VERSION ""

NS_ :

BS_:

BU_: PowertrainControlModule AtmosphericSensor SafetyRestraintSystem2 Aftertreatment_2_GasOutlet Aftertreatment_2_GasIntake DieselParticulateFilterControl Turbocharger SafetyRestraintSystem1 CabDisplay2 Aftertreatment_1_GasOutlet Aftertreatment_1_GasIntake OnBoardDataLogger OffBoardDiagnosticTool2 OffBoardDiagnosticTool1 FileServer ParkingBrakeController SeatController2 FanDriveController SteeringColumnUnit CommunicationUnitRadio CommunicationUnitSatellite CommunicationUnitCellular PropulsionBatteryCharger ChassisController2 ChassisController1 EngineValveControl AuxiliaryHeater2 AuxiliaryHeater1 ClutchUnit RampControl InformationSystem1 SuspensionSystemController2 OilSensor VehicleDynamicStability ExhaustEmissionController TransmissionDisplay2 TransmissionDisplay1 ClimateControl2 WaterPumpController RearAxleSteeringController LightingOperatorControl SeatController1 IgnitionController2 IgnitionController1 TirePressureController CabController2 CabController1 PneumaticSystemController SuspensionSystemController1 HydraulicPumpController EnduranceBrakingSystem RetarderExhaustEngine2 OnBoardDiagnosticUnit HeadwayController RetarderExhaustEngine1 CabDisplay1 ManagementComputer VirtualTerminal OffVehicleGateway PowerTakeOffFront HitchControl AuxiliaryValveControl BodyController TractorTrailerBridge1 StarterSystem ElectricalSystem VehicleSecurity VehicleNavigation AerodynamicControl ElectricalChargingSystem ClimateControl1 TripRecorder InstrumentCluster SuspensionDriveAxle2 SuspensionDriveAxle1 SuspensionSteerAxle SteeringController FuelSystem CruiseControl RetarderDriveline RetarderEngine BrakesDriveAxle2 BrakesDriveAxle1 BrakesSystemController BrakesSteerAxle AxleDrive2 AxleDrive1 AxleSteering PowerTakeOff ShiftConsoleSecondary ShiftConsolePrimary Transmission2 Transmission1 Engine2 Engine1

BO_ 2566845694 TIRE: 8 Vector__XXX
 SG_ TirePressThresholdDetection_13 m19 : 61|3@1+ (1,0) [0|7] "" Vector__XXX
 SG_ TirePressThresholdDetection_12 m18 : 61|3@1+ (1,0) [0|7] "" Vector__XXX
 SG_ TirePressThresholdDetection_11 m17 : 61|3@1+ (1,0) [0|7] "" Vector__XXX
 SG_ TirePressThresholdDetection_10 m16 : 61|3@1+ (1,0) [0|7] "" Vector__XXX
 SG_ TirePressThresholdDetection_01 m1 : 61|3@1+ (1,0) [0|7] "" Vector__XXX
 SG_ TirePress_33 m51 : 8|8@1+ (4,0) [0|1000] "kPa" Vector__XXX
 SG_ TirePress_32 m50 : 8|8@1+ (4,0) [0|1000] "kPa" Vector__XXX
 SG_ TirePress_31 m49 : 8|8@1+ (4,0) [0|1000] "kPa" Vector__XXX
 SG_ TirePress_30 m48 : 8|8@1+ (4,0) [0|1000] "kPa" Vector__XXX
 SG_ TirePress_23 m35 : 8|8@1+ (4,0) [0|1000] "kPa" Vector__XXX
 SG_ TirePress_22 m34 : 8|8@1+ (4,0) [0|1000] "kPa" Vector__XXX
 SG_ TirePress_21 m33 : 8|8@1+ (4,0) [0|1000] "kPa" Vector__XXX
 SG_ TirePress_20 m32 : 8|8@1+ (4,0) [0|1000] "kPa" Vector__XXX
 SG_ TirePress_13 m19 : 8|8@1+ (4,0) [0|1000] "kPa" Vector__XXX
 SG_ TirePress_12 m18 : 8|8@1+ (4,0) [0|1000] "kPa" Vector__XXX
 SG_ TirePress_11 m17 : 8|8@1+ (4,0) [0|1000] "kPa" Vector__XXX
 SG_ TirePress_10 m16 : 8|8@1+ (4,0) [0|1000] "kPa" Vector__XXX
 SG_ TireAirLeakageRate_33 m51 : 40|16@1+ (0.1,0) [0|6425.5] "Pa/s" Vector__XXX
 SG_ TireAirLeakageRate_32 m50 : 40|16@1+ (0.1,0) [0|6425.5] "Pa/s" Vector__XXX
 SG_ TireAirLeakageRate_31 m49 : 40|16@1+ (0.1,0) [0|6425.5] "Pa/s" Vector__XXX
 SG_ TireAirLeakageRate_30 m48 : 40|16@1+ (0.1,0) [0|6425.5] "Pa/s" Vector__XXX
 SG_ TireAirLeakageRate_23 m35 : 40|16@1+ (0.1,0) [0|6425.5] "Pa/s" Vector__XXX
 SG_ TireAirLeakageRate_22 m34 : 40|16@1+ (0.1,0) [0|6425.5] "Pa/s" Vector__XXX
 SG_ TireAirLeakageRate_21 m33 : 40|16@1+ (0.1,0) [0|6425.5] "Pa/s" Vector__XXX
 SG_ TireAirLeakageRate_20 m32 : 40|16@1+ (0.1,0) [0|6425.5] "Pa/s" Vector__XXX
 SG_ TireAirLeakageRate_13 m19 : 40|16@1+ (0.1,0) [0|6425.5] "Pa/s" Vector__XXX
 SG_ TireAirLeakageRate_12 m18 : 40|16@1+ (0.1,0) [0|6425.5] "Pa/s" Vector__XXX
 SG_ TireAirLeakageRate_11 m17 : 40|16@1+ (0.1,0) [0|6425.5] "Pa/s" Vector__XXX
 SG_ TireAirLeakageRate_10 m16 : 40|16@1+ (0.1,0) [0|6425.5] "Pa/s" Vector__XXX
 SG_ TireAirLeakageRate_01 m1 : 40|16@1+ (0.1,0) [0|6425.5] "Pa/s" Vector__XXX
 SG_ TireAirLeakageRate_00 m0 : 40|16@1+ (0.1,0) [0|6425.5] "Pa/s" Vector__XXX
 SG_ CTIWheelSensorStatus_33 m51 : 32|2@1+ (1,0) [0|3] "" Vector__XXX
 SG_ CTIWheelSensorStatus_32 m50 : 32|2@1+ (1,0) [0|3] "" Vector__XXX
 SG_ CTIWheelSensorStatus_31 m49 : 32|2@1+ (1,0) [0|3] "" Vector__XXX
 SG_ CTIWheelSensorStatus_30 m48 : 32|2@1+ (1,0) [0|3] "" Vector__XXX
 SG_ CTIWheelSensorStatus_23 m35 : 32|2@1+ (1,0) [0|3] "" Vector__XXX
 SG_ CTIWheelSensorStatus_22 m34 : 32|2@1+ (1,0) [0|3] "" Vector__XXX
 SG_ CTIWheelSensorStatus_21 m33 : 32|2@1+ (1,0) [0|3] "" Vector__XXX
 SG_ CTIWheelSensorStatus_20 m32 : 32|2@1+ (1,0) [0|3] "" Vector__XXX
 SG_ CTIWheelSensorStatus_13 m19 : 32|2@1+ (1,0) [0|3] "" Vector__XXX
 SG_ CTIWheelSensorStatus_12 m18 : 32|2@1+ (1,0) [0|3] "" Vector__XXX
 SG_ CTIWheelSensorStatus_11 m17 : 32|2@1+ (1,0) [0|3] "" Vector__XXX
 SG_ CTIWheelSensorStatus_10 m16 : 32|2@1+ (1,0) [0|3] "" Vector__XXX
 SG_ CTIWheelSensorStatus_01 m1 : 32|2@1+ (1,0) [0|3] "" Vector__XXX
 SG_ CTIWheelEndElectricalFault_33 m51 : 36|2@1+ (1,0) [0|3] "" Vector__XXX
 SG_ CTIWheelEndElectricalFault_32 m50 : 36|2@1+ (1,0) [0|3] "" Vector__XXX
 SG_ CTIWheelEndElectricalFault_31 m49 : 36|2@1+ (1,0) [0|3] "" Vector__XXX
 SG_ CTIWheelEndElectricalFault_30 m48 : 36|2@1+ (1,0) [0|3] "" Vector__XXX
 SG_ CTIWheelEndElectricalFault_23 m35 : 36|2@1+ (1,0) [0|3] "" Vector__XXX
 SG_ CTIWheelEndElectricalFault_22 m34 : 36|2@1+ (1,0) [0|3] "" Vector__XXX
 SG_ CTIWheelEndElectricalFault_21 m33 : 36|2@1+ (1,0) [0|3] "" Vector__XXX
 SG_ CTIWheelEndElectricalFault_20 m32 : 36|2@1+ (1,0) [0|3] "" Vector__XXX
 SG_ CTIWheelEndElectricalFault_13 m19 : 36|2@1+ (1,0) [0|3] "" Vector__XXX
 SG_ CTIWheelEndElectricalFault_12 m18 : 36|2@1+ (1,0) [0|3] "" Vector__XXX
 SG_ CTIWheelEndElectricalFault_11 m17 : 36|2@1+ (1,0) [0|3] "" Vector__XXX
 SG_ CTIWheelEndElectricalFault_10 m16 : 36|2@1+ (1,0) [0|3] "" Vector__XXX
 SG_ CTIWheelEndElectricalFault_01 m1 : 36|2@1+ (1,0) [0|3] "" Vector__XXX
 SG_ CTITireStatus_33 m51 : 34|2@1+ (1,0) [0|3] "" Vector__XXX
 SG_ CTITireStatus_32 m50 : 34|2@1+ (1,0) [0|3] "" Vector__XXX
 SG_ CTITireStatus_31 m49 : 34|2@1+ (1,0) [0|3] "" Vector__XXX
 SG_ CTITireStatus_30 m48 : 34|2@1+ (1,0) [0|3] "" Vector__XXX
 SG_ CTITireStatus_23 m35 : 34|2@1+ (1,0) [0|3] "" Vector__XXX
 SG_ CTITireStatus_22 m34 : 34|2@1+ (1,0) [0|3] "" Vector__XXX
 SG_ CTITireStatus_21 m33 : 34|2@1+ (1,0) [0|3] "" Vector__XXX
 SG_ CTITireStatus_20 m32 : 34|2@1+ (1,0) [0|3] "" Vector__XXX
 SG_ CTITireStatus_13 m19 : 34|2@1+ (1,0) [0|3] "" Vector__XXX
 SG_ CTITireStatus_12 m18 : 34|2@1+ (1,0) [0|3] "" Vector__XXX
 SG_ CTITireStatus_11 m17 : 34|2@1+ (1,0) [0|3] "" Vector__XXX
 SG_ CTITireStatus_10 m16 : 34|2@1+ (1,0) [0|3] "" Vector__XXX
 SG_ CTITireStatus_01 m1 : 34|2@1+ (1,0) [0|3] "" Vector__XXX
 SG_ TireTemp_11 m17 : 16|16@1+ (0.03125,-273) [-273|1735] "°C" Vector__XXX
 SG_ TireTemp_33 m51 : 16|16@1+ (0.03125,-273) [-273|1735] "°C" Vector__XXX
 SG_ TireTemp_32 m50 : 16|16@1+ (0.03125,-273) [-273|1735] "°C" Vector__XXX
 SG_ TireTemp_31 m49 : 16|16@1+ (0.03125,-273) [-273|1735] "°C" Vector__XXX
 SG_ TireTemp_30 m48 : 16|16@1+ (0.03125,-273) [-273|1735] "°C" Vector__XXX
 SG_ TireTemp_23 m35 : 16|16@1+ (0.03125,-273) [-273|1735] "°C" Vector__XXX
 SG_ TireTemp_22 m34 : 16|16@1+ (0.03125,-273) [-273|1735] "°C" Vector__XXX
 SG_ TireTemp_21 m33 : 16|16@1+ (0.03125,-273) [-273|1735] "°C" Vector__XXX
 SG_ TireTemp_20 m32 : 16|16@1+ (0.03125,-273) [-273|1735] "°C" Vector__XXX
 SG_ TireTemp_13 m19 : 16|16@1+ (0.03125,-273) [-273|1735] "°C" Vector__XXX
 SG_ TireTemp_12 m18 : 16|16@1+ (0.03125,-273) [-273|1735] "°C" Vector__XXX
 SG_ TireTemp_10 m16 : 16|16@1+ (0.03125,-273) [-273|1735] "°C" Vector__XXX
 SG_ TireTemp_01 m1 : 16|16@1+ (0.03125,-273) [-273|1735] "°C" Vector__XXX
 SG_ TireTemp_00 m0 : 16|16@1+ (0.03125,-273) [-273|1735] "°C" Vector__XXX
 SG_ TirePressThresholdDetection_33 m51 : 61|3@1+ (1,0) [0|7] "" Vector__XXX
 SG_ TirePressThresholdDetection_32 m50 : 61|3@1+ (1,0) [0|7] "" Vector__XXX
 SG_ TirePressThresholdDetection_31 m49 : 61|3@1+ (1,0) [0|7] "" Vector__XXX
 SG_ TirePressThresholdDetection_30 m48 : 61|3@1+ (1,0) [0|7] "" Vector__XXX
 SG_ TirePressThresholdDetection_23 m35 : 61|3@1+ (1,0) [0|7] "" Vector__XXX
 SG_ TirePressThresholdDetection_22 m34 : 61|3@1+ (1,0) [0|7] "" Vector__XXX
 SG_ TirePressThresholdDetection_21 m33 : 61|3@1+ (1,0) [0|7] "" Vector__XXX
 SG_ TirePressThresholdDetection_20 m32 : 61|3@1+ (1,0) [0|7] "" Vector__XXX
 SG_ TirePressThresholdDetection_00 m0 : 61|3@1+ (1,0) [0|7] "" Vector__XXX
 SG_ TirePress_01 m1 : 8|8@1+ (4,0) [0|1000] "kPa" Vector__XXX
 SG_ TirePress_00 m0 : 8|8@1+ (4,0) [0|1000] "kPa" Vector__XXX
 SG_ CTIWheelSensorStatus_00 m0 : 32|2@1+ (1,0) [0|3] "" Vector__XXX
 SG_ CTIWheelEndElectricalFault_00 m0 : 36|2@1+ (1,0) [0|3] "" Vector__XXX
 SG_ CTITireStatus_00 m0 : 34|2@1+ (1,0) [0|3] "" Vector__XXX
 SG_ TireLocation M : 0|8@1+ (1,0) [0|255] "" Vector__XXX

BO_ 2633939966 TFI: 16 Vector__XXX
 SG_ TripFanOnTimeDueToTheA_CSystem : 96|32@1+ (0.05,0) [0|210554060.75] "h" Vector__XXX
 SG_ TripFanOnTimeDueToAManualSwitch : 64|32@1+ (0.05,0) [0|210554060.75] "h" Vector__XXX
 SG_ TripFanOnTimeDueToTheEngSystem : 32|32@1+ (0.05,0) [0|210554060.75] "h" Vector__XXX
 SG_ TripFanOnTime : 0|32@1+ (0.05,0) [0|210554060.75] "h" Vector__XXX

BO_ 2633939710 TDI: 12 Vector__XXX
 SG_ TripDistanceInTopGear : 64|32@1+ (0.125,0) [0|526385151.875] "km" Vector__XXX
 SG_ TripGearDownDistance : 32|32@1+ (0.125,0) [0|526385151.875] "km" Vector__XXX
 SG_ TripDistanceOnVSL : 0|32@1+ (0.125,0) [0|526385151.875] "km" Vector__XXX

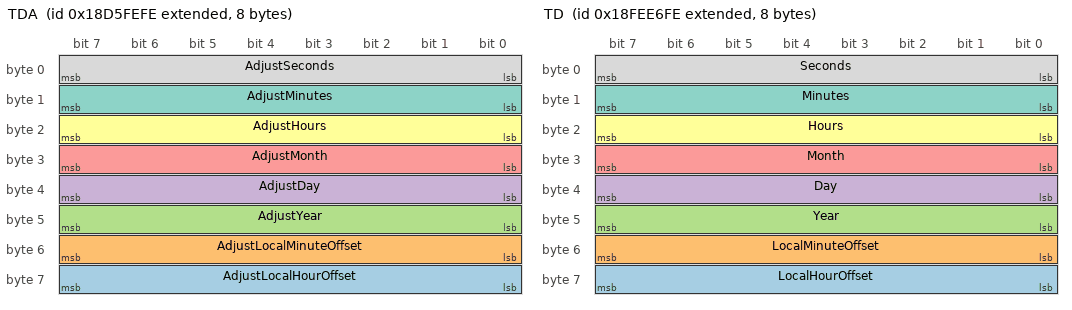
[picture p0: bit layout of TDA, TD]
BO_ 2564161278 TDA: 8 Vector__XXX
 SG_ AdjustLocalHourOffset : 56|8@1+ (1,-125) [-24|23] "h" Vector__XXX
 SG_ AdjustLocalMinuteOffset : 48|8@1+ (1,-125) [-59|59] "min" Vector__XXX
 SG_ AdjustYear : 40|8@1+ (1,1985) [1985|2235] "years" Vector__XXX
 SG_ AdjustDay : 32|8@1+ (0.25,0) [0.25|31.75] "days" Vector__XXX
 SG_ AdjustMonth : 24|8@1+ (1,0) [1|12] "months" Vector__XXX
 SG_ AdjustHours : 16|8@1+ (1,0) [0|23] "h" Vector__XXX
 SG_ AdjustMinutes : 8|8@1+ (1,0) [0|59] "min" Vector__XXX
 SG_ AdjustSeconds : 0|8@1+ (0.25,0) [0|59.75] "s" Vector__XXX

BO_ 2566842110 TD: 8 Vector__XXX
 SG_ LocalHourOffset : 56|8@1+ (1,-125) [-23|23] "h" Vector__XXX
 SG_ LocalMinuteOffset : 48|8@1+ (1,-125) [-59|59] "min" Vector__XXX
 SG_ Year : 40|8@1+ (1,1985) [1985|2235] "years" Vector__XXX
 SG_ Day : 32|8@1+ (0.25,0) [0.25|31.75] "days" Vector__XXX
 SG_ Month : 24|8@1+ (1,0) [1|12] "months" Vector__XXX
 SG_ Hours : 16|8@1+ (1,0) [0|23] "h" Vector__XXX
 SG_ Minutes : 8|8@1+ (1,0) [0|59] "min" Vector__XXX
 SG_ Seconds : 0|8@1+ (0.25,0) [0|59.75] "s" Vector__XXX

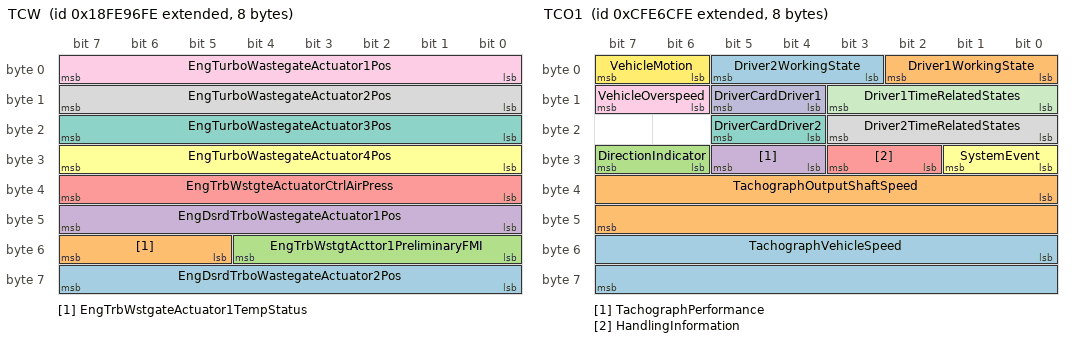
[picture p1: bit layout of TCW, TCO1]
BO_ 2566821630 TCW: 8 Vector__XXX
 SG_ EngDsrdTrboWastegateActuator2Pos : 56|8@1+ (0.4,0) [0|100] "%" Vector__XXX
 SG_ EngTrbWstgateActuator1TempStatus : 53|3@1+ (1,0) [0|7] "" Vector__XXX
 SG_ EngTrbWstgtActtor1PreliminaryFMI : 48|5@1+ (1,0) [0|31] "" Vector__XXX
 SG_ EngDsrdTrboWastegateActuator1Pos : 40|8@1+ (0.4,0) [0|100] "%" Vector__XXX
 SG_ EngTrbWstgteActuatorCtrlAirPress : 32|8@1+ (4,0) [0|1000] "kPa" Vector__XXX
 SG_ EngTurboWastegateActuator4Pos : 24|8@1+ (0.4,0) [0|100] "%" Vector__XXX
 SG_ EngTurboWastegateActuator3Pos : 16|8@1+ (0.4,0) [0|100] "%" Vector__XXX
 SG_ EngTurboWastegateActuator2Pos : 8|8@1+ (0.4,0) [0|100] "%" Vector__XXX
 SG_ EngTurboWastegateActuator1Pos : 0|8@1+ (0.4,0) [0|100] "%" Vector__XXX

BO_ 2365484286 TCO1: 8 Vector__XXX
 SG_ TachographVehicleSpeed : 48|16@1+ (0.00390625,0) [0|250.996] "km/h" Vector__XXX
 SG_ TachographOutputShaftSpeed : 32|16@1+ (0.125,0) [0|8031.875] "rpm" Vector__XXX
 SG_ DirectionIndicator : 30|2@1+ (1,0) [0|3] "" Vector__XXX
 SG_ TachographPerformance : 28|2@1+ (1,0) [0|3] "" Vector__XXX
 SG_ HandlingInformation : 26|2@1+ (1,0) [0|3] "" Vector__XXX
 SG_ SystemEvent : 24|2@1+ (1,0) [0|3] "" Vector__XXX
 SG_ DriverCardDriver2 : 20|2@1+ (1,0) [0|3] "" Vector__XXX
 SG_ Driver2TimeRelatedStates : 16|4@1+ (1,0) [0|15] "" Vector__XXX
 SG_ VehicleOverspeed : 14|2@1+ (1,0) [0|3] "" Vector__XXX
 SG_ DriverCardDriver1 : 12|2@1+ (1,0) [0|3] "" Vector__XXX
 SG_ Driver1TimeRelatedStates : 8|4@1+ (1,0) [0|15] "" Vector__XXX
 SG_ VehicleMotion : 6|2@1+ (1,0) [0|3] "" Vector__XXX
 SG_ Driver2WorkingState : 3|3@1+ (1,0) [0|7] "" Vector__XXX
 SG_ Driver1WorkingState : 0|3@1+ (1,0) [0|7] "" Vector__XXX

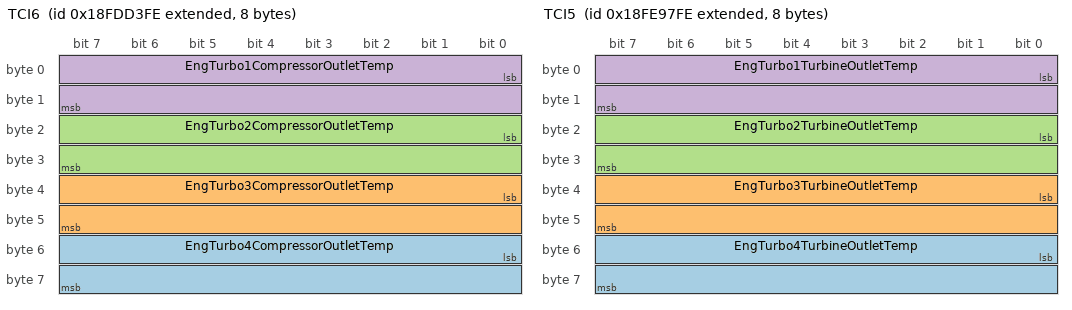
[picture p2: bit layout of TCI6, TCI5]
BO_ 2566771710 TCI6: 8 Vector__XXX
 SG_ EngTurbo4CompressorOutletTemp : 48|16@1+ (0.03125,-273) [-273|1734.96875] "°C" Vector__XXX
 SG_ EngTurbo3CompressorOutletTemp : 32|16@1+ (0.03125,-273) [-273|1734.96875] "°C" Vector__XXX
 SG_ EngTurbo2CompressorOutletTemp : 16|16@1+ (0.03125,-273) [-273|1734.96875] "°C" Vector__XXX
 SG_ EngTurbo1CompressorOutletTemp : 0|16@1+ (0.03125,-273) [-273|1734.96875] "°C" Vector__XXX

BO_ 2566821886 TCI5: 8 Vector__XXX
 SG_ EngTurbo4TurbineOutletTemp : 48|16@1+ (0.03125,-273) [-273|1734.96875] "°C" Vector__XXX
 SG_ EngTurbo3TurbineOutletTemp : 32|16@1+ (0.03125,-273) [-273|1734.96875] "°C" Vector__XXX
 SG_ EngTurbo2TurbineOutletTemp : 16|16@1+ (0.03125,-273) [-273|1734.96875] "°C" Vector__XXX
 SG_ EngTurbo1TurbineOutletTemp : 0|16@1+ (0.03125,-273) [-273|1734.96875] "°C" Vector__XXX

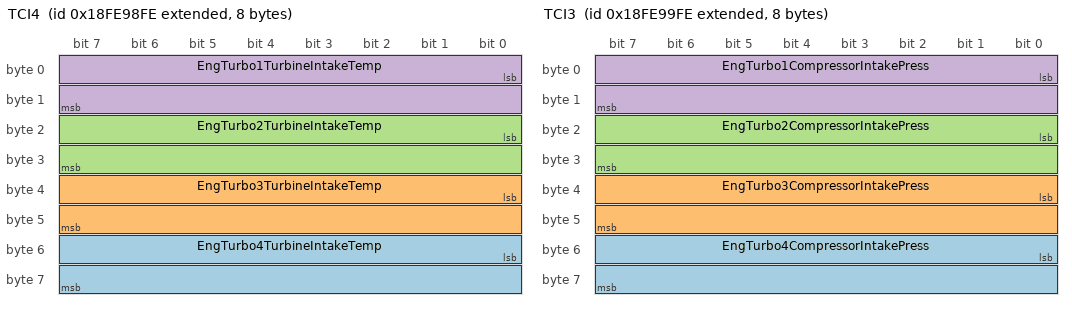
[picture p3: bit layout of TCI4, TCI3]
BO_ 2566822142 TCI4: 8 Vector__XXX
 SG_ EngTurbo4TurbineIntakeTemp : 48|16@1+ (0.03125,-273) [-273|1734.96875] "°C" Vector__XXX
 SG_ EngTurbo3TurbineIntakeTemp : 32|16@1+ (0.03125,-273) [-273|1734.96875] "°C" Vector__XXX
 SG_ EngTurbo2TurbineIntakeTemp : 16|16@1+ (0.03125,-273) [-273|1734.96875] "°C" Vector__XXX
 SG_ EngTurbo1TurbineIntakeTemp : 0|16@1+ (0.03125,-273) [-273|1734.96875] "°C" Vector__XXX

BO_ 2566822398 TCI3: 8 Vector__XXX
 SG_ EngTurbo4CompressorIntakePress : 48|16@1+ (0.0078125,-250) [-250|251.99] "kPa" Vector__XXX
 SG_ EngTurbo3CompressorIntakePress : 32|16@1+ (0.0078125,-250) [-250|251.99] "kPa" Vector__XXX
 SG_ EngTurbo2CompressorIntakePress : 16|16@1+ (0.0078125,-250) [-250|251.99] "kPa" Vector__XXX
 SG_ EngTurbo1CompressorIntakePress : 0|16@1+ (0.0078125,-250) [-250|251.99] "kPa" Vector__XXX

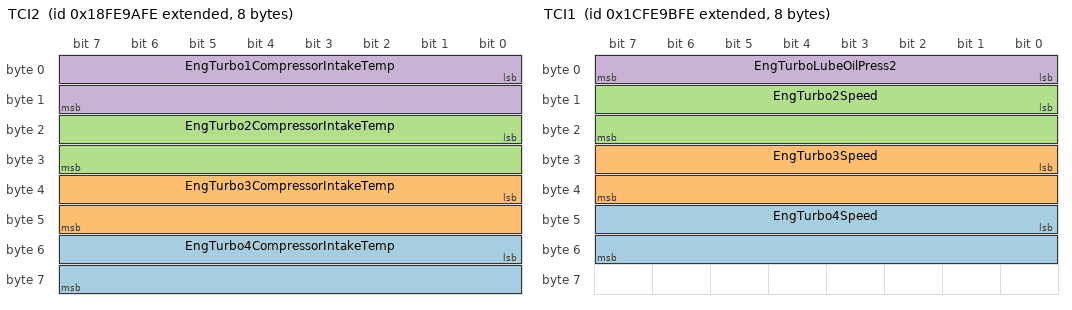
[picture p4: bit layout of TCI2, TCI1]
BO_ 2566822654 TCI2: 8 Vector__XXX
 SG_ EngTurbo4CompressorIntakeTemp : 48|16@1+ (0.03125,-273) [-273|1734.96875] "°C" Vector__XXX
 SG_ EngTurbo3CompressorIntakeTemp : 32|16@1+ (0.03125,-273) [-273|1734.96875] "°C" Vector__XXX
 SG_ EngTurbo2CompressorIntakeTemp : 16|16@1+ (0.03125,-273) [-273|1734.96875] "°C" Vector__XXX
 SG_ EngTurbo1CompressorIntakeTemp : 0|16@1+ (0.03125,-273) [-273|1734.96875] "°C" Vector__XXX

BO_ 2633931774 TCI1: 8 Vector__XXX
 SG_ EngTurbo4Speed : 40|16@1+ (4,0) [0|257020] "rpm" Vector__XXX
 SG_ EngTurbo3Speed : 24|16@1+ (4,0) [0|257020] "rpm" Vector__XXX
 SG_ EngTurbo2Speed : 8|16@1+ (4,0) [0|257020] "rpm" Vector__XXX
 SG_ EngTurboLubeOilPress2 : 0|8@1+ (4,0) [0|1000] "kPa" Vector__XXX

BO_ 2566802430 TCFG2: 8 Vector__XXX
 SG_ TransTorqueLimit : 0|16@1+ (1,0) [0|64255] "Nm" Vector__XXX

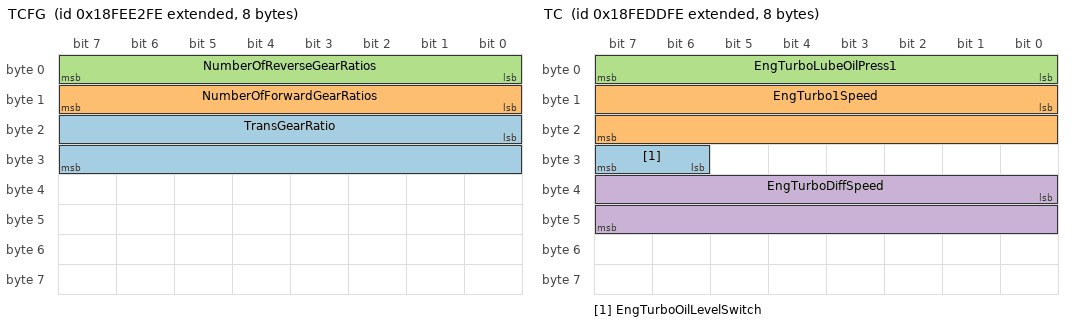
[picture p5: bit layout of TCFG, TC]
BO_ 2566841086 TCFG: 8 Vector__XXX
 SG_ TransGearRatio : 16|16@1+ (0.001,0) [0|64.255] "" Vector__XXX
 SG_ NumberOfForwardGearRatios : 8|8@1+ (1,0) [0|125] "" Vector__XXX
 SG_ NumberOfReverseGearRatios : 0|8@1+ (1,0) [0|125] "" Vector__XXX

BO_ 2348941054 TC1: 8 Vector__XXX
 SG_ TransMode8 : 62|2@1+ (1,0) [0|3] "" Vector__XXX
 SG_ TransMode7 : 60|2@1+ (1,0) [0|3] "" Vector__XXX
 SG_ TransMode6 : 58|2@1+ (1,0) [0|3] "" Vector__XXX
 SG_ TransMode5 : 56|2@1+ (1,0) [0|3] "" Vector__XXX
 SG_ TrnsShftSlectorDisplayModeSwitch : 54|2@1+ (1,0) [0|3] "" Vector__XXX
 SG_ TransRequestedLaunchGear : 50|4@1+ (1,0) [0|15] "" Vector__XXX
 SG_ TransMode4 : 46|2@1+ (1,0) [0|3] "" Vector__XXX
 SG_ TransMode3 : 44|2@1+ (1,0) [0|3] "" Vector__XXX
 SG_ TransMode2 : 42|2@1+ (1,0) [0|3] "" Vector__XXX
 SG_ TransMode1 : 40|2@1+ (1,0) [0|3] "" Vector__XXX
 SG_ TransLoadReductionInhibitRq : 38|2@1+ (1,0) [0|3] "" Vector__XXX
 SG_ DisengageDiffLockRqCentralRear : 36|2@1+ (1,0) [0|3] "" Vector__XXX
 SG_ DisengageDiffLockRqCentralFront : 34|2@1+ (1,0) [0|3] "" Vector__XXX
 SG_ DisengageDiffLockRqCentral : 32|2@1+ (1,0) [0|3] "" Vector__XXX
 SG_ DisengageDiffLockRqRearAxle2 : 30|2@1+ (1,0) [0|3] "" Vector__XXX
 SG_ DisengageDiffLockRqRearAxle1 : 28|2@1+ (1,0) [0|3] "" Vector__XXX
 SG_ DisengageDiffLockRqFrontAxle2 : 26|2@1+ (1,0) [0|3] "" Vector__XXX
 SG_ DisengageDiffLockRqFrontAxle1 : 24|2@1+ (1,0) [0|3] "" Vector__XXX
 SG_ TransRequestedGear : 16|8@1+ (1,-125) [-64|64] "" Vector__XXX
 SG_ RequestedPercentClutchSlip : 8|8@1+ (0.4,0) [0|100] "%" Vector__XXX
 SG_ TransReverseGearShiftInhibitRq : 6|2@1+ (1,0) [0|3] "" Vector__XXX
 SG_ DisengageDrivelineRq : 4|2@1+ (1,0) [0|3] "" Vector__XXX
 SG_ TrnsTrqeConverterLockupDisableRq : 2|2@1+ (1,0) [0|3] "" Vector__XXX
 SG_ TransGearShiftInhibitRq : 0|2@1+ (1,0) [0|3] "" Vector__XXX

BO_ 2566839806 TC: 8 Vector__XXX
 SG_ EngTurboOilLevelSwitch : 30|2@1+ (1,0) [0|3] "" Vector__XXX
 SG_ EngTurbo1Speed : 8|16@1+ (4,0) [0|257020] "rpm" Vector__XXX
 SG_ EngTurboLubeOilPress1 : 0|8@1+ (4,0) [0|1000] "kPa" Vector__XXX
 SG_ EngTurboDiffSpeed : 32|16@1+ (4,0) [0|257020] "rpm" Vector__XXX

BO_ 2633911806 TAVG: 8 Vector__XXX
 SG_ EngTotalAverageFuelEconomy : 16|16@1+ (0.001953125,0) [0|125.498046875] "km/L" Vector__XXX
 SG_ EngTotalAverageFuelRate : 0|16@1+ (0.05,0) [0|3212.75] "L/h" Vector__XXX

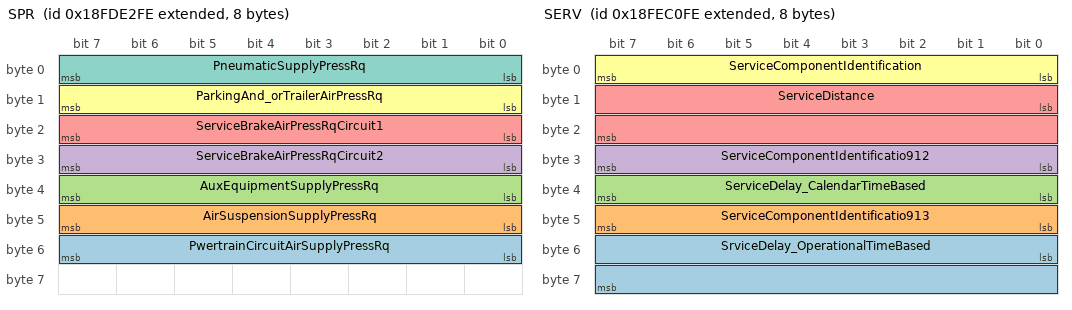
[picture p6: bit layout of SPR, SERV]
BO_ 2566775550 SPR: 8 Vector__XXX
 SG_ PwertrainCircuitAirSupplyPressRq : 48|8@1+ (8,0) [0|2000] "kPa" Vector__XXX
 SG_ AirSuspensionSupplyPressRq : 40|8@1+ (8,0) [0|2000] "kPa" Vector__XXX
 SG_ AuxEquipmentSupplyPressRq : 32|8@1+ (8,0) [0|2000] "kPa" Vector__XXX
 SG_ ServiceBrakeAirPressRqCircuit2 : 24|8@1+ (8,0) [0|2000] "kPa" Vector__XXX
 SG_ ServiceBrakeAirPressRqCircuit1 : 16|8@1+ (8,0) [0|2000] "kPa" Vector__XXX
 SG_ ParkingAnd_orTrailerAirPressRq : 8|8@1+ (8,0) [0|2000] "kPa" Vector__XXX
 SG_ PneumaticSupplyPressRq : 0|8@1+ (8,0) [0|2000] "kPa" Vector__XXX

BO_ 2566819838 SP2: 8 Vector__XXX
 SG_ EngExtlShutdownAirSupplyPress : 0|16@1+ (0.5,0) [0|32127.5] "kPa" Vector__XXX

BO_ 2566838785 SOFT: 12 Vector__XXX
 SG_ feda10 : 88|8@1+ (1,0) [0|0] "" Vector__XXX
 SG_ feda09 : 80|8@1+ (1,0) [0|0] "" Vector__XXX
 SG_ feda08 : 72|8@1+ (1,0) [0|0] "" Vector__XXX
 SG_ feda07 : 64|8@1+ (1,0) [0|0] "" Vector__XXX
 SG_ feda06 : 56|8@1+ (1,0) [0|0] "" Vector__XXX
 SG_ feda05 : 48|8@1+ (1,0) [0|0] "" Vector__XXX
 SG_ feda04 : 40|8@1+ (1,0) [0|0] "" Vector__XXX
 SG_ feda03 : 32|8@1+ (1,0) [0|0] "" Vector__XXX
 SG_ feda02 : 24|8@1+ (1,0) [0|0] "" Vector__XXX
 SG_ feda01 : 16|8@1+ (1,0) [0|0] "" Vector__XXX
 SG_ NmbrOfSftwreIdentificationFields : 0|8@1+ (1,0) [0|125] "steps" Vector__XXX
 SG_ SoftwareIdentification : 8|8@1+ (1,0) [0|255] "" Vector__XXX

BO_ 2566841598 SHUTDN: 8 Vector__XXX
 SG_ ClntLvlEngPrtctionShutdownStatus : 60|2@1+ (1,0) [0|3] "" Vector__XXX
 SG_ PTOShutdownHasShutdownEng : 58|2@1+ (1,0) [0|3] "" Vector__XXX
 SG_ EngAirShutoffStatus : 56|2@1+ (1,0) [0|3] "" Vector__XXX
 SG_ EngOverspeedTest : 54|2@1+ (1,0) [0|3] "" Vector__XXX
 SG_ EngAirShutoffCmdStatus : 52|2@1+ (1,0) [0|3] "" Vector__XXX
 SG_ EngAlarmOutputCmdStatus : 50|2@1+ (1,0) [0|3] "" Vector__XXX
 SG_ EngAlarmAcknowledge : 48|2@1+ (1,0) [0|3] "" Vector__XXX
 SG_ EngProtectionSystemConfig : 46|2@1+ (1,0) [0|3] "" Vector__XXX
 SG_ EngProtectionSystemTimerState : 38|2@1+ (1,0) [0|3] "" Vector__XXX
 SG_ EngProtectionSystemTimerOverride : 36|2@1+ (1,0) [0|3] "" Vector__XXX
 SG_ EngPrtctnSystmApprachingShutdown : 34|2@1+ (1,0) [0|3] "" Vector__XXX
 SG_ EngPrtectionSystemHasShutdownEng : 32|2@1+ (1,0) [0|3] "" Vector__XXX
 SG_ EngWaitToStartLamp : 24|2@1+ (1,0) [0|3] "" Vector__XXX
 SG_ RefrigerantHighPressSwitch : 20|2@1+ (1,0) [0|3] "" Vector__XXX
 SG_ RefrigerantLowPressSwitch : 18|2@1+ (1,0) [0|3] "" Vector__XXX
 SG_ A_CHighPressFanSwitch : 16|2@1+ (1,0) [0|3] "" Vector__XXX
 SG_ EngIdleShutdownTimerFunction : 14|2@1+ (1,0) [0|3] "" Vector__XXX
 SG_ EngIdleShutdownTimerState : 6|2@1+ (1,0) [0|3] "" Vector__XXX
 SG_ EngIdleShutdownTimerOverride : 4|2@1+ (1,0) [0|3] "" Vector__XXX
 SG_ EngIdleShutdownDriverAlertMode : 2|2@1+ (1,0) [0|3] "" Vector__XXX
 SG_ EngIdleShutdownHasShutdownEng : 0|2@1+ (1,0) [0|3] "" Vector__XXX

BO_ 2365459710 WSMEM: 8 Vector__XXX
 SG_ VehicleSystem5 m5 : 49|7@1+ (1,0) [0|127] "" Vector__XXX
 SG_ VehicleSystem4 m4 : 49|7@1+ (1,0) [0|127] "" Vector__XXX
 SG_ VehicleSystem3 m3 : 49|7@1+ (1,0) [0|127] "" Vector__XXX
 SG_ VehicleSystem2 m2 : 49|7@1+ (1,0) [0|127] "" Vector__XXX
 SG_ VehicleSystem1 m1 : 49|7@1+ (1,0) [0|127] "" Vector__XXX
 SG_ ArbitraryAddressCapable : 63|1@1+ (1,0) [0|1] "" Vector__XXX
 SG_ IndustryGroup M : 60|3@1+ (1,0) [0|7] "" Vector__XXX
 SG_ VehicleSystemInstance : 56|4@1+ (1,0) [0|15] "" Vector__XXX
 SG_ VehicleSystem m0 : 49|7@1+ (1,0) [0|127] "" Vector__XXX
 SG_ ECUInstance : 32|3@1+ (1,0) [0|7] "" Vector__XXX
 SG_ FunctionInstance : 35|5@1+ (1,0) [0|31] "" Vector__XXX
 SG_ Function : 40|8@1+ (1,0) [0|255] "" Vector__XXX
 SG_ ManufacturerCode : 21|11@1+ (1,0) [0|2047] "" Vector__XXX
 SG_ IdentityNumber : 0|21@1+ (1,0) [0|2097152] "" Vector__XXX

BO_ 2566832382 SERV: 8 Vector__XXX
 SG_ SrviceDelay_OperationalTimeBased : 48|16@1+ (1,-32127) [-32127|32128] "h" Vector__XXX
 SG_ ServiceComponentIdentificatio913 : 40|8@1+ (1,0) [0|250] "ID" Vector__XXX
 SG_ ServiceDelay_CalendarTimeBased : 32|8@1+ (1,-125) [-125|125] "weeks" Vector__XXX
 SG_ ServiceComponentIdentificatio912 : 24|8@1+ (1,0) [0|250] "ID" Vector__XXX
 SG_ ServiceDistance : 8|16@1+ (5,-160635) [-160635|160640] "km" Vector__XXX
 SG_ ServiceComponentIdentification : 0|8@1+ (1,0) [0|250] "ID" Vector__XXX

BO_ 2633928446 S2: 8 Vector__XXX
 SG_ TimeSinceLastService : 8|16@1+ (1,-32127) [-32127|32128] "h" Vector__XXX
 SG_ ServiceComponentIdentification : 0|8@1+ (1,0) [0|250] "ID" Vector__XXX

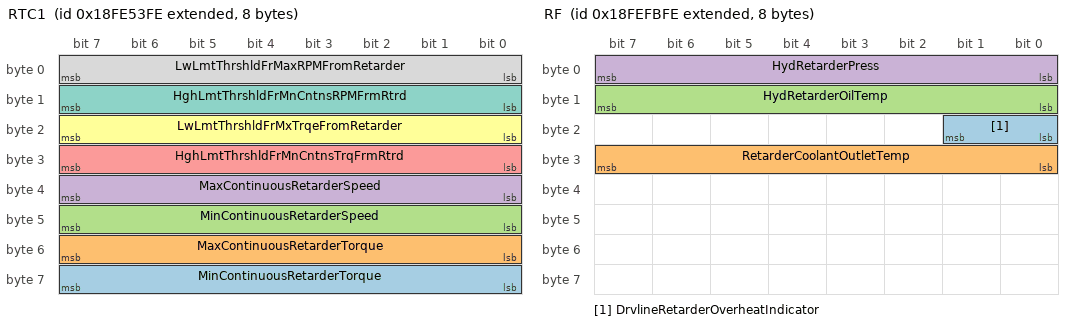
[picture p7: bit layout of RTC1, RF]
BO_ 2566804478 RTC1: 8 Vector__XXX
 SG_ MinContinuousRetarderTorque : 56|8@1+ (1,-125) [-125|125] "%" Vector__XXX
 SG_ MaxContinuousRetarderTorque : 48|8@1+ (1,-125) [-125|125] "%" Vector__XXX
 SG_ MinContinuousRetarderSpeed : 40|8@1+ (32,0) [0|8000] "rpm" Vector__XXX
 SG_ MaxContinuousRetarderSpeed : 32|8@1+ (32,0) [0|8000] "rpm" Vector__XXX
 SG_ HghLmtThrshldFrMnCntnsTrqFrmRtrd : 24|8@1+ (1,-125) [-125|125] "%" Vector__XXX
 SG_ LwLmtThrshldFrMxTrqeFromRetarder : 16|8@1+ (1,-125) [-125|125] "%" Vector__XXX
 SG_ HghLmtThrshldFrMnCntnsRPMFrmRtrd : 8|8@1+ (32,0) [0|8000] "rpm" Vector__XXX
 SG_ LwLmtThrshldFrMaxRPMFromRetarder : 0|8@1+ (32,0) [0|8000] "rpm" Vector__XXX

BO_ 2566847486 RF: 8 Vector__XXX
 SG_ DrvlineRetarderOverheatIndicator : 16|2@1+ (1,0) [0|3] "" Vector__XXX
 SG_ RetarderCoolantOutletTemp : 24|8@1+ (1,-40) [-40|210] "°C" Vector__XXX
 SG_ HydRetarderOilTemp : 8|8@1+ (1,-40) [-40|210] "°C" Vector__XXX
 SG_ HydRetarderPress : 0|8@1+ (16,0) [0|4000] "kPa" Vector__XXX

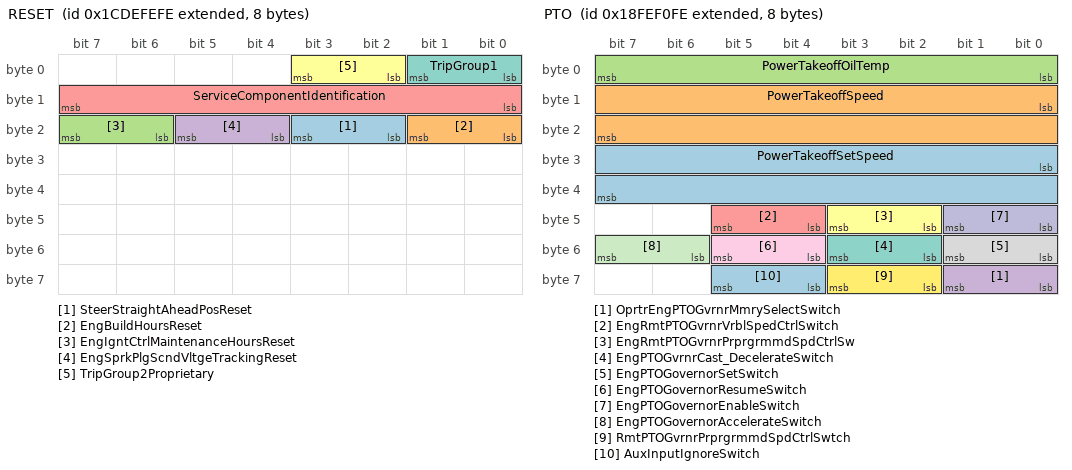
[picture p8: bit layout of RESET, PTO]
BO_ 2631859966 RESET: 8 Vector__XXX
 SG_ SteerStraightAheadPosReset : 18|2@1+ (1,0) [0|3] "" Vector__XXX
 SG_ EngBuildHoursReset : 16|2@1+ (1,0) [0|3] "" Vector__XXX
 SG_ EngIgntCtrlMaintenanceHoursReset : 22|2@1+ (1,0) [0|3] "" Vector__XXX
 SG_ EngSprkPlgScndVltgeTrackingReset : 20|2@1+ (1,0) [0|3] "" Vector__XXX
 SG_ ServiceComponentIdentification : 8|8@1+ (1,0) [0|250] "ID" Vector__XXX
 SG_ TripGroup2Proprietary : 2|2@1+ (1,0) [0|3] "" Vector__XXX
 SG_ TripGroup1 : 0|2@1+ (1,0) [0|3] "" Vector__XXX

BO_ 2566840830 RC: 19 Vector__XXX
 SG_ PercentTorqueAtPeakTorquePoint5 : 144|8@1+ (1,-125) [-125|0] "%" Vector__XXX
 SG_ ReferenceRetarderTorque : 128|16@1+ (1,0) [0|64255] "Nm" Vector__XXX
 SG_ RetarderSpeedAtPeakTorquePoint5 : 112|16@1+ (0.125,0) [0|8031.875] "rpm" Vector__XXX
 SG_ PercentTorqueAtPoint4 : 104|8@1+ (1,-125) [-125|0] "%" Vector__XXX
 SG_ RetarderSpeedAtPoint4 : 88|16@1+ (0.125,0) [0|8031.875] "rpm" Vector__XXX
 SG_ PercentTorqueAtPoint3 : 80|8@1+ (1,-125) [-125|0] "%" Vector__XXX
 SG_ RetarderSpeedAtPoint3 : 64|16@1+ (0.125,0) [0|8031.875] "rpm" Vector__XXX
 SG_ PercentTorqueAtMaxSpeedPoint2 : 56|8@1+ (1,-125) [-125|0] "%" Vector__XXX
 SG_ MaxRetarderSpeedPoint2 : 40|16@1+ (0.125,0) [0|8031.875] "rpm" Vector__XXX
 SG_ PercentTorqueAtIdlePoint1 : 32|8@1+ (1,-125) [-125|0] "%" Vector__XXX
 SG_ RetarderSpeedAtIdlePoint1 : 16|16@1+ (0.125,0) [0|8031.875] "rpm" Vector__XXX
 SG_ RetarderCtrlMethod : 8|8@1+ (1,0) [0|250] "steps" Vector__XXX
 SG_ RetarderLocation : 4|4@1+ (1,0) [0|15] "" Vector__XXX
 SG_ RetarderType : 0|4@1+ (1,0) [0|15] "" Vector__XXX

BO_ 2633930238 RBI: 8 Vector__XXX
 SG_ EngOperationTimeSinceRebuild : 0|32@1+ (1,0) [0|4211081215] "s" Vector__XXX

BO_ 2566844670 PTO: 8 Vector__XXX
 SG_ PowerTakeoffSetSpeed : 24|16@1+ (0.125,0) [0|8031.875] "rpm" Vector__XXX
 SG_ PowerTakeoffSpeed : 8|16@1+ (0.125,0) [0|8031.875] "rpm" Vector__XXX
 SG_ PowerTakeoffOilTemp : 0|8@1+ (1,-40) [-40|210] "°C" Vector__XXX
 SG_ OprtrEngPTOGvrnrMmrySelectSwitch : 56|2@1+ (1,0) [0|3] "" Vector__XXX
 SG_ EngRmtPTOGvrnrVrblSpedCtrlSwitch : 44|2@1+ (1,0) [0|3] "" Vector__XXX
 SG_ EngRmtPTOGvrnrPrprgrmmdSpdCtrlSw : 42|2@1+ (1,0) [0|3] "" Vector__XXX
 SG_ EngPTOGvrnrCast_DecelerateSwitch : 50|2@1+ (1,0) [0|3] "" Vector__XXX
 SG_ EngPTOGovernorSetSwitch : 48|2@1+ (1,0) [0|3] "" Vector__XXX
 SG_ EngPTOGovernorResumeSwitch : 52|2@1+ (1,0) [0|3] "" Vector__XXX
 SG_ EngPTOGovernorEnableSwitch : 40|2@1+ (1,0) [0|3] "" Vector__XXX
 SG_ EngPTOGovernorAccelerateSwitch : 54|2@1+ (1,0) [0|3] "" Vector__XXX
 SG_ RmtPTOGvrnrPrprgrmmdSpdCtrlSwtch : 58|2@1+ (1,0) [0|3] "" Vector__XXX
 SG_ AuxInputIgnoreSwitch : 60|2@1+ (1,0) [0|3] "" Vector__XXX

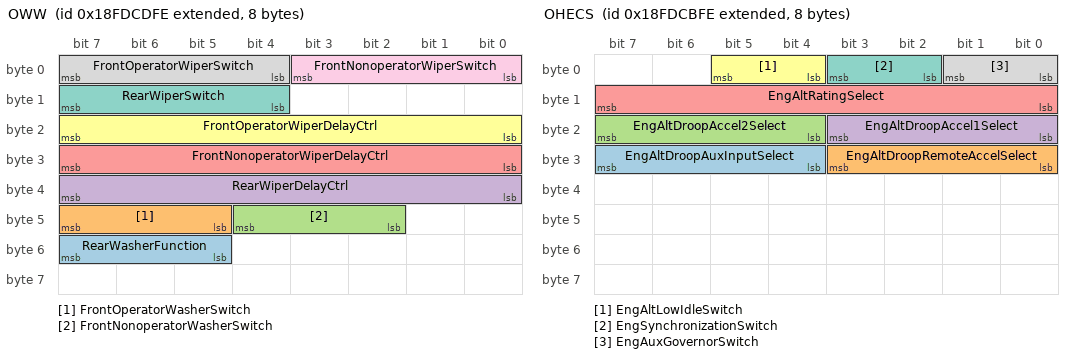
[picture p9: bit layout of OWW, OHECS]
BO_ 2566770174 OWW: 8 Vector__XXX
 SG_ RearWasherFunction : 53|3@1+ (1,0) [0|7] "" Vector__XXX
 SG_ FrontOperatorWasherSwitch : 45|3@1+ (1,0) [0|7] "" Vector__XXX
 SG_ FrontNonoperatorWasherSwitch : 42|3@1+ (1,0) [0|7] "" Vector__XXX
 SG_ RearWiperDelayCtrl : 32|8@1+ (0.4,0) [0|100] "%" Vector__XXX
 SG_ FrontNonoperatorWiperDelayCtrl : 24|8@1+ (0.4,0) [0|100] "%" Vector__XXX
 SG_ FrontOperatorWiperDelayCtrl : 16|8@1+ (0.4,0) [0|100] "%" Vector__XXX
 SG_ RearWiperSwitch : 12|4@1+ (1,0) [0|15] "" Vector__XXX
 SG_ FrontOperatorWiperSwitch : 4|4@1+ (1,0) [0|15] "" Vector__XXX
 SG_ FrontNonoperatorWiperSwitch : 0|4@1+ (1,0) [0|15] "" Vector__XXX

BO_ 2566769662 OHECS: 8 Vector__XXX
 SG_ EngAltDroopAuxInputSelect : 28|4@1+ (1,0) [0|15] "" Vector__XXX
 SG_ EngAltDroopRemoteAccelSelect : 24|4@1+ (1,0) [0|15] "" Vector__XXX
 SG_ EngAltDroopAccel2Select : 20|4@1+ (1,0) [0|15] "" Vector__XXX
 SG_ EngAltDroopAccel1Select : 16|4@1+ (1,0) [0|15] "" Vector__XXX
 SG_ EngAltRatingSelect : 8|8@1+ (1,0) [0|255] "" Vector__XXX
 SG_ EngAltLowIdleSwitch : 4|2@1+ (1,0) [0|3] "" Vector__XXX
 SG_ EngSynchronizationSwitch : 2|2@1+ (1,0) [0|3] "" Vector__XXX
 SG_ EngAuxGovernorSwitch : 0|2@1+ (1,0) [0|3] "" Vector__XXX

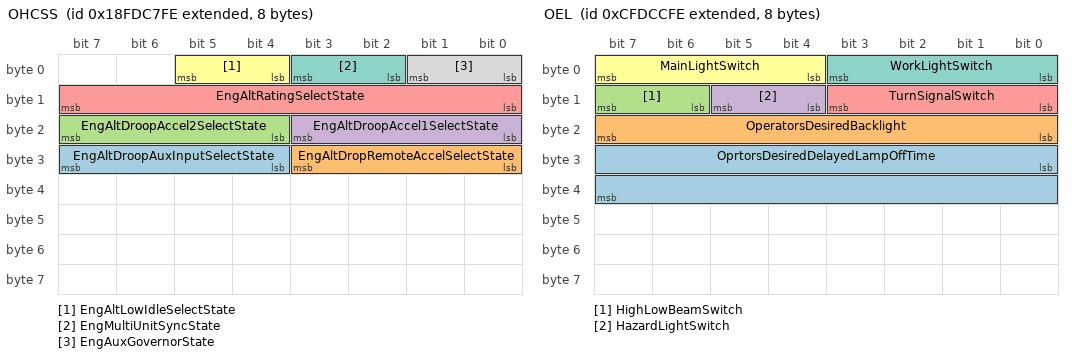
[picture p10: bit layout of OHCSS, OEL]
BO_ 2566768638 OHCSS: 8 Vector__XXX
 SG_ EngAltDroopAuxInputSelectState : 28|4@1+ (1,0) [0|15] "" Vector__XXX
 SG_ EngAltDropRemoteAccelSelectState : 24|4@1+ (1,0) [0|15] "" Vector__XXX
 SG_ EngAltDroopAccel2SelectState : 20|4@1+ (1,0) [0|15] "" Vector__XXX
 SG_ EngAltDroopAccel1SelectState : 16|4@1+ (1,0) [0|15] "" Vector__XXX
 SG_ EngAltRatingSelectState : 8|8@1+ (1,0) [0|255] "" Vector__XXX
 SG_ EngAltLowIdleSelectState : 4|2@1+ (1,0) [0|3] "" Vector__XXX
 SG_ EngMultiUnitSyncState : 2|2@1+ (1,0) [0|3] "" Vector__XXX
 SG_ EngAuxGovernorState : 0|2@1+ (1,0) [0|3] "" Vector__XXX

BO_ 2365443326 OEL: 8 Vector__XXX
 SG_ OprtorsDesiredDelayedLampOffTime : 24|16@1+ (1,0) [0|64255] "s" Vector__XXX
 SG_ OperatorsDesiredBacklight : 16|8@1+ (0.4,0) [0|100] "%" Vector__XXX
 SG_ HighLowBeamSwitch : 14|2@1+ (1,0) [0|3] "" Vector__XXX
 SG_ HazardLightSwitch : 12|2@1+ (1,0) [0|3] "" Vector__XXX
 SG_ TurnSignalSwitch : 8|4@1+ (1,0) [0|15] "" Vector__XXX
 SG_ MainLightSwitch : 4|4@1+ (1,0) [0|15] "" Vector__XXX
 SG_ WorkLightSwitch : 0|4@1+ (1,0) [0|15] "" Vector__XXX

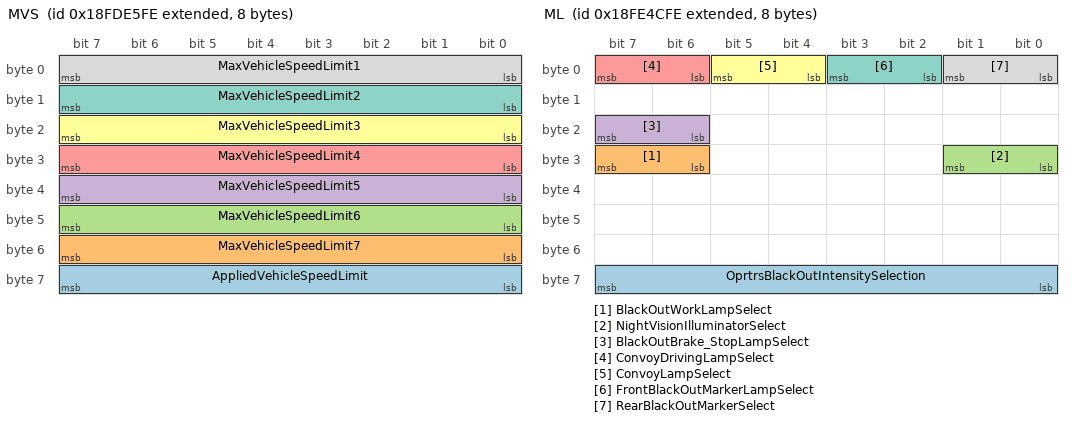
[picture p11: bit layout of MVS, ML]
BO_ 2566776318 MVS: 8 Vector__XXX
 SG_ AppliedVehicleSpeedLimit : 56|8@1+ (1,0) [0|250] "km/h" Vector__XXX
 SG_ MaxVehicleSpeedLimit7 : 48|8@1+ (1,0) [0|250] "km/h" Vector__XXX
 SG_ MaxVehicleSpeedLimit6 : 40|8@1+ (1,0) [0|250] "km/h" Vector__XXX
 SG_ MaxVehicleSpeedLimit5 : 32|8@1+ (1,0) [0|250] "km/h" Vector__XXX
 SG_ MaxVehicleSpeedLimit4 : 24|8@1+ (1,0) [0|250] "km/h" Vector__XXX
 SG_ MaxVehicleSpeedLimit3 : 16|8@1+ (1,0) [0|250] "km/h" Vector__XXX
 SG_ MaxVehicleSpeedLimit2 : 8|8@1+ (1,0) [0|250] "km/h" Vector__XXX
 SG_ MaxVehicleSpeedLimit1 : 0|8@1+ (1,0) [0|250] "km/h" Vector__XXX

BO_ 2566802686 ML: 8 Vector__XXX
 SG_ OprtrsBlackOutIntensitySelection : 56|8@1+ (0.4,0) [0|100] "%" Vector__XXX
 SG_ BlackOutWorkLampSelect : 30|2@1+ (1,0) [0|3] "" Vector__XXX
 SG_ NightVisionIlluminatorSelect : 24|2@1+ (1,0) [0|3] "" Vector__XXX
 SG_ BlackOutBrake_StopLampSelect : 22|2@1+ (1,0) [0|3] "" Vector__XXX
 SG_ ConvoyDrivingLampSelect : 6|2@1+ (1,0) [0|3] "" Vector__XXX
 SG_ ConvoyLampSelect : 4|2@1+ (1,0) [0|3] "" Vector__XXX
 SG_ FrontBlackOutMarkerLampSelect : 2|2@1+ (1,0) [0|3] "" Vector__XXX
 SG_ RearBlackOutMarkerSelect : 0|2@1+ (1,0) [0|3] "" Vector__XXX

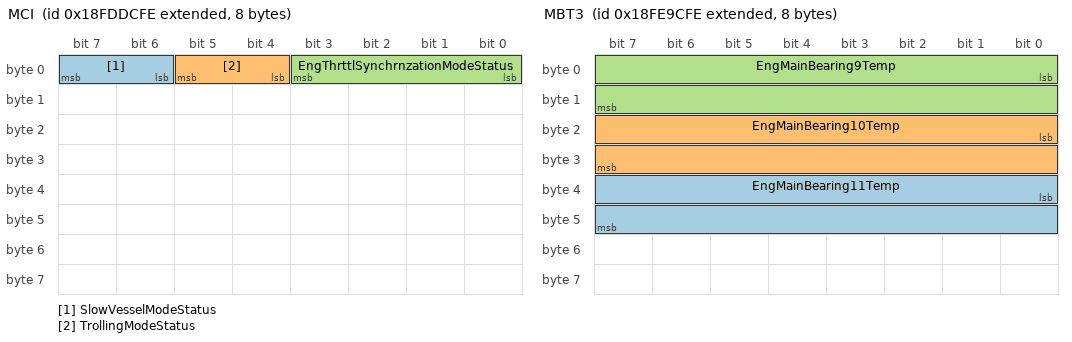
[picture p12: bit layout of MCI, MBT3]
BO_ 2566774014 MCI: 8 Vector__XXX
 SG_ SlowVesselModeStatus : 6|2@1+ (1,0) [0|3] "" Vector__XXX
 SG_ TrollingModeStatus : 4|2@1+ (1,0) [0|3] "" Vector__XXX
 SG_ EngThrttlSynchrnzationModeStatus : 0|4@1+ (1,0) [0|15] "" Vector__XXX

BO_ 2566823166 MBT3: 8 Vector__XXX
 SG_ EngMainBearing11Temp : 32|16@1+ (0.03125,-273) [-273|1734.96875] "°C" Vector__XXX
 SG_ EngMainBearing10Temp : 16|16@1+ (0.03125,-273) [-273|1734.96875] "°C" Vector__XXX
 SG_ EngMainBearing9Temp : 0|16@1+ (0.03125,-273) [-273|1734.96875] "°C" Vector__XXX

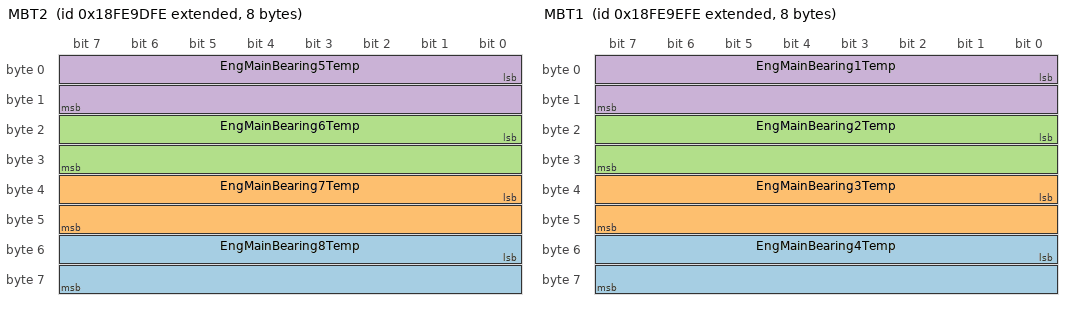
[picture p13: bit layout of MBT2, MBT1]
BO_ 2566823422 MBT2: 8 Vector__XXX
 SG_ EngMainBearing8Temp : 48|16@1+ (0.03125,-273) [-273|1734.96875] "°C" Vector__XXX
 SG_ EngMainBearing7Temp : 32|16@1+ (0.03125,-273) [-273|1734.96875] "°C" Vector__XXX
 SG_ EngMainBearing6Temp : 16|16@1+ (0.03125,-273) [-273|1734.96875] "°C" Vector__XXX
 SG_ EngMainBearing5Temp : 0|16@1+ (0.03125,-273) [-273|1734.96875] "°C" Vector__XXX

BO_ 2566823678 MBT1: 8 Vector__XXX
 SG_ EngMainBearing4Temp : 48|16@1+ (0.03125,-273) [-273|1734.96875] "°C" Vector__XXX
 SG_ EngMainBearing3Temp : 32|16@1+ (0.03125,-273) [-273|1734.96875] "°C" Vector__XXX
 SG_ EngMainBearing2Temp : 16|16@1+ (0.03125,-273) [-273|1734.96875] "°C" Vector__XXX
 SG_ EngMainBearing1Temp : 0|16@1+ (0.03125,-273) [-273|1734.96875] "°C" Vector__XXX

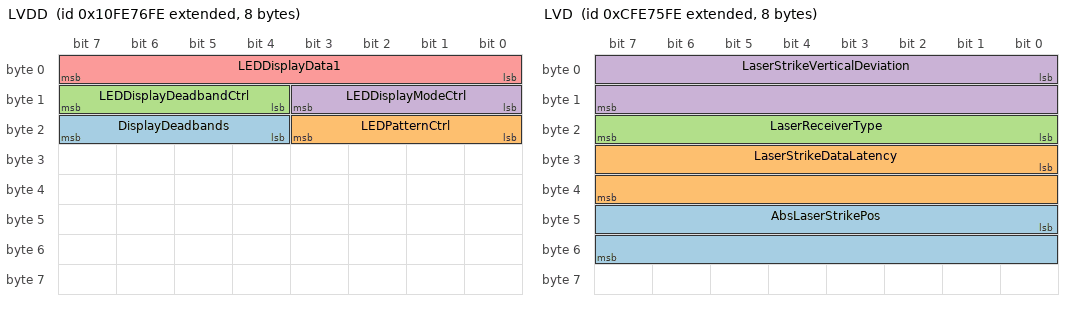
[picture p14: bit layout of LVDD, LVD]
BO_ 2432595710 LVDD: 8 Vector__XXX
 SG_ DisplayDeadbands : 20|4@1+ (1,0) [0|15] "" Vector__XXX
 SG_ LEDPatternCtrl : 16|4@1+ (1,0) [0|15] "" Vector__XXX
 SG_ LEDDisplayDeadbandCtrl : 12|4@1+ (1,0) [0|15] "" Vector__XXX
 SG_ LEDDisplayModeCtrl : 8|4@1+ (1,0) [0|15] "" Vector__XXX
 SG_ LEDDisplayData1 : 0|8@1+ (1,0) [0|255] "" Vector__XXX

BO_ 2365486590 LVD: 8 Vector__XXX
 SG_ AbsLaserStrikePos : 40|16@1+ (0.1,0) [0|6425.5] "mm" Vector__XXX
 SG_ LaserStrikeDataLatency : 24|16@1+ (5.12E-005,0) [0|3.289856] "s" Vector__XXX
 SG_ LaserReceiverType : 16|8@1+ (1,0) [0|250] "" Vector__XXX
 SG_ LaserStrikeVerticalDeviation : 0|16@1+ (0.1,-3200) [-3200|3225.5] "mm" Vector__XXX

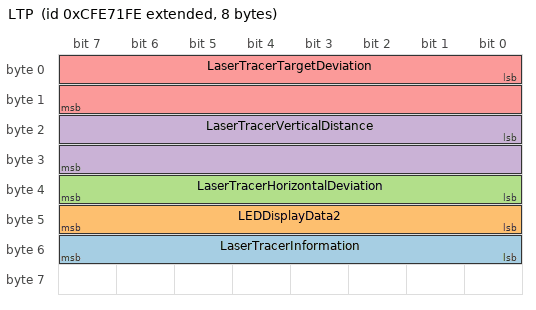
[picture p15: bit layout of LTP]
BO_ 2365485566 LTP: 8 Vector__XXX
 SG_ LaserTracerInformation : 48|8@1+ (1,0) [0|255] "" Vector__XXX
 SG_ LEDDisplayData2 : 40|8@1+ (1,0) [0|255] "" Vector__XXX
 SG_ LaserTracerHorizontalDeviation : 32|8@1+ (1,0) [0|200] "%" Vector__XXX
 SG_ LaserTracerVerticalDistance : 16|16@1+ (0.1,0) [0|6400] "mm" Vector__XXX
 SG_ LaserTracerTargetDeviation : 0|16@1+ (0.1,-3200) [-3200|3225.5] "mm" Vector__XXX

BO_ 2633939454 LTFI: 22 Vector__XXX
 SG_ TripDriveFuelEconomy : 160|16@1+ (0.001953125,0) [0|125.498046875] "km/L" Vector__XXX
 SG_ TripCruiseFuelUsed : 128|32@1+ (0.5,0) [0|2105540607.5] "L" Vector__XXX
 SG_ TripVehicleIdleFuelUsed : 96|32@1+ (0.5,0) [0|2105540607.5] "L" Vector__XXX
 SG_ TripPTOGovernorNonmovingFuelUsed : 64|32@1+ (0.5,0) [0|2105540607.5] "L" Vector__XXX
 SG_ TripPTOGovernorMovingFuelUsed : 32|32@1+ (0.5,0) [0|2105540607.5] "L" Vector__XXX
 SG_ TripDriveFuelUsed : 0|32@1+ (0.5,0) [0|2105540607.5] "L" Vector__XXX

BO_ 2365486334 LSP: 8 Vector__XXX
 SG_ BldeHeightSetPointHighResolution : 16|32@1+ (1E-007,-209.7152) [-209.7152|209.7152] "m" Vector__XXX
 SG_ ModifyLevelingSystemSetPoint : 0|16@1+ (0.1,-3200) [-3200|3225.5] "mm" Vector__XXX

CM_ BO_ 2566845694 "Tire Condition Message
NOTE–Message has to repeated as necessary to transmit all available information.  This method of location identification requires individual SPNs to be assigned to report failures specific to each individual component (I.e ...";
CM_ SG_ 2566845694 TirePressThresholdDetection_13 "Signal indicating the pressure level of the tire.";
CM_ SG_ 2566845694 TirePressThresholdDetection_12 "Signal indicating the pressure level of the tire.";
CM_ SG_ 2566845694 TirePressThresholdDetection_11 "Signal indicating the pressure level of the tire.";
CM_ SG_ 2566845694 TirePressThresholdDetection_10 "Signal indicating the pressure level of the tire.";
CM_ SG_ 2566845694 TirePressThresholdDetection_01 "Signal indicating the pressure level of the tire.";
CM_ SG_ 2566845694 TirePress_33 "Pressure at which air is contained in cavity formed by tire and rim.";
CM_ SG_ 2566845694 TirePress_32 "Pressure at which air is contained in cavity formed by tire and rim.";
CM_ SG_ 2566845694 TirePress_31 "Pressure at which air is contained in cavity formed by tire and rim.";
CM_ SG_ 2566845694 TirePress_30 "Pressure at which air is contained in cavity formed by tire and rim.";
CM_ SG_ 2566845694 TirePress_23 "Pressure at which air is contained in cavity formed by tire and rim.";
CM_ SG_ 2566845694 TirePress_22 "Pressure at which air is contained in cavity formed by tire and rim.";
CM_ SG_ 2566845694 TirePress_21 "Pressure at which air is contained in cavity formed by tire and rim.";
CM_ SG_ 2566845694 TirePress_20 "Pressure at which air is contained in cavity formed by tire and rim.";
CM_ SG_ 2566845694 TirePress_13 "Pressure at which air is contained in cavity formed by tire and rim.";
CM_ SG_ 2566845694 TirePress_12 "Pressure at which air is contained in cavity formed by tire and rim.";
CM_ SG_ 2566845694 TirePress_11 "Pressure at which air is contained in cavity formed by tire and rim.";
CM_ SG_ 2566845694 TirePress_10 "Pressure at which air is contained in cavity formed by tire and rim.";
CM_ SG_ 2566845694 TireAirLeakageRate_33 "The pressure loss rate of a tire.";
CM_ SG_ 2566845694 TireAirLeakageRate_32 "The pressure loss rate of a tire.";
CM_ SG_ 2566845694 TireAirLeakageRate_31 "The pressure loss rate of a tire.";
CM_ SG_ 2566845694 TireAirLeakageRate_30 "The pressure loss rate of a tire.";
CM_ SG_ 2566845694 TireAirLeakageRate_23 "The pressure loss rate of a tire.";
CM_ SG_ 2566845694 TireAirLeakageRate_22 "The pressure loss rate of a tire.";
CM_ SG_ 2566845694 TireAirLeakageRate_21 "The pressure loss rate of a tire.";
CM_ SG_ 2566845694 TireAirLeakageRate_20 "The pressure loss rate of a tire.";
CM_ SG_ 2566845694 TireAirLeakageRate_13 "The pressure loss rate of a tire.";
CM_ SG_ 2566845694 TireAirLeakageRate_12 "The pressure loss rate of a tire.";
CM_ SG_ 2566845694 TireAirLeakageRate_11 "The pressure loss rate of a tire.";
CM_ SG_ 2566845694 TireAirLeakageRate_10 "The pressure loss rate of a tire.";
CM_ SG_ 2566845694 TireAirLeakageRate_01 "The pressure loss rate of a tire.";
CM_ SG_ 2566845694 TireAirLeakageRate_00 "The pressure loss rate of a tire.";
CM_ SG_ 2566845694 CTIWheelSensorStatus_33 "Indicates whether the wheel is being monitored by the CTI controller.";
CM_ SG_ 2566845694 CTIWheelSensorStatus_32 "Indicates whether the wheel is being monitored by the CTI controller.";
CM_ SG_ 2566845694 CTIWheelSensorStatus_31 "Indicates whether the wheel is being monitored by the CTI controller.";
CM_ SG_ 2566845694 CTIWheelSensorStatus_30 "Indicates whether the wheel is being monitored by the CTI controller.";
CM_ SG_ 2566845694 CTIWheelSensorStatus_23 "Indicates whether the wheel is being monitored by the CTI controller.";
CM_ SG_ 2566845694 CTIWheelSensorStatus_22 "Indicates whether the wheel is being monitored by the CTI controller.";
CM_ SG_ 2566845694 CTIWheelSensorStatus_21 "Indicates whether the wheel is being monitored by the CTI controller.";
CM_ SG_ 2566845694 CTIWheelSensorStatus_20 "Indicates whether the wheel is being monitored by the CTI controller.";
CM_ SG_ 2566845694 CTIWheelSensorStatus_13 "Indicates whether the wheel is being monitored by the CTI controller.";
CM_ SG_ 2566845694 CTIWheelSensorStatus_12 "Indicates whether the wheel is being monitored by the CTI controller.";
CM_ SG_ 2566845694 CTIWheelSensorStatus_11 "Indicates whether the wheel is being monitored by the CTI controller.";
CM_ SG_ 2566845694 CTIWheelSensorStatus_10 "Indicates whether the wheel is being monitored by the CTI controller.";
CM_ SG_ 2566845694 CTIWheelSensorStatus_01 "Indicates whether the wheel is being monitored by the CTI controller.";
CM_ SG_ 2566845694 CTIWheelEndElectricalFault_33 "Indicates the status of electrical fault on CTI wheel interface.";
CM_ SG_ 2566845694 CTIWheelEndElectricalFault_32 "Indicates the status of electrical fault on CTI wheel interface.";
CM_ SG_ 2566845694 CTIWheelEndElectricalFault_31 "Indicates the status of electrical fault on CTI wheel interface.";
CM_ SG_ 2566845694 CTIWheelEndElectricalFault_30 "Indicates the status of electrical fault on CTI wheel interface.";
CM_ SG_ 2566845694 CTIWheelEndElectricalFault_23 "Indicates the status of electrical fault on CTI wheel interface.";
CM_ SG_ 2566845694 CTIWheelEndElectricalFault_22 "Indicates the status of electrical fault on CTI wheel interface.";
CM_ SG_ 2566845694 CTIWheelEndElectricalFault_21 "Indicates the status of electrical fault on CTI wheel interface.";
CM_ SG_ 2566845694 CTIWheelEndElectricalFault_20 "Indicates the status of electrical fault on CTI wheel interface.";
CM_ SG_ 2566845694 CTIWheelEndElectricalFault_13 "Indicates the status of electrical fault on CTI wheel interface.";
CM_ SG_ 2566845694 CTIWheelEndElectricalFault_12 "Indicates the status of electrical fault on CTI wheel interface.";
CM_ SG_ 2566845694 CTIWheelEndElectricalFault_11 "Indicates the status of electrical fault on CTI wheel interface.";
CM_ SG_ 2566845694 CTIWheelEndElectricalFault_10 "Indicates the status of electrical fault on CTI wheel interface.";
CM_ SG_ 2566845694 CTIWheelEndElectricalFault_01 "Indicates the status of electrical fault on CTI wheel interface.";
CM_ SG_ 2566845694 CTITireStatus_33 "Indicates the status of the tire.";
CM_ SG_ 2566845694 CTITireStatus_32 "Indicates the status of the tire.";
CM_ SG_ 2566845694 CTITireStatus_31 "Indicates the status of the tire.";
CM_ SG_ 2566845694 CTITireStatus_30 "Indicates the status of the tire.";
CM_ SG_ 2566845694 CTITireStatus_23 "Indicates the status of the tire.";
CM_ SG_ 2566845694 CTITireStatus_22 "Indicates the status of the tire.";
CM_ SG_ 2566845694 CTITireStatus_21 "Indicates the status of the tire.";
CM_ SG_ 2566845694 CTITireStatus_20 "Indicates the status of the tire.";
CM_ SG_ 2566845694 CTITireStatus_13 "Indicates the status of the tire.";
CM_ SG_ 2566845694 CTITireStatus_12 "Indicates the status of the tire.";
CM_ SG_ 2566845694 CTITireStatus_11 "Indicates the status of the tire.";
CM_ SG_ 2566845694 CTITireStatus_10 "Indicates the status of the tire.";
CM_ SG_ 2566845694 CTITireStatus_01 "Indicates the status of the tire.";
CM_ SG_ 2566845694 TireTemp_11 "Temperature at the surface of the tire sidewall.";
CM_ SG_ 2566845694 TireTemp_33 "Temperature at the surface of the tire sidewall.";
CM_ SG_ 2566845694 TireTemp_32 "Temperature at the surface of the tire sidewall.";
CM_ SG_ 2566845694 TireTemp_31 "Temperature at the surface of the tire sidewall.";
CM_ SG_ 2566845694 TireTemp_30 "Temperature at the surface of the tire sidewall.";
CM_ SG_ 2566845694 TireTemp_23 "Temperature at the surface of the tire sidewall.";
CM_ SG_ 2566845694 TireTemp_22 "Temperature at the surface of the tire sidewall.";
CM_ SG_ 2566845694 TireTemp_21 "Temperature at the surface of the tire sidewall.";
CM_ SG_ 2566845694 TireTemp_20 "Temperature at the surface of the tire sidewall.";
CM_ SG_ 2566845694 TireTemp_13 "Temperature at the surface of the tire sidewall.";
CM_ SG_ 2566845694 TireTemp_12 "Temperature at the surface of the tire sidewall.";
CM_ SG_ 2566845694 TireTemp_10 "Temperature at the surface of the tire sidewall.";
CM_ SG_ 2566845694 TireTemp_01 "Temperature at the surface of the tire sidewall.";
CM_ SG_ 2566845694 TireTemp_00 "Temperature at the surface of the tire sidewall.";
CM_ SG_ 2566845694 TirePressThresholdDetection_33 "Signal indicating the pressure level of the tire.";
CM_ SG_ 2566845694 TirePressThresholdDetection_32 "Signal indicating the pressure level of the tire.";
CM_ SG_ 2566845694 TirePressThresholdDetection_31 "Signal indicating the pressure level of the tire.";
CM_ SG_ 2566845694 TirePressThresholdDetection_30 "Signal indicating the pressure level of the tire.";
CM_ SG_ 2566845694 TirePressThresholdDetection_23 "Signal indicating the pressure level of the tire.";
CM_ SG_ 2566845694 TirePressThresholdDetection_22 "Signal indicating the pressure level of the tire.";
CM_ SG_ 2566845694 TirePressThresholdDetection_21 "Signal indicating the pressure level of the tire.";
CM_ SG_ 2566845694 TirePressThresholdDetection_20 "Signal indicating the pressure level of the tire.";
CM_ SG_ 2566845694 TirePressThresholdDetection_00 "Signal indicating the pressure level of the tire.";
CM_ SG_ 2566845694 TirePress_01 "Pressure at which air is contained in cavity formed by tire and rim.";
CM_ SG_ 2566845694 TirePress_00 "Pressure at which air is contained in cavity formed by tire and rim.";
CM_ SG_ 2566845694 CTIWheelSensorStatus_00 "Indicates whether the wheel is being monitored by the CTI controller.";
CM_ SG_ 2566845694 CTIWheelEndElectricalFault_00 "Indicates the status of electrical fault on CTI wheel interface.";
CM_ SG_ 2566845694 CTITireStatus_00 "Indicates the status of the tire.";
CM_ SG_ 2566845694 TireLocation "Identifies which tire is associated with the parametric data in this PGN.
The low order 4 bits represent a position number, counting left to right when facing in the direction of normal vehicle travel (forward).
The high order 4 bits represent a ...";
CM_ SG_ 2633939966 TripFanOnTimeDueToTheA_CSystem "Total time the fan has been on due to the A/C system since the last trip reset.  For the time to be accumulated against the A/C system, it is necessary that it be the first to request the fan activation or it be the only system requesting fan ...";
CM_ SG_ 2633939966 TripFanOnTimeDueToAManualSwitch "Total time the fan has been on due to manual activation by the operator (i.e., excluding time on due to automatic triggers) since the last trip reset.  For the time to be accumulated against the manual switch, it is necessary that it be the first to ...";
CM_ SG_ 2633939966 TripFanOnTimeDueToTheEngSystem "Total time the fan has been on due to engine triggers (i.e., excluding time on due to an operator manual switch or A/C system) since the last trip reset.  For the time to be accumulated against the engine system, it is necessary that it be the first ...";
CM_ SG_ 2633939966 TripFanOnTime "Total time the fan has been on (due to an automatic trigger or manual trigger) since the last trip reset.  The fan could be requested to be on by the engine system, a manual switch, and/or the A/C system.  Whichever system requests the fan ...";
CM_ SG_ 2633939710 TripDistanceInTopGear "Total distance accumulated while the vehicle has operated in top gear for a calibrated minimum time since the last trip reset.";
CM_ SG_ 2633939710 TripGearDownDistance "Total distance accumulated while the vehicle has operated in the gear which is one gear down from top gear and exceeds a calibrated minimum time (typically the time to shift the transmission) since the last trip reset.";
CM_ SG_ 2633939710 TripDistanceOnVSL "Total distance accumulated while the engine torque mode is road speed governing since the last trip reset.";
CM_ SG_ 2564161278 AdjustLocalHourOffset "The hour component for setting the offset between the UTC (Universal Time Coordinate) time and date and a the local time zone time and date.  This is the number of minutes to add to UTC, a.k.a. GMT, time and date to convert to the time and date in ...";
CM_ SG_ 2564161278 AdjustLocalMinuteOffset "The minute component for setting the offset between the UTC (Universal Time Coordinate) time and date and a the local time zone time and date.  This is the number of minutes to add to UTC, a.k.a. GMT, time and date to convert to the time and date in ...";
CM_ SG_ 2564161278 AdjustYear "The year component for setting the current calendar date.  This should be reported as the year component of the current date according to the calendar date standard indicated with the Local Hour Offset parameter (SPN 1602).  The calendar date should ...";
CM_ SG_ 2564161278 AdjustDay "The day component for setting the current calendar date.  This should be reported as the day component of the current date according to the calendar date standard indicated with the Local Hour Offset parameter (SPN 1602).  The calendar date should ...";
CM_ SG_ 2564161278 AdjustMonth "The month component for setting the current calendar date.  This should be reported as the month component of the current date according to the calendar date standard indicated with the Local Hour Offset parameter (SPN 1602).  The calendar date ...";
CM_ SG_ 2564161278 AdjustHours "The hours component for setting the current time of day.  This should be reported as the hours component of the current time according to the time of day standard indicated with the Local Hour Offset parameter (SPN 1602).  The time of day should be ...";
CM_ SG_ 2564161278 AdjustMinutes "The minutes component for setting the current time of day.  This should be reported as the minutes component of the current time according to the time of day standard indicated with the Local Hour Offset parameter (SPN 1602).  The time of day should ...";
CM_ SG_ 2564161278 AdjustSeconds "The seconds component for setting the current time of day.  This should be reported as the seconds component of the current time according to the time of day standard indicated with the Local Hour Offset parameter (SPN 1602).  The time of day should ...";
CM_ SG_ 2566842110 LocalHourOffset "The hour component of the offset between the UTC (Universal Time Coordinate) time and date and a local time zone time and date.  This is the number of hours to add to UTC, a.k.a. GMT, time and date to convert to the time and date in the local time ...";
CM_ SG_ 2566842110 LocalMinuteOffset "The minute component of the offset between the UTC time and date and a local time zone time and date.  This is the number of minutes to add to UTC (Universal Time Coordinate) time and date to convert to the time and date in the local time zone  ...";
CM_ SG_ 2566842110 Year "The year component of the current calendar date.  This should be reported as the year component of the current date at UTC (Universal Time Coordinate), a.k.a. GMT; however, it may be reported as the year component of the current date at a local time ...";
CM_ SG_ 2566842110 Day "The day component of the current calendar date.  This should be reported as the day component of the current date at UTC (Universal Time Coordinate), a.k.a. GMT; however, it may be reported as the day component of the current date at a local time ...";
CM_ SG_ 2566842110 Month "The month component of the current calendar date.  This should be reported as the month component of the current date at UTC (Universal Time Coordinate), a.k.a. GMT; however, it may be reported as the month component of the current date at a local ...";
CM_ SG_ 2566842110 Hours "The hour component of the current time of day.  This should be reported as the hour component of the current time at UTC (Universal Time Coordinate), a.k.a. GMT; however, it may be reported as the hour component of the current time at a local time ...";
CM_ SG_ 2566842110 Minutes "The minutes component of the current time of day.  This should be reported as the minutes component of the current time at UTC (Universal Time Coordinate), a.k.a. GMT; however, it may be reported as the minutes component of the current time at a ...";
CM_ SG_ 2566842110 Seconds "The seconds component of the current time of day.  This should be reported as the seconds component of the current time at UTC (Universal Time Coordinate), a.k.a. GMT; however, it may be reported as the seconds component of the current time at a ...";
CM_ SG_ 2566821630 EngDsrdTrboWastegateActuator2Pos "The Requested Valve position of the Turbocharger Wastegate Valve 2, commanded by the engine ECM. A value of 0% represents fully closed and a value of 100% represents fully open.

This is the position that the device is attempting to achieve.";
CM_ SG_ 2566821630 EngTrbWstgateActuator1TempStatus "Used to identify the status of the Engine Turbocharger Wastegate Actuator 1 drive circuitry temperature.  Temperature excursions may affect the torque output.
000 – High Most severe
001 – High Least severe
010 – In Range
011 – Low Least severe
 ...";
CM_ SG_ 2566821630 EngTrbWstgtActtor1PreliminaryFMI "Used to identify the applicable J1939-73 FMI detected in the Engine Turbocharger Wastegate Actuator 1 by the manufacturers software. When there is no failure FMI 31 is transmitted. When there is multiple failures, the most severe is transmitted";
CM_ SG_ 2566821630 EngDsrdTrboWastegateActuator1Pos "The Requested Valve position of the Turbocharger Wastegate Valve 1, commanded by the engine ECM. A value of 0% represents fully closed and a value of 100% represents fully open.

This is the position that the device is attempting to achieve.";
CM_ SG_ 2566821630 EngTrbWstgteActuatorCtrlAirPress "Gage pressure of the air used to control the actuator which opens and closes the wastegate valve.";
CM_ SG_ 2566821630 EngTurboWastegateActuator4Pos "Position of the wastegate drive.  A value of 0% represents fully closed and a value of 100% represents fully open.";
CM_ SG_ 2566821630 EngTurboWastegateActuator3Pos "Position of the wastegate drive.  A value of 0% represents fully closed and a value of 100% represents fully open.";
CM_ SG_ 2566821630 EngTurboWastegateActuator2Pos "Position of the wastegate drive.  A value of 0% represents fully closed and a value of 100% represents fully open.";
CM_ SG_ 2566821630 EngTurboWastegateActuator1Pos "Position of the wastegate drive.  A value of 0% represents fully closed and a value of 100% represents fully open.";
CM_ SG_ 2365484286 TachographVehicleSpeed "Speed of the vehicle registered by the tachograph.";
CM_ SG_ 2365484286 TachographOutputShaftSpeed "Calculated speed of the transmission output shaft.";
CM_ SG_ 2365484286 DirectionIndicator "Indicates the direction of the vehicle.

00 - Forward
01 - Reverse
10 - Error
11 - Not available";
CM_ SG_ 2365484286 TachographPerformance "Indicates the tachograph performance; including electronic or mechanical analysis, instrument analysis, speed sensor analysis, mass storage analysis, and printer analysis.
00 - Normal performance
01 - Performance analysis
10 - Error
11 - Not ...";
CM_ SG_ 2365484286 HandlingInformation "Indicates that handling information is present.  Information could include “no printer paper”, “no driver card”, etc.

00 - No handling information
01 - Handling information
10 - Error
11 - Not available";
CM_ SG_ 2365484286 SystemEvent "Indicates that a tachograph event has occurred.  This may include power supply interruption, interruption of the speed sensor, incorrect data on the driver card, driving without a driver card, illegal removal of a driver card, insertion of a driver ...";
CM_ SG_ 2365484286 DriverCardDriver2 "Indicates the presence of a driver card

00 - Driver card not present
01 - Driver card present
10 - Error
11 - Not available";
CM_ SG_ 2365484286 Driver2TimeRelatedStates "Indicates if the driver approaches or exceeds working time limits (or other limits).
0000 Normal/No limits reached
0001 Limit #1 – 15 min before 4 ½ h
0010 Limit #2 – 4 ½ h reached
0011 Limit #3 – 15 min before 9 h
0100 Limit #4 – 9 h reached
 ...";
CM_ SG_ 2365484286 VehicleOverspeed "Indicates whether the vehicle is exceeding the legal speed limit set in the tachograph.

00 No overspeed
01 Overspeed
10 Error
11 Not available";
CM_ SG_ 2365484286 DriverCardDriver1 "Indicates the presence of a driver card

00 - Driver card not present
01 - Driver card present
10 - Error
11 - Not available";
CM_ SG_ 2365484286 Driver1TimeRelatedStates "Indicates if the driver approaches or exceeds working time limits (or other limits).
0000 Normal/No limits reached
0001 Limit #1 – 15 min before 4 ½ h
0010 Limit #2 – 4 ½ h reached
0011 Limit #3 – 15 min before 9 h
0100 Limit #4 – 9 h reached
 ...";
CM_ SG_ 2365484286 VehicleMotion "Indicates whether motion of the vehicle is detected or not.

00 Vehicle motion not detected
01 Vehicle motion detected
10 - Error
11 - Not available";
CM_ SG_ 2365484286 Driver2WorkingState "State of work of the driver.  

000 Rest - sleeping
001 Driver available – short break
010 Work – loading, unloading, working in an office
011 Drive – behind wheel 
100-101 Reserved
110 Error
111 Not available";
CM_ SG_ 2365484286 Driver1WorkingState "State of work of the driver.  

000 Rest - sleeping
001 Driver available – short break
010 Work – loading, unloading, working in an office
011 Drive – behind wheel 
100-101 Reserved
110 Error
111 Not available";
CM_ SG_ 2566771710 EngTurbo4CompressorOutletTemp "Temperature of the air exiting the turbocharger 4 compressor outlet";
CM_ SG_ 2566771710 EngTurbo3CompressorOutletTemp "Temperature of the air exiting the turbocharger 3 compressor outlet";
CM_ SG_ 2566771710 EngTurbo2CompressorOutletTemp "Temperature of the air exiting the turbocharger 2 compressor outlet";
CM_ SG_ 2566771710 EngTurbo1CompressorOutletTemp "Temperature of the air exiting the turbocharger 1 compressor outlet";
CM_ SG_ 2566821886 EngTurbo4TurbineOutletTemp "Temperature of the combustion by-products exiting the turbine side of the turbocharger.";
CM_ SG_ 2566821886 EngTurbo3TurbineOutletTemp "Temperature of the combustion by-products exiting the turbine side of the turbocharger.";
CM_ SG_ 2566821886 EngTurbo2TurbineOutletTemp "Temperature of the combustion by-products exiting the turbine side of the turbocharger.";
CM_ SG_ 2566821886 EngTurbo1TurbineOutletTemp "Temperature of the combustion by-products exiting the turbine side of the turbocharger.";
CM_ SG_ 2566822142 EngTurbo4TurbineIntakeTemp "Temperature of the combustion by-products entering the turbine side of the turbocharger.";
CM_ SG_ 2566822142 EngTurbo3TurbineIntakeTemp "Temperature of the combustion by-products entering the turbine side of the turbocharger.";
CM_ SG_ 2566822142 EngTurbo2TurbineIntakeTemp "Temperature of the combustion by-products entering the turbine side of the turbocharger.";
CM_ SG_ 2566822142 EngTurbo1TurbineIntakeTemp "Temperature of the combustion by-products entering the turbine side of the turbocharger.";
CM_ SG_ 2566822398 EngTurbo4CompressorIntakePress "Gage pressure of the air entering the compressor side of the turbocharger.";
CM_ SG_ 2566822398 EngTurbo3CompressorIntakePress "Gage pressure of the air entering the compressor side of the turbocharger.";
CM_ SG_ 2566822398 EngTurbo2CompressorIntakePress "Gage pressure of the air entering the compressor side of the turbocharger.";
CM_ SG_ 2566822398 EngTurbo1CompressorIntakePress "Gage pressure of the air entering the compressor side of the turbocharger.";
CM_ SG_ 2566822654 EngTurbo4CompressorIntakeTemp "Temperature of the air entering the compressor side of the turbocharger.";
CM_ SG_ 2566822654 EngTurbo3CompressorIntakeTemp "Temperature of the air entering the compressor side of the turbocharger.";
CM_ SG_ 2566822654 EngTurbo2CompressorIntakeTemp "Temperature of the air entering the compressor side of the turbocharger.";
CM_ SG_ 2566822654 EngTurbo1CompressorIntakeTemp "Temperature of the air entering the compressor side of the turbocharger.";
CM_ SG_ 2633931774 EngTurbo4Speed "Rotational velocity of rotor in the turbocharger.";
CM_ SG_ 2633931774 EngTurbo3Speed "Rotational velocity of rotor in the turbocharger.";
CM_ SG_ 2633931774 EngTurbo2Speed "Rotational velocity of rotor in the turbocharger.";
CM_ SG_ 2633931774 EngTurboLubeOilPress2 "Gage pressure of oil in turbocharger lubrication system.";
CM_ BO_ 2566802430 "Contains transmission configuration information.";
CM_ SG_ 2566802430 TransTorqueLimit "Parameter provided to the engine from the transmission as a torque limit to be invoked by the engine in the event that J1939 communication with the transmission is lost.
The intention is to protect transmissions that use a continuous torque limit ...";
CM_ BO_ 2566841086 "Total message length depends on total number of forward and reverse gear ratios.
NOTE:  The first gear ratio transmitted in bytes 3,4 will be the highest reverse gear ratio.  Additional 2-byte gear ratios will follow:
3,4    Highest reverse gear ...";
CM_ SG_ 2566841086 TransGearRatio "The transmission configuration describes the number of forward gears, the number of reverse gears, and the ratio of each gear with the following resolution.";
CM_ SG_ 2566841086 NumberOfForwardGearRatios "Number of forward gear ratios in the transmission, provided as part of the configuration.";
CM_ SG_ 2566841086 NumberOfReverseGearRatios "Number of reverse gear ratios in the transmission, provided as part of the transmission configuration.";
CM_ SG_ 2348941054 TransMode8 "Indicates whether transmission mode 8 is enabled. Modes are manufacturer specific and are not necessarily mutually exclusive. See also SPN 4253.

00  Disable
01  Enable
10  Reserved
11  Take no action";
CM_ SG_ 2348941054 TransMode7 "Indicates whether transmission mode 7 is enabled. Modes are manufacturer specific and are not necessarily mutually exclusive. See also SPN 4252.

00  Disable
01  Enable
10  Reserved
11  Take no action";
CM_ SG_ 2348941054 TransMode6 "Indicates whether transmission mode 6 is enabled. Modes are manufacturer specific and are not necessarily mutually exclusive. See also SPN 4251.

00  Disable
01  Enable
10  Reserved
11  Take no action";
CM_ SG_ 2348941054 TransMode5 "Indicates whether transmission mode 5 is enabled. Modes are manufacturer specific and are not necessarily mutually exclusive. See also SPN 4250.

00  Disable
01  Enable
10  Reserved
11  Take no action";
CM_ SG_ 2348941054 TrnsShftSlectorDisplayModeSwitch "Status of the operator’s switch used to ‘toggle’ through multiple display modes of a shift selector display.
When a shift selector display is capable of displaying more than just range information, this switch is toggled by the operator to move ...";
CM_ SG_ 2348941054 TransRequestedLaunchGear "Initial gear for the transmission to start out in when the vehicle is launched from a standing stop, as specified by the vehicle operator or vehicle system.  Automatic transmissions typically default to starting out in 1st gear.  However, in ...";
CM_ SG_ 2348941054 TransMode4 "Indicates whether transmission mode 4 is enabled.  Modes are manufacturer specific and are not necessarily mutually exclusive.  See also SPN 2539.

00 Disable
01 Enable
10 Reserved
11 Take no action";
CM_ SG_ 2348941054 TransMode3 "Indicates whether transmission mode 3 is enabled.  Modes are manufacturer specific and are not necessarily mutually exclusive.  See also SPN 2538.

00 Disable
01 Enable
10 Reserved
11 Take no action";
CM_ SG_ 2348941054 TransMode2 "Indicates whether transmission mode 2 is enabled.  Modes are manufacturer specific and are not necessarily mutually exclusive.  See also SPN 2537.

00 Disable
01 Enable
10 Reserved
11 Take no action";
CM_ SG_ 2348941054 TransMode1 "Indicates whether transmission mode 1 is enabled.  Modes are manufacturer specific and are not necessarily mutually exclusive.  See also SPN 2536.

00 Disable
01 Enable
10 Reserved
11 Take no action";
CM_ SG_ 2348941054 TransLoadReductionInhibitRq "Request signal to the transmission to inhibit activation of load reduction functions.
Automatic transmissions may incorporate functions designed to reduce engine load during certain operating conditions (vehicle standstill at bus stop, traffic ...";
CM_ SG_ 2348941054 DisengageDiffLockRqCentralRear "Command signal used to disengage the various differential locks, e.g., to allow an undistributed individual wheel control by ABS.  The differential locks are located as defined in Figure SPN564_A.
00 Engage differential lock
01 Disengage ...";
CM_ SG_ 2348941054 DisengageDiffLockRqCentralFront "Command signal used to disengage the various differential locks, e.g., to allow an undistributed individual wheel control by ABS.  The differential locks are located as defined in Figure SPN564_A.
00 Engage differential lock
01 Disengage ...";
CM_ SG_ 2348941054 DisengageDiffLockRqCentral "Command signal used to disengage the various differential locks, e.g., to allow an undistributed individual wheel control by ABS.  The differential locks are located as defined in Figure SPN564_A.
00 Engage differential lock
01 Disengage ...";
CM_ SG_ 2348941054 DisengageDiffLockRqRearAxle2 "Command signal used to disengage the various differential locks, e.g., to allow an undistributed individual wheel control by ABS.  The differential locks are located as defined in Figure SPN564_A.
00 Engage differential lock
01 Disengage ...";
CM_ SG_ 2348941054 DisengageDiffLockRqRearAxle1 "Command signal used to disengage the various differential locks, e.g., to allow an undistributed individual wheel control by ABS.  The differential locks are located as defined in Figure SPN564_A.
00 Engage differential lock
01 Disengage ...";
CM_ SG_ 2348941054 DisengageDiffLockRqFrontAxle2 "Command signal used to disengage the various differential locks, e.g., to allow an undistributed individual wheel control by ABS.  The differential locks are located as defined in Figure SPN564_A.
00 Engage differential lock
01 Disengage ...";
CM_ SG_ 2348941054 DisengageDiffLockRqFrontAxle1 "Command signal used to disengage the various differential locks, e.g., to allow an undistributed individual wheel control by ABS.  The differential locks are located as defined in Figure SPN564_A.
00 Engage differential lock
01 Disengage ...";
CM_ SG_ 2348941054 TransRequestedGear "Gear requested by the operator, ABS, or engine.
Negative values are reverse gears, positive values are forward gears, zero is neutral, parameter specific indicators are listed below.
Parameter specific values for this parameter are as follows:
 ...";
CM_ SG_ 2348941054 RequestedPercentClutchSlip "Parameter which represents the percent clutch slip requested by a device.";
CM_ SG_ 2348941054 TransReverseGearShiftInhibitRq "Allows devices external to the normal transmission shift selector system to request the transmission to inhibit shifts into any Reverse gear and force the transmission into Neutral if it is currently in Reverse or attempting to shift to Reverse ...";
CM_ SG_ 2348941054 DisengageDrivelineRq "Command signal used to simply disengage the driveline, e.g., to prevent engine drag torque from causing high wheel slip on slippery surfaces.

00 Allow driveline engagement
01 Disengage driveline
10 Reserved
11 Take no action";
CM_ SG_ 2348941054 TrnsTrqeConverterLockupDisableRq "Command signal to prevent torque converter lockup, which may cause problems in certain circumstances for ASR.

00 Allow torque converter lockup
01 Disable torque converter lockup
10 Reserved
11 Take no action";
CM_ SG_ 2348941054 TransGearShiftInhibitRq "Command signal to inhibit gear shifts.

00 Gear shifts are allowed  (disable function)
01 Gear shifts are inhibited  (enable function)
10 Reserved
11 Take no action  (leave function as is)";
CM_ SG_ 2566839806 EngTurboOilLevelSwitch "Switch signal which indicates the presence of oil at the turbocharger

     00 = No oil present at turbocharger
     01 = Oil present at turbocharger
     10 = Error
     11 = Not available";
CM_ SG_ 2566839806 EngTurbo1Speed "Rotational velocity of rotor in the turbocharger.";
CM_ SG_ 2566839806 EngTurboLubeOilPress1 "Gage pressure of oil in turbocharger lubrication system.";
CM_ SG_ 2566839806 EngTurboDiffSpeed "The difference between turbocharger speeds on engine systems with 2 or more turbochargers. If there are are more than 2 turbochargers, it will be the difference between the fastest and the slowest turbocharger speed.";
CM_ BO_ 2633911806 "Averages of information accumulated over the life of the engine";
CM_ SG_ 2633911806 EngTotalAverageFuelEconomy "Average fuel economy, equal to total vehicle distance divided by total fuel used, over the life of the engine";
CM_ SG_ 2633911806 EngTotalAverageFuelRate "Average fuel rate, equal to total fuel used divided by total engine hours, over the life of the engine";
CM_ BO_ 2566775550 "Used for controlling the supply pressure.  Often used to raise the pressure of a supply pressure circuit in situations where more pneumatic energy is needed.

This message is the setpoint for the PGN 65198 message.";
CM_ SG_ 2566775550 PwertrainCircuitAirSupplyPressRq "Command signal to influence the air pressure in the powertrain circuit.  This parameter is the setpoint for the parameter SPN 6305.";
CM_ SG_ 2566775550 AirSuspensionSupplyPressRq "Command signal to influence the pneumatic pressure in the circuit for the electronically controlled air suspension system.   This parameter is the setpoint for the parameter SPN 1090.";
CM_ SG_ 2566775550 AuxEquipmentSupplyPressRq "Command signal to influence the pneumatic pressure in the auxiliary circuit.   This parameter is the setpoint for the parameter SPN 1089.";
CM_ SG_ 2566775550 ServiceBrakeAirPressRqCircuit2 "Command signal to influence the pneumatic pressure in the service brake circuit or reservoir #2.  This parameter is the setpoint for the parameter SPN 1088.";
CM_ SG_ 2566775550 ServiceBrakeAirPressRqCircuit1 "Command signal to influence the pneumatic pressure in the service brake circuit or reservoir #1.  This parameter is the setpoint for the parameter SPN 1087.";
CM_ SG_ 2566775550 ParkingAnd_orTrailerAirPressRq "Command signal to influence the pneumatic pressure in the circuit or reservoir for the parking brake and/or the trailer supply.  This parameter is the setpoint for the parameter SPN 1086.";
CM_ SG_ 2566775550 PneumaticSupplyPressRq "Command signal to influence the pneumatic pressure in the main reservoir.  This parameter is the setpoint for the parameter SPN 46.";
CM_ SG_ 2566819838 EngExtlShutdownAirSupplyPress "Pressure of the air used to shut off the fuel supply to the engine.";
CM_ BO_ 2566838785 "Byte: 1 Number of software identification fields
2-n Software identification(s)
Delimiter (ASCII “*”)
NOTE- The software identification field is variable in length and may contain up to 125 software identification designators.  An ASCII “*” is ...";
CM_ SG_ 2566838785 NmbrOfSftwreIdentificationFields "Number of software identification designators represented in the software identification parameter group.";
CM_ SG_ 2566838785 SoftwareIdentification "Software identification of an electronic module.  As an example, this parameter may be represented with ASCII characters MMDDYYaa where MM is the month, DD is the day, YY is the year, and aa is the revision number.
NOTE The ASCII character “*” is ...";
CM_ SG_ 2566841598 ClntLvlEngPrtctionShutdownStatus "Parameter which indicates the configuration of the coolant level engine protection shutdown.
00 - Disabled - calibration does not allow engine protection due to low coolant level or the override is currently active
01 - Enabled - calibration ...";
CM_ SG_ 2566841598 PTOShutdownHasShutdownEng "Status signal which identifies whether or not the engine has been shutdown by the PTO shutdown system.

00 - No
01 - Yes
10 - Error
11 - Not available";
CM_ SG_ 2566841598 EngAirShutoffStatus "State signal which indicates the actual measured position of the Air Shutoff.
00 - Air flow allowed to engine
01 - Air flow restricted
10 - Error
11 - Not Available
Note:   This parameter, in conjunction with SPN 2813 - \"Engine Air Shutoff ...";
CM_ SG_ 2566841598 EngOverspeedTest "The engine overspeed test signal as measured by the reporting ECM.  Engine Overspeed Test is a mechanism to simulate engine overspeed situations, while operating the engine within the engine's safe operating range.
State signal which indicates when ...";
CM_ SG_ 2566841598 EngAirShutoffCmdStatus "State signal which indicates when the Air Shutoff  driver output is being driven. Disabled means controller wants air flowing to the engine. Status of the airflow  shutoff as being commanded by the ECU.
00 Air Shutoff Disabled, not attempting to ...";
CM_ SG_ 2566841598 EngAlarmOutputCmdStatus "State signal which indicates when the Alarm driver output is being driven. Not active means the Controller has no alarm level conditions.
00 Engine Alarm Output Command Not Active
01 Engine Alarm Output Command Active
10 Reserved
11 Not ...";
CM_ SG_ 2566841598 EngAlarmAcknowledge "The Engine Alarm Acknowledge Input signal as measured by the reporting ECM.  The Engine Alarm Acknowledge is a mechanism for external acknowledgement of the SPN 2814,  Engine Alarm Output Command.
00 Engine Alarm Acknowledge  Not Active
01 Engine ...";
CM_ SG_ 2566841598 EngProtectionSystemConfig "Parameter which indicates the configuration of the engine shutdown system.

00 - Disabled in calibration
01 - Enabled in calibration
10 - Error
11 - Not available";
CM_ SG_ 2566841598 EngProtectionSystemTimerState "Status signal which indicates the current mode of the engine protection system timer system.  See Figure SPN1107_A.

00 - Inactive
01 - Active
10 - Error
11 - Not available";
CM_ SG_ 2566841598 EngProtectionSystemTimerOverride "Status signal which indicates the status of the override feature of the engine protection system timer. See Figure SPN1107_A.

00 - Inactive
01 - Active
10 - Error
11 - Not available";
CM_ SG_ 2566841598 EngPrtctnSystmApprachingShutdown "Status signal which indicates that engine shutdown is imminent.  This engine protection signal can be a result of different systems failing, i.e., engine overheating. See Figure SPN1107_A.
00 - Not approaching
01 - Approaching
10 - Error
11 - ...";
CM_ SG_ 2566841598 EngPrtectionSystemHasShutdownEng "Status signal which indicates whether or not the engine protection system has shutdown the engine.  See Figure SPN1107_A.

00 - No
01 - Yes
10 - Error
11 - Not available";
CM_ SG_ 2566841598 EngWaitToStartLamp "Lamp signal which indicates that the engine is too cold to start and the operator should wait until the signal becomes inactive (turns off).  See SPN 5416 for the lamp operating condition.

00 - Off
01 - On
10 - Error
11 - Not available";
CM_ SG_ 2566841598 RefrigerantHighPressSwitch "Switch signal which indicates the position of the high pressure switch in the coolant circuit of an air conditioning system.  When the switch is enabled, the pressure inside the circuit is too high and the compressor clutch may be disengaged.
00 - ...";
CM_ SG_ 2566841598 RefrigerantLowPressSwitch "Switch signal which indicates the position of the low pressure switch in the coolant circuit of an air conditioning system.  When the switch is enabled, the pressure inside the circuit is too low and the compressor clutch may be disengaged.
00 - ...";
CM_ SG_ 2566841598 A_CHighPressFanSwitch "Switch signal which indicates that the pressure in the coolant circuit of an air conditioning system is high and the fan may be engaged.

00 - Pressure normal
01 - Pressure high, fan may be engaged
10 - Error
11 - Not available";
CM_ SG_ 2566841598 EngIdleShutdownTimerFunction "Parameter which indicates the configuration of the idle shutdown timer system.

00 - Disabled in calibration
01 - Enabled in calibration
10 - Error
11 - Not available";
CM_ SG_ 2566841598 EngIdleShutdownTimerState "Status signal which indicates the current mode of operation of the idle shutdown timer system.  See Figure SPN590_A.

00 - Inactive
01 - Active
10 - Error
11 - Not available";
CM_ SG_ 2566841598 EngIdleShutdownTimerOverride "Status signal which indicates the status of the override feature of the idle shutdown timer system.  See Figure SPN590_A.

00 - Inactive
01 - Active
10 - Error
11 - Not available";
CM_ SG_ 2566841598 EngIdleShutdownDriverAlertMode "Status signal which indicates the status of the driver alert mode of the idle shutdown timer system.  While the driver alert mode is active, the idle shutdown timer may be overridden.  See Figure SPN590_A.
00 - Inactive
01 - Active
10 - Error
11 ...";
CM_ SG_ 2566841598 EngIdleShutdownHasShutdownEng "Status signal which identifies whether or not the engine has been shutdown by the idle shutdown timer system.  See Figure SPN590_A.

00 - No
01 - Yes
10 - Error
11 - Not available";
CM_ BO_ 2365459710 "This message is sent by the Master of a Working Set to identify an individual member of a specific Working Set (Master’s Source Address identifies the particular Working Set).";
CM_ SG_ 2365459710 IndustryGroup "0 = Global; 
   1  = On-Highway; 
   2  = Agricultural and Forestry; 
   3  = Construction; 
   4  = Marine;
   5  = Industrial - Process
          Control - Stationary (Gen-Sets)
   6  = Reserve for SAE
   7  = Reserve for SAE";
CM_ SG_ 2365459710 ManufacturerCode "Assigned by NMEA 2000 Committee";
CM_ BO_ 2566832382 "Transmitted with the service component identification that has the shortest distance or nearest time until the next service inspection.
NOTE - There are two acceptable formats for the Service PGN.  Format 1 has only 8 bytes of data and reports the ...";
CM_ SG_ 2566832382 SrviceDelay_OperationalTimeBased "The time in vehicle operational time until the next vehicle service inspection is required.  A negative value is transmitted if the service inspection has been passed.  The component that requires service is identified by the service component ...";
CM_ SG_ 2566832382 ServiceComponentIdentificatio913 "Identification of component needing service.  See Table SPN911_A.";
CM_ SG_ 2566832382 ServiceDelay_CalendarTimeBased "The time in weeks until the next vehicle service inspection is required.  A negative value is transmitted if the service inspection has been passed.  The component that requires service is identified by the service component identification (see SPN ...";
CM_ SG_ 2566832382 ServiceComponentIdentificatio912 "Identification of component needing service.  See Table SPN911_A.";
CM_ SG_ 2566832382 ServiceDistance "The distance which can be traveled by the vehicle before the next service inspection is required.  A negative distance is transmitted if the service inspection has been passed.  The component that requires service is identified by the service ...";
CM_ SG_ 2566832382 ServiceComponentIdentification "Identification of component needing service.  See Table SPN911_A.";
CM_ BO_ 2633928446 "NOTE - There are two acceptable formats for the Service PGN.  Format 1 has only 8 bytes of data and reports the component most in need of service for each of the three categories.  Format 2, however, uses the transport protocol as necessary (See ...";
CM_ SG_ 2633928446 TimeSinceLastService "The vehicle operation time since the last service was performed.  The type of service information is identified by the service component identification number.";
CM_ SG_ 2633928446 ServiceComponentIdentification "Identification of component needing service.  See Table SPN911_A.";
CM_ SG_ 2566804478 MinContinuousRetarderTorque "Applied limit for minimum continuous retarder torque";
CM_ SG_ 2566804478 MaxContinuousRetarderTorque "Applied limit for maximum continuous retarder torque.";
CM_ SG_ 2566804478 MinContinuousRetarderSpeed "Applied limit for minimum continuous retarder RPM";
CM_ SG_ 2566804478 MaxContinuousRetarderSpeed "Applied limit for maximum continuous retarder RPM";
CM_ SG_ 2566804478 HghLmtThrshldFrMnCntnsTrqFrmRtrd "Maximum allowable value for minimum continuous retarder torque.";
CM_ SG_ 2566804478 LwLmtThrshldFrMxTrqeFromRetarder "Minimum allowable value for maximum continuous retarder torque.";
CM_ SG_ 2566804478 HghLmtThrshldFrMnCntnsRPMFrmRtrd "Maximum allowable value for minimum continuous retarder speed";
CM_ SG_ 2566804478 LwLmtThrshldFrMaxRPMFromRetarder "Minimum allowable value for maximum continuous retarder speed";
CM_ SG_ 2566847486 DrvlineRetarderOverheatIndicator "Signal from the driveline retarder indicating that its fluid temperature is above normal acceptable limits, and as a result, retarder operation may be altered or restricted.  The indicator is typically a lamp.  Distinctions in meaning between the ...";
CM_ SG_ 2566847486 RetarderCoolantOutletTemp "Temperature of liquid found in retarder cooling system.";
CM_ SG_ 2566847486 HydRetarderOilTemp "Temperature of oil found in a hydraulic retarder.";
CM_ SG_ 2566847486 HydRetarderPress "Gage pressure of oil in hydraulic retarder system.";
CM_ BO_ 2631859966 "NOTE—This message requires an Acknowledgement response (See J1939-21, PGN 59392) from the receiving node.  The use of individual proprietary protocols can still be used instead of the \"trip reset\" PGN to maintain security.";
CM_ SG_ 2631859966 SteerStraightAheadPosReset "Used to reset the straight ahead position for a steering sensor in the steering column or a steering controller's straight ahead position on any steerable axle.
00 Take no action - Do not Reset
01 Reset
10 Reserved, take no action
11 Not ...";
CM_ SG_ 2631859966 EngBuildHoursReset "Command signal used to reset the engine rebuild hours.

00 Do not reset
01 Reset
10 Reserved
11 Take no action";
CM_ SG_ 2631859966 EngIgntCtrlMaintenanceHoursReset "Used to reset the maintenance hour counter for an engine ignition control module.  The hours remaining until required maintenance is performed are reported in PGN 64688.

00 Do not reset
01 Reset
10 Reserved
11 Take no action";
CM_ SG_ 2631859966 EngSprkPlgScndVltgeTrackingReset "Command signal used to reset the ignition controller average, maximum, and minimum level tracking of the spark plug secondary voltages and to reset the learned misfire rate.  Average secondary voltage tracking is reported in PGNs 64882 - 64887 ...";
CM_ SG_ 2631859966 ServiceComponentIdentification "Identification of component needing service.  See Table SPN911_A.";
CM_ SG_ 2631859966 TripGroup2Proprietary "Command signal used to reset proprietary parameters associated with a trip but not defined within this document.

00 Take no action
01 Reset
10 Reserved
11 Not applicable";
CM_ SG_ 2631859966 TripGroup1 "Command signal used to reset the PGNs and parameters as defined in Table SPN988_A.

00 Take no action
01 Reset
10 Reserved
11 Not applicable";
CM_ BO_ 2566840830 "This map describes the stationary behavior of the retarder.

Note:  Grandfathered definition for systems that implemented this message prior to July, 2010: On change of torque/speed points of more than 10% since last transmission, or every 5 s.";
CM_ SG_ 2566840830 PercentTorqueAtPeakTorquePoint5 "The torque limit that indicates the available retarder torque which can be provided by the retarder at point 5 of the retarder torque map.  Please reference PGN 65249.  The data is transmitted in indicated torque as a percent of the reference ...";
CM_ SG_ 2566840830 ReferenceRetarderTorque "This parameter is the 100% reference value for all defined indicated retarder torque parameters.  It is only defined once and doesn't change if a different retarder torque map becomes valid.";
CM_ SG_ 2566840830 RetarderSpeedAtPeakTorquePoint5 "Please reference PGN 65249";
CM_ SG_ 2566840830 PercentTorqueAtPoint4 "The torque limit that indicates the available retarder torque which can be provided by the retarder at points 3 and 4 of the retarder torque map.  Please reference PGN 65249.  The data is transmitted in indicated torque as a percent of the reference ...";
CM_ SG_ 2566840830 RetarderSpeedAtPoint4 "Retarder speed of point 4 of the engine retarder torque map.  Please reference PGN 65249.";
CM_ SG_ 2566840830 PercentTorqueAtPoint3 "The torque limit that indicates the available retarder torque which can be provided by the retarder at points 3 and 4 of the retarder torque map.  Please reference PGN 65249.  The data is transmitted in indicated torque as a percent of the reference ...";
CM_ SG_ 2566840830 RetarderSpeedAtPoint3 "Retarder speed of point 3 of the engine retarder torque map.  Please reference PGN 65249.";
CM_ SG_ 2566840830 PercentTorqueAtMaxSpeedPoint2 "The torque limit that indicates the available retarder torque which can be provided by the retarder at its maximum speed.  Please reference PGN 65249.  The data is transmitted in indicated torque as a percent of the reference retarder torque.";
CM_ SG_ 2566840830 MaxRetarderSpeedPoint2 "Maximum speed of retarder (Please reference PGN 65249).";
CM_ SG_ 2566840830 PercentTorqueAtIdlePoint1 "The torque limit that indicates the available retarder torque which can be provided by the retarder at idle speed.  The data is transmitted in indicated torque as a percent of the reference retarder torque.";
CM_ SG_ 2566840830 RetarderSpeedAtIdlePoint1 "Please reference PGN 65249";
CM_ SG_ 2566840830 RetarderCtrlMethod "This parameter identifies the number of steps used by the retarder.";
CM_ SG_ 2566840830 RetarderLocation "This parameter defines whether the “torque/speed curve” defined by the retarder configuration message (PGN 65249) is dependent on engine rpm, output shaft rpm, or other parameter.  The data type of this parameter is measured.
0000   (Primary) ...";
CM_ SG_ 2566840830 RetarderType "A vehicle retarder is a supplementary device to the wheel brakes for the driver to better control the vehicle.  The wheel brakes used in the vehicle are not designed for continuous retarding operation.  In a prolonged period of braking, the brakes ...";
CM_ SG_ 2633930238 EngOperationTimeSinceRebuild "The time in engine operation since the last engine rebuild.";
CM_ SG_ 2566844670 PowerTakeoffSetSpeed "Rotational velocity selected by operator for device used to transmit engine power to auxiliary equipment.";
CM_ SG_ 2566844670 PowerTakeoffSpeed "Rotational velocity of device used to transmit engine power to auxiliary equipment.";
CM_ SG_ 2566844670 PowerTakeoffOilTemp "Temperature of lubricant in device used to transmit engine power to auxiliary equipment.";
CM_ SG_ 2566844670 OprtrEngPTOGvrnrMmrySelectSwitch "Measured state of the operator’s engine PTO governor memory select switch. This switch selects which of the two available memory locations is to be used to store the dynamically assigned value. This speed will be set using the PTO governor set ...";
CM_ SG_ 2566844670 EngRmtPTOGvrnrVrblSpedCtrlSwitch "Switch signal which indicates that the remote PTO governor toggle switch is in the enabled (ON) position.  If the toggle switch is enabled and other conditions are satisfied then the remote PTO governor feature is activated and the PTO governor will ...";
CM_ SG_ 2566844670 EngRmtPTOGvrnrPrprgrmmdSpdCtrlSw "Switch signal which indicates that the remote PTO governor  toggle switch is in the enabled (ON) position.  If the toggle switch is enabled and other conditions are satisfied then the remote PTO governor feature is activated and the PTO governor ...";
CM_ SG_ 2566844670 EngPTOGvrnrCast_DecelerateSwitch "Switch signal of the PTO control activator which indicates that the activator is in the position to \"coast/decelerate\" the PTO governor set speed.

00 - Off
01 - On
10 - Error
11 - Not available";
CM_ SG_ 2566844670 EngPTOGovernorSetSwitch "Switch signal of the PTO control activator which indicates that the activator is in the position to \"set\" the engine PTO governor set speed.

00 - Off
01 - On
10 - Error
11 - Not available";
CM_ SG_ 2566844670 EngPTOGovernorResumeSwitch "Switch signal of the PTO control activator which indicates that the activator is in the position to \"resume\" a previously established PTO governor set speed.

00 - Off
01 - On
10 - Error
11 - Not available";
CM_ SG_ 2566844670 EngPTOGovernorEnableSwitch "Switch signal which indicates that the PTO governor toggle switch is in the enabled (ON) position and therefore it is possible to manage the PTO control function.

00 - Off
01 - On
10 - Error
11 - Not available";
CM_ SG_ 2566844670 EngPTOGovernorAccelerateSwitch "Switch signal of the PTO control activator which indicates that the activator is in the position to \"accelerate\" the PTO governor set speed.

00 - Off
01 - On
10 - Error
11 - Not available";
CM_ SG_ 2566844670 RmtPTOGvrnrPrprgrmmdSpdCtrlSwtch "Switch signal which indicates that the remote PTO governor toggle switch #2 is in the enabled (ON) position. If the toggle switch is enabled and other conditions are satisfied then the remote PTO governor control feature is activated and the PTO ...";
CM_ SG_ 2566844670 AuxInputIgnoreSwitch "Switch signal which overrides other switch input's ability to disable an engine's operating condition.
00 - Off
01 - On
10 - Error
11 - Not Available
This switch input can be used to prevent the PTO from disengaging if another switch input's ...";
CM_ BO_ 2566770174 "Message for items related to the operators controls for the window wipers and washers on the front and rear cab windows";
CM_ SG_ 2566770174 RearWasherFunction "State of operation selected by operator switch for the rear washer.   The parameter, 'Front Operator Washer Switch’ should be used for the control information if this parameter is 'Not Available' and the associated washer still needs to be ...";
CM_ SG_ 2566770174 FrontOperatorWasherSwitch "State of operation selected by operator switch for the washer in front of the operator position. This parameter, 'Front Operator Washer Switch’ should be used for the control information if either of the other washer switch parameters  is 'Not ...";
CM_ SG_ 2566770174 FrontNonoperatorWasherSwitch "State of operation selected by operator switch for the front washer not in front of the operator position.  The parameter, 'Front Operator Washer Switch’ should be used for the control information if this parameter  is 'Not Available' and the ...";
CM_ SG_ 2566770174 RearWiperDelayCtrl "Time between cycles of the rear wiper (i.e. from end of cycle 'n' to start of cycle 'n+1') as selected by the operator control (switch, etc.) in percentage of position with maximum position corresponding to maximum delay selectable.  The parameter, ...";
CM_ SG_ 2566770174 FrontNonoperatorWiperDelayCtrl "Time between cycles of the front non-operator side wiper (i.e. from end of cycle 'n' to start of cycle 'n+1') as selected by the operator control (switch, etc.) in percentage of position with maximum position corresponding to maximum delay ...";
CM_ SG_ 2566770174 FrontOperatorWiperDelayCtrl "Time between cycles of the front operator side wiper (i.e. from end of cycle 'n' to start of cycle 'n+1') as selected by the operator control (switch, etc.) in percentage of position with maximum position corresponding to maximum delay selectable ...";
CM_ SG_ 2566770174 RearWiperSwitch "State of operation selected by operator switch for the rear wiper.  The parameter, 'Front Operator Washer Switch' should be used for the control information if this parameter is 'Not Available' and the associated washer still needs to be controlled.
 ...";
CM_ SG_ 2566770174 FrontOperatorWiperSwitch "State of operation selected by operator switch for the Wiper in front of the operator position. This parameter, 'Front Operator Wiper Switch' should be used for the control information if either of the other wiper switch parameters is 'Not ...";
CM_ SG_ 2566770174 FrontNonoperatorWiperSwitch "State of operation selected by operator switch for the front wiper not in front of the operator position.  The parameter, 'Front Operator Washer Switch' should be used for the control information if this parameter is 'Not Available' and the ...";
CM_ BO_ 2566769662 "Allows for the selection of off-highway engine control modes, as they apply to different modes of engine operation which may be used to aid particular working environments. By offering characteristics suitable for the work in hand, the operator may ...";
CM_ SG_ 2566769662 EngAltDroopAuxInputSelect "In some off-highway applications it may be desirable to have multiple droop settings available across the range of engine operation.  For example, in an agricultural tractor application, this functionality allows a higher engine speed during low ...";
CM_ SG_ 2566769662 EngAltDroopRemoteAccelSelect "In some off-highway applications it may be desirable to have multiple droop settings available across the range of engine operation.  For example, in an agricultural tractor application, this functionality allows a higher engine speed during low ...";
CM_ SG_ 2566769662 EngAltDroopAccel2Select "In some off-highway applications it may be desirable to have multiple droop settings available across the range of engine operation.  For example, in an agricultural tractor application, this functionality allows a higher engine speed during low ...";
CM_ SG_ 2566769662 EngAltDroopAccel1Select "In some off-highway applications it may be desirable to have multiple droop settings available across the range of engine operation.  For example, in an agricultural tractor application, this functionality allows a higher engine speed during low ...";
CM_ SG_ 2566769662 EngAltRatingSelect "In some off-highway applications it may be desirable to have multiple engine ratings available for selection by the operator. There is the default engine rating, which provides the maximum available power across the range of operation. There are ...";
CM_ SG_ 2566769662 EngAltLowIdleSwitch "Operator switch which selects between two low idle speeds, default and alternate.
The normal programmed low idle is the default low idle, and when the Alternate Low Idle switch is activated, a alternate preprogrammed low idle speed is selected. The ...";
CM_ SG_ 2566769662 EngSynchronizationSwitch "This is the On/Off operation of the Multiple Unit Synchronization functionality. When it is enabled (i.e. On) the master engine will synchronize one or more slave engines to operate at the same speed. This switch position indicates whether this ...";
CM_ SG_ 2566769662 EngAuxGovernorSwitch "This is the On/Off operation of the Auxiliary Governor feature switch. This feature is used to allow engine speed to be controlled by an auxiliary input such as pressure or tailshaft speed. This switch position indicates whether this feature is ...";
CM_ BO_ 2566768638 "Reports the states of off-highway engine control modes, as they apply to different modes of engine operation which may be used to aid particular working environments. These states provide the controls feedback for PGN 64971 which provides the ...";
CM_ SG_ 2566768638 EngAltDroopAuxInputSelectState "In some off-highway applications it may be desirable to have multiple droop settings available across the range of engine operation.  For example, in an agricultural tractor application, this functionality allows a higher engine speed during low ...";
CM_ SG_ 2566768638 EngAltDropRemoteAccelSelectState "In some off-highway applications it may be desirable to have multiple droop settings available across the range of engine operation.  For example, in an agricultural tractor application, this functionality allows a higher engine speed during low ...";
CM_ SG_ 2566768638 EngAltDroopAccel2SelectState "In some off-highway applications it may be desirable to have multiple droop settings available across the range of engine operation.  For example, in an agricultural tractor application, this functionality allows a higher engine speed during low ...";
CM_ SG_ 2566768638 EngAltDroopAccel1SelectState "In some off-highway applications it may be desirable to have multiple droop settings available across the range of engine operation.  For example, in an agricultural tractor application, this functionality allows a higher engine speed during low ...";
CM_ SG_ 2566768638 EngAltRatingSelectState "This parameter reflects the control state that has been achieved based on the input from the SPN 2882.  In some off-highway applications it may be desirable to have multiple engine ratings available for selection by the operator.  There is the ...";
CM_ SG_ 2566768638 EngAltLowIdleSelectState "In many applications, it is desirable that an alternate low idle speed setting be made available via switch input. The normal programmed low idle is the default low idle, and when the Alternate Low Idle feature is activated, an alternate ...";
CM_ SG_ 2566768638 EngMultiUnitSyncState "This feature is widely used in Industry to operate multiple engines from a single command source. A master engine will “synchronize” one or more slave engines to operate at the same speed. This feature is requested by an operator switch, this ...";
CM_ SG_ 2566768638 EngAuxGovernorState "This is the Engine Auxiliary Governor feature. This feature is used to allow engine speed to be controlled by an auxiliary input such as pressure or tailshaft speed. This feature is requested by an operator switch, this parameter indicates the state ...";
CM_ BO_ 2365443326 "The message containing the information about the position of the operator's external light control switch(s).  Including switches for the Headlights, turn signals, hazard light, clearance lights, marker lights, etc.";
CM_ SG_ 2365443326 OprtorsDesiredDelayedLampOffTime "A 16 bit parameter to be associated with Delayed Off position (1000 binary) of the Main Light Switch.  This parameter indicates the time the operator wishes to have elapse following the Main Light switch being placed in Delayed Off position before ...";
CM_ SG_ 2365443326 OperatorsDesiredBacklight "A 8 bit parameter to indicate the level of back lighting the operator has selected for displays.  This is to be differentiated from the Illumination Brightness Percent (SPN:1487 PGN:53248 Cab Illumination Message) which is sent to the displays to ...";
CM_ SG_ 2365443326 HighLowBeamSwitch "A 2 bit parameter to indicate the selected position of the operator's high/low beam select switch.

00  Low Beam Selected
01  High Beam Selected
10  Error
11  Not available (do not change)";
CM_ SG_ 2365443326 HazardLightSwitch "A 2 bit parameter to indicate the selected position of the operator's hazard light switch.

00   Hazard Lamps to be Off
01   Hazard Lamps to be Flashing
10   Error
11   Not available (do not change)";
CM_ SG_ 2365443326 TurnSignalSwitch "A 4 bit parameter to indicate the selected position of the operator's turn signal switch.
0000   No Turn being signaled
0001   Left Turn to be Flashing
0010   Right turn to be Flashing
0011 - 1101   Reserved
1110   Error (to include both left ...";
CM_ SG_ 2365443326 MainLightSwitch "A 4 bit parameter to indicate the selected position of the operator's main light switch.
0000 Off - The position by which the operator selects that none of the lamps are to be on.
0001 Park On - The position by which the operator selects that the ...";
CM_ SG_ 2365443326 WorkLightSwitch "A 4 bit parameter to indicate the selected position of the operator's work light switch. In Ag applications the work lights are often refereed to as field lights.  In on-highway applications the work lights are often referred to as clearance lights ...";
CM_ BO_ 2566776318 "Reports the possible maximum vehicle speed limits, one through seven, and the applied maximum vehicle speed limit.";
CM_ SG_ 2566776318 AppliedVehicleSpeedLimit "The vehicle speed limit in effect.

251 (0xFB) is used to indicate that a maximum vehicle speed limit is not selected.";
CM_ SG_ 2566776318 MaxVehicleSpeedLimit7 "The highest of the seven lowest vehicle speed limits";
CM_ SG_ 2566776318 MaxVehicleSpeedLimit6 "The highest of the six lowest vehicle speed limits";
CM_ SG_ 2566776318 MaxVehicleSpeedLimit5 "The highest of the five lowest vehicle speed limits";
CM_ SG_ 2566776318 MaxVehicleSpeedLimit4 "The highest of the four lowest vehicle speed limits";
CM_ SG_ 2566776318 MaxVehicleSpeedLimit3 "The highest of the three lowest vehicle speed limits";
CM_ SG_ 2566776318 MaxVehicleSpeedLimit2 "The highest of the two lowest vehicle speed limits";
CM_ SG_ 2566776318 MaxVehicleSpeedLimit1 "The lowest Maximum Vehicle Speed Limit. This value is the similar to SPN 74. However, SPN 74 was not specifically defined to convey  the applied vehicle speed limit or what was possible to be applied. This new SPN is the lowest vehicle speed limit ...";
CM_ BO_ 2566802686 "The message contains parameters that control military specific lights.";
CM_ SG_ 2566802686 OprtrsBlackOutIntensitySelection "Operators Selection of lamp intensity in black out mode.  This parameter provides the operators selected illumination intensity as a percentage of available full scale.  This parameter would be typically used as a dash or instrument cluster ...";
CM_ SG_ 2566802686 BlackOutWorkLampSelect "Black Out Work Lamp Selection

00 Off
01 On
10 Reserved
11 Not Supported";
CM_ SG_ 2566802686 NightVisionIlluminatorSelect "Night Vision Illuminator Selection

00 Off
01 On
10 Reserved
11 Not Supported";
CM_ SG_ 2566802686 BlackOutBrake_StopLampSelect "Black Out Brake/Stop Lamp Selection

00 Off
01 On
10 Reserved
11 Not Supported";
CM_ SG_ 2566802686 ConvoyDrivingLampSelect "Black Out Convoy Driving Lamp Selection

00 Off
01 On
10 Reserved
11 Not Supported";
CM_ SG_ 2566802686 ConvoyLampSelect "Black Out Convoy Lamp Selection

00 Off
01 On
10 Reserved
11 Not Supported";
CM_ SG_ 2566802686 FrontBlackOutMarkerLampSelect "Front Black Out Marker Lamp Selection

00 Off
01 On
10 Reserved
11 Not Supported";
CM_ SG_ 2566802686 RearBlackOutMarkerSelect "Rear Black Out Marker Selection

00 Off
01 On
10 Reserved
11 Not Supported";
CM_ BO_ 2566774014 "This messages contains marine vessel control information for the engine";
CM_ SG_ 2566774014 SlowVesselModeStatus "The status of the Slow Vessel Mode.  Slow Vessel Mode puts the engine in a lower-than-normal low idle speed during docking or other slow vessel operations.
00 Slow vessel mode is OFF.
01 Slow vessel mode is ACTIVE.
10 Reserved
11 Take no action
 ...";
CM_ SG_ 2566774014 TrollingModeStatus "The status of the Trolling Mode.  Trolling mode limits the top speed.  Full range travel of the throttle level spans from low idle engine speed to maximum trolling speed.
00 Trolling mode is OFF.
01 Trolling mode is ACTIVE.
10 Reserved
11 Take ...";
CM_ SG_ 2566774014 EngThrttlSynchrnzationModeStatus "The status of the Throttle Synchronization Mode. Throttle Synchronization Mode is used to indicate which throttle, if any, is currently being used for the synchronized throttle.
0000 Not Synchronized
0001 Synchronized Center
0010 Synchronized ...";
CM_ SG_ 2566823166 EngMainBearing11Temp "Temperature of the main bearing which supports the crankshaft of the engine.";
CM_ SG_ 2566823166 EngMainBearing10Temp "Temperature of the main bearing which supports the crankshaft of the engine.";
CM_ SG_ 2566823166 EngMainBearing9Temp "Temperature of the main bearing which supports the crankshaft of the engine.";
CM_ SG_ 2566823422 EngMainBearing8Temp "Temperature of the main bearing which supports the crankshaft of the engine.";
CM_ SG_ 2566823422 EngMainBearing7Temp "Temperature of the main bearing which supports the crankshaft of the engine.";
CM_ SG_ 2566823422 EngMainBearing6Temp "Temperature of the main bearing which supports the crankshaft of the engine.";
CM_ SG_ 2566823422 EngMainBearing5Temp "Temperature of the main bearing which supports the crankshaft of the engine.";
CM_ SG_ 2566823678 EngMainBearing4Temp "Temperature of the main bearing which supports the crankshaft of the engine.";
CM_ SG_ 2566823678 EngMainBearing3Temp "Temperature of the main bearing which supports the crankshaft of the engine.";
CM_ SG_ 2566823678 EngMainBearing2Temp "Temperature of the main bearing which supports the crankshaft of the engine.";
CM_ SG_ 2566823678 EngMainBearing1Temp "Temperature of the main bearing which supports the crankshaft of the engine.";
CM_ SG_ 2432595710 DisplayDeadbands "Sets Display Deadbands mode.

0000 - Narrow = +/- 4.5mm
0001 - Standard = +/- 12mm
0010 - Wide = +/- 24mm
0011 - 1110 Reserved
1111 Not Available";
CM_ SG_ 2432595710 LEDPatternCtrl "Sets LED Pattern control mode on laser leveling systems.

0000 - 5 Channel
0001 - Offset
0010 - 7 Channel
0011 - 1110 Reserved
1111 Not Available";
CM_ SG_ 2432595710 LEDDisplayDeadbandCtrl "This parameter informs the system what the selected Display deadband will be.
0000    +/- 4.5 mm  (0.015 feet, 0.18 inches)
0001    +/- 12 mm   (0.040 feet, 0.45 inches)
0010    +/- 24 mm   (0.080 feet, 0.96 inches)
0011    +/- 5  mm    (0.017 ...";
CM_ SG_ 2432595710 LEDDisplayModeCtrl "This parameter informs the system what the selected Display mode will be.
0000 - Center On-Grade Display Mode 1 ( 5 CHANNEL )
0001 - Offset On-Grade Display Mode
0010 - Center On-Grade Display Mode 2 ( 7 CHANNEL )
0011 - 1110 Reserved
1111 - ...";
CM_ SG_ 2432595710 LEDDisplayData1 "Informs display devices how to display the current vertical position.
Values which are less than 128 decimal are bit-mapped values and any combination of these values is considered a valid value.  For example communicating the \"High Fine LED on\" ...";
CM_ SG_ 2365486590 AbsLaserStrikePos "Laser Strike location on the survey type  laser receiver.";
CM_ SG_ 2365486590 LaserStrikeDataLatency "Time from laser strike to CAN message transmission.  This parameter will be reported by survey receiver type devices only. Byte 3 (SPN 2576) of  PGN 65141 identifies the type of Laser Receiver.";
CM_ SG_ 2365486590 LaserReceiverType "Identifies which type of Laser Receiver transmitted the message.

0 = Reserved 
1 = Linear Laser Receiver
2 = 1 Meter Survey Receiver
3 = 2 Meter Survey Receiver
4 = 2.5 Meter Survey Receiver
5-250 = Reserved";
CM_ SG_ 2365486590 LaserStrikeVerticalDeviation "The calculated distance from the laser strike position to the current land leveling system reference point.";
CM_ SG_ 2365485566 LaserTracerInformation "Provides the status of the laser tracer to the operator.
00000001 Laser power is on
00000010 Laser is ready
00000100 Valid target (1 = yes)
00001000 Previous pass (1 = yes)
00010000 Stringline (1 = yes)
00100000 Curb (1 = yes)
All other ...";
CM_ SG_ 2365485566 LEDDisplayData2 "Informs display devices how to display the current position of the laser tracer.
Values which are less than 128 decimal are bit-mapped values and any combination of these values is considered a valid value.  For example communicating the \"Up LED ...";
CM_ SG_ 2365485566 LaserTracerHorizontalDeviation "The calculated percent deviation between the target distance and the center of the laser tracer.";
CM_ SG_ 2365485566 LaserTracerVerticalDistance "The elevation of the laser tracer sensor in a laser leveling system.";
CM_ SG_ 2365485566 LaserTracerTargetDeviation "The calculated distance for the laser target to the current laser tracer reference point.

Parameter specific parameter: 0xFE03 indicates that the sensor can not sense the laser";
CM_ SG_ 2633939454 TripDriveFuelEconomy "Trip drive fuel economy is equal to the distance traveled by vehicle in the drive state (engine speed greater than zero, vehicle speed greater than or equal to 2 km/h, and neither the PTO or remote PTO governors are controlling engine power output) ...";
CM_ SG_ 2633939454 TripCruiseFuelUsed "Total fuel consumed while the engine is in the cruise hold state since the last trip reset.  If both cruise control and VSL (vehicle speed limiter) are commanding the same amount of fuel, the cruise control is deemed the active torque mode and fuel ...";
CM_ SG_ 2633939454 TripVehicleIdleFuelUsed "Total fuel consumed while neither the PTO or remote PTO governor is in the hold state, the engine speed is greater than zero, and vehicle speed is less than 2 km/h, since the last trip reset.
In marine applications, this parameter is defined as the ...";
CM_ SG_ 2633939454 TripPTOGovernorNonmovingFuelUsed "Total fuel consumed while either the PTO or remote PTO governors are in the hold state, the engine speed is greater than zero, and vehicle speed is less than 2 km/h, since the last trip reset.
NOTE—This parameter is intended for liquid fueled ...";
CM_ SG_ 2633939454 TripPTOGovernorMovingFuelUsed "Total fuel consumed while either the PTO or remote PTO governors are in the hold state, the engine speed is greater than zero, and vehicle speed is greater than or equal to 2 km/h, since the last trip reset.
NOTE—This parameter is intended for ...";
CM_ SG_ 2633939454 TripDriveFuelUsed "Total fuel consumed while the engine speed is greater than zero, vehicle speed is greater than or equal to 2 km/h, and neither the PTO or the remote PTO is controlling the engine power output, since the last trip reset.
NOTE—This parameter is ...";
CM_ SG_ 2365486334 BldeHeightSetPointHighResolution "High resolution for the laser guided blade set point.  The high resolution required for more accurate control and 'accurate' unit conversions.

Negative values are below grade, positive values are above grade, zero is on grade.";
CM_ SG_ 2365486334 ModifyLevelingSystemSetPoint "Used to control and coordinate the set point for the leveling system.
Operating Range: -3200 to +3200 mm, negative values are below current position, positive values are above current position, zero is no change.
Parameter specific parameter:
 ...";
BA_DEF_ SG_  "SigType" ENUM  "Default","Range","RangeSigned","ASCII","Discrete","Control","ReferencePGN","DTC","StringDelimiter","StringLength","StringLengthControl","MessageCounter","MessageChecksum";
BA_DEF_ SG_  "GenSigStartValue" INT 0 10000;
BA_DEF_ SG_  "GenSigSendType" ENUM  "Cyclic","OnWrite","OnWriteWithRepetition","OnChange","OnChangeWithRepetition","IfActive","IfActiveWithRepetition","NoSigSendType";
BA_DEF_ SG_  "GenSigILSupport" ENUM  "No","Yes";
BA_DEF_ SG_  "GenSigEVName" STRING ;
BA_DEF_ SG_  "SPN" INT 0 524287;
BA_DEF_ BO_  "GenMsgStartDelayTime" INT 0 100000;
BA_DEF_ BO_  "GenMsgILSupport" ENUM  "No","Yes";
BA_DEF_ BO_  "GenMsgRequestable" INT 0 1;
BA_DEF_ BO_  "GenMsgSendType" ENUM  "cyclic","NotUsed","NotUsed","NotUsed","NotUsed","NotUsed","NotUsed","IfActive","noMsgSendType";
BA_DEF_ BO_  "VFrameFormat" ENUM  "StandardCAN","ExtendedCAN","reserved","J1939PG";
BA_DEF_ BO_  "GenMsgCycleTime" INT 0 3600000;
BA_DEF_ SG_  "SystemSignalLongSymbol" STRING ;
BA_DEF_DEF_  "SigType" "Default";
BA_DEF_DEF_  "GenSigStartValue" 0;
BA_DEF_DEF_  "GenSigSendType" "NoSigSendType";
BA_DEF_DEF_  "GenSigILSupport" "Yes";
BA_DEF_DEF_  "GenSigEVName" "Env@Nodename_@Signame";
BA_DEF_DEF_  "SPN" 0;
BA_DEF_DEF_  "GenMsgStartDelayTime" 0;
BA_DEF_DEF_  "GenMsgILSupport" "Yes";
BA_DEF_DEF_  "GenMsgRequestable" 1;
BA_DEF_DEF_  "GenMsgSendType" "noMsgSendType";
BA_DEF_DEF_  "VFrameFormat" "J1939PG";
BA_DEF_DEF_  "GenMsgCycleTime" 0;
BA_DEF_DEF_  "SystemSignalLongSymbol" "";
BA_ "GenMsgSendType" BO_ 2566845694 0;
BA_ "GenMsgCycleTime" BO_ 2566845694 10000;
BA_ "GenMsgSendType" BO_ 2566821630 0;
BA_ "GenMsgCycleTime" BO_ 2566821630 100;
BA_ "GenMsgSendType" BO_ 2365484286 0;
BA_ "GenMsgCycleTime" BO_ 2365484286 50;
BA_ "GenMsgSendType" BO_ 2566771710 0;
BA_ "GenMsgCycleTime" BO_ 2566771710 1000;
BA_ "GenMsgSendType" BO_ 2566821886 0;
BA_ "GenMsgCycleTime" BO_ 2566821886 1000;
BA_ "GenMsgSendType" BO_ 2566822142 0;
BA_ "GenMsgCycleTime" BO_ 2566822142 1000;
BA_ "GenMsgSendType" BO_ 2566822398 0;
BA_ "GenMsgCycleTime" BO_ 2566822398 1000;
BA_ "GenMsgSendType" BO_ 2566822654 0;
BA_ "GenMsgCycleTime" BO_ 2566822654 1000;
BA_ "GenMsgSendType" BO_ 2633931774 0;
BA_ "GenMsgCycleTime" BO_ 2633931774 1000;
BA_ "GenMsgSendType" BO_ 2566802430 0;
BA_ "GenMsgCycleTime" BO_ 2566802430 5000;
BA_ "GenMsgSendType" BO_ 2348941054 2;
BA_ "GenMsgCycleTime" BO_ 2348941054 50;
BA_ "GenMsgSendType" BO_ 2566839806 0;
BA_ "GenMsgCycleTime" BO_ 2566839806 1000;
BA_ "GenMsgSendType" BO_ 2566775550 2;
BA_ "GenMsgCycleTime" BO_ 2566775550 1000;
BA_ "GenMsgSendType" BO_ 2566819838 0;
BA_ "GenMsgCycleTime" BO_ 2566819838 1000;
BA_ "GenMsgSendType" BO_ 2566841598 0;
BA_ "GenMsgCycleTime" BO_ 2566841598 1000;
BA_ "GenMsgSendType" BO_ 2566804478 0;
BA_ "GenMsgCycleTime" BO_ 2566804478 5000;
BA_ "GenMsgSendType" BO_ 2566847486 0;
BA_ "GenMsgCycleTime" BO_ 2566847486 1000;
BA_ "GenMsgSendType" BO_ 2566840830 0;
BA_ "GenMsgCycleTime" BO_ 2566840830 5000;
BA_ "GenMsgSendType" BO_ 2566844670 0;
BA_ "GenMsgCycleTime" BO_ 2566844670 100;
BA_ "GenMsgSendType" BO_ 2566770174 0;
BA_ "GenMsgCycleTime" BO_ 2566770174 200;
BA_ "GenMsgSendType" BO_ 2566769662 0;
BA_ "GenMsgCycleTime" BO_ 2566769662 500;
BA_ "GenMsgSendType" BO_ 2566768638 0;
BA_ "GenMsgCycleTime" BO_ 2566768638 5000;
BA_ "GenMsgSendType" BO_ 2365443326 0;
BA_ "GenMsgCycleTime" BO_ 2365443326 1000;
BA_ "GenMsgSendType" BO_ 2566776318 0;
BA_ "GenMsgCycleTime" BO_ 2566776318 1000;
BA_ "GenMsgSendType" BO_ 2566802686 0;
BA_ "GenMsgCycleTime" BO_ 2566802686 500;
BA_ "GenMsgSendType" BO_ 2566774014 0;
BA_ "GenMsgCycleTime" BO_ 2566774014 1000;
BA_ "GenMsgSendType" BO_ 2566823166 0;
BA_ "GenMsgCycleTime" BO_ 2566823166 1000;
BA_ "GenMsgSendType" BO_ 2566823422 0;
BA_ "GenMsgCycleTime" BO_ 2566823422 1000;
BA_ "GenMsgSendType" BO_ 2566823678 0;
BA_ "GenMsgCycleTime" BO_ 2566823678 1000;
BA_ "GenMsgSendType" BO_ 2432595710 0;
BA_ "GenMsgCycleTime" BO_ 2432595710 100;
BA_ "GenMsgSendType" BO_ 2365486590 0;
BA_ "GenMsgCycleTime" BO_ 2365486590 50;
BA_ "GenMsgSendType" BO_ 2365485566 0;
BA_ "GenMsgCycleTime" BO_ 2365485566 50;
BA_ "GenMsgSendType" BO_ 2365486334 0;
BA_ "GenMsgCycleTime" BO_ 2365486334 50;
BA_ "SPN" SG_ 2566845694 TirePressThresholdDetection_13 521613;
BA_ "SPN" SG_ 2566845694 TirePressThresholdDetection_12 521612;
BA_ "SPN" SG_ 2566845694 TirePressThresholdDetection_11 521611;
BA_ "SPN" SG_ 2566845694 TirePressThresholdDetection_10 521610;
BA_ "SPN" SG_ 2566845694 TirePressThresholdDetection_01 521601;
BA_ "SigType" SG_ 2566845694 TirePress_33 1;
BA_ "SPN" SG_ 2566845694 TirePress_33 521033;
BA_ "SigType" SG_ 2566845694 TirePress_32 1;
BA_ "SPN" SG_ 2566845694 TirePress_32 521032;
BA_ "SigType" SG_ 2566845694 TirePress_31 1;
BA_ "SPN" SG_ 2566845694 TirePress_31 521031;
BA_ "SigType" SG_ 2566845694 TirePress_30 1;
BA_ "SPN" SG_ 2566845694 TirePress_30 521030;
BA_ "SigType" SG_ 2566845694 TirePress_23 1;
BA_ "SPN" SG_ 2566845694 TirePress_23 521023;
BA_ "SigType" SG_ 2566845694 TirePress_22 1;
BA_ "SPN" SG_ 2566845694 TirePress_22 521022;
BA_ "SigType" SG_ 2566845694 TirePress_21 1;
BA_ "SPN" SG_ 2566845694 TirePress_21 521021;
BA_ "SigType" SG_ 2566845694 TirePress_20 1;
BA_ "SPN" SG_ 2566845694 TirePress_20 521020;
BA_ "SigType" SG_ 2566845694 TirePress_13 1;
BA_ "SPN" SG_ 2566845694 TirePress_13 521013;
BA_ "SigType" SG_ 2566845694 TirePress_12 1;
BA_ "SPN" SG_ 2566845694 TirePress_12 521012;
BA_ "SigType" SG_ 2566845694 TirePress_11 1;
BA_ "SPN" SG_ 2566845694 TirePress_11 521011;
BA_ "SigType" SG_ 2566845694 TirePress_10 1;
BA_ "SPN" SG_ 2566845694 TirePress_10 521010;
BA_ "SigType" SG_ 2566845694 TireAirLeakageRate_33 1;
BA_ "SPN" SG_ 2566845694 TireAirLeakageRate_33 521533;
BA_ "SigType" SG_ 2566845694 TireAirLeakageRate_32 1;
BA_ "SPN" SG_ 2566845694 TireAirLeakageRate_32 521532;
BA_ "SigType" SG_ 2566845694 TireAirLeakageRate_31 1;
BA_ "SPN" SG_ 2566845694 TireAirLeakageRate_31 521531;
BA_ "SigType" SG_ 2566845694 TireAirLeakageRate_30 1;
BA_ "SPN" SG_ 2566845694 TireAirLeakageRate_30 521530;
BA_ "SigType" SG_ 2566845694 TireAirLeakageRate_23 1;
BA_ "SPN" SG_ 2566845694 TireAirLeakageRate_23 521523;
BA_ "SigType" SG_ 2566845694 TireAirLeakageRate_22 1;
BA_ "SPN" SG_ 2566845694 TireAirLeakageRate_22 521522;
BA_ "SigType" SG_ 2566845694 TireAirLeakageRate_21 1;
BA_ "SPN" SG_ 2566845694 TireAirLeakageRate_21 521521;
BA_ "SigType" SG_ 2566845694 TireAirLeakageRate_20 1;
BA_ "SPN" SG_ 2566845694 TireAirLeakageRate_20 521520;
BA_ "SigType" SG_ 2566845694 TireAirLeakageRate_13 1;
BA_ "SPN" SG_ 2566845694 TireAirLeakageRate_13 521513;
BA_ "SigType" SG_ 2566845694 TireAirLeakageRate_12 1;
BA_ "SPN" SG_ 2566845694 TireAirLeakageRate_12 521512;
BA_ "SigType" SG_ 2566845694 TireAirLeakageRate_11 1;
BA_ "SPN" SG_ 2566845694 TireAirLeakageRate_11 521511;
BA_ "SigType" SG_ 2566845694 TireAirLeakageRate_10 1;
BA_ "SPN" SG_ 2566845694 TireAirLeakageRate_10 521510;
BA_ "SigType" SG_ 2566845694 TireAirLeakageRate_01 1;
BA_ "SPN" SG_ 2566845694 TireAirLeakageRate_01 521501;
BA_ "SigType" SG_ 2566845694 TireAirLeakageRate_00 1;
BA_ "SPN" SG_ 2566845694 TireAirLeakageRate_00 521500;
BA_ "SigType" SG_ 2566845694 CTIWheelSensorStatus_33 4;
BA_ "SPN" SG_ 2566845694 CTIWheelSensorStatus_33 521433;
BA_ "SigType" SG_ 2566845694 CTIWheelSensorStatus_32 4;
BA_ "SPN" SG_ 2566845694 CTIWheelSensorStatus_32 521432;
BA_ "SigType" SG_ 2566845694 CTIWheelSensorStatus_31 4;
BA_ "SPN" SG_ 2566845694 CTIWheelSensorStatus_31 521431;
BA_ "SigType" SG_ 2566845694 CTIWheelSensorStatus_30 4;
BA_ "SPN" SG_ 2566845694 CTIWheelSensorStatus_30 521430;
BA_ "SigType" SG_ 2566845694 CTIWheelSensorStatus_23 4;
BA_ "SPN" SG_ 2566845694 CTIWheelSensorStatus_23 521423;
BA_ "SigType" SG_ 2566845694 CTIWheelSensorStatus_22 4;
BA_ "SPN" SG_ 2566845694 CTIWheelSensorStatus_22 521422;
BA_ "SigType" SG_ 2566845694 CTIWheelSensorStatus_21 4;
BA_ "SPN" SG_ 2566845694 CTIWheelSensorStatus_21 521421;
BA_ "SigType" SG_ 2566845694 CTIWheelSensorStatus_20 4;
BA_ "SPN" SG_ 2566845694 CTIWheelSensorStatus_20 521420;
BA_ "SigType" SG_ 2566845694 CTIWheelSensorStatus_13 4;
BA_ "SPN" SG_ 2566845694 CTIWheelSensorStatus_13 521413;
BA_ "SigType" SG_ 2566845694 CTIWheelSensorStatus_12 4;
BA_ "SPN" SG_ 2566845694 CTIWheelSensorStatus_12 521412;
BA_ "SigType" SG_ 2566845694 CTIWheelSensorStatus_11 4;
BA_ "SPN" SG_ 2566845694 CTIWheelSensorStatus_11 521411;
BA_ "SigType" SG_ 2566845694 CTIWheelSensorStatus_10 4;
BA_ "SPN" SG_ 2566845694 CTIWheelSensorStatus_10 521410;
BA_ "SigType" SG_ 2566845694 CTIWheelSensorStatus_01 4;
BA_ "SPN" SG_ 2566845694 CTIWheelSensorStatus_01 521401;
BA_ "SigType" SG_ 2566845694 CTIWheelEndElectricalFault_33 4;
BA_ "SPN" SG_ 2566845694 CTIWheelEndElectricalFault_33 521233;
BA_ "SigType" SG_ 2566845694 CTIWheelEndElectricalFault_32 4;
BA_ "SPN" SG_ 2566845694 CTIWheelEndElectricalFault_32 521232;
BA_ "SigType" SG_ 2566845694 CTIWheelEndElectricalFault_31 4;
BA_ "SPN" SG_ 2566845694 CTIWheelEndElectricalFault_31 521231;
BA_ "SigType" SG_ 2566845694 CTIWheelEndElectricalFault_30 4;
BA_ "SPN" SG_ 2566845694 CTIWheelEndElectricalFault_30 521230;
BA_ "SigType" SG_ 2566845694 CTIWheelEndElectricalFault_23 4;
BA_ "SPN" SG_ 2566845694 CTIWheelEndElectricalFault_23 521223;
BA_ "SigType" SG_ 2566845694 CTIWheelEndElectricalFault_22 4;
BA_ "SPN" SG_ 2566845694 CTIWheelEndElectricalFault_22 521222;
BA_ "SigType" SG_ 2566845694 CTIWheelEndElectricalFault_21 4;
BA_ "SPN" SG_ 2566845694 CTIWheelEndElectricalFault_21 521221;
BA_ "SigType" SG_ 2566845694 CTIWheelEndElectricalFault_20 4;
BA_ "SPN" SG_ 2566845694 CTIWheelEndElectricalFault_20 521220;
BA_ "SigType" SG_ 2566845694 CTIWheelEndElectricalFault_13 4;
BA_ "SPN" SG_ 2566845694 CTIWheelEndElectricalFault_13 521213;
BA_ "SigType" SG_ 2566845694 CTIWheelEndElectricalFault_12 4;
BA_ "SPN" SG_ 2566845694 CTIWheelEndElectricalFault_12 521212;
BA_ "SigType" SG_ 2566845694 CTIWheelEndElectricalFault_11 4;
BA_ "SPN" SG_ 2566845694 CTIWheelEndElectricalFault_11 521211;
BA_ "SigType" SG_ 2566845694 CTIWheelEndElectricalFault_10 4;
BA_ "SPN" SG_ 2566845694 CTIWheelEndElectricalFault_10 521210;
BA_ "SigType" SG_ 2566845694 CTIWheelEndElectricalFault_01 4;
BA_ "SPN" SG_ 2566845694 CTIWheelEndElectricalFault_01 521201;
BA_ "SigType" SG_ 2566845694 CTITireStatus_33 4;
BA_ "SPN" SG_ 2566845694 CTITireStatus_33 521333;
BA_ "SigType" SG_ 2566845694 CTITireStatus_32 4;
BA_ "SPN" SG_ 2566845694 CTITireStatus_32 521332;
BA_ "SigType" SG_ 2566845694 CTITireStatus_31 4;
BA_ "SPN" SG_ 2566845694 CTITireStatus_31 521331;
BA_ "SigType" SG_ 2566845694 CTITireStatus_30 4;
BA_ "SPN" SG_ 2566845694 CTITireStatus_30 521330;
BA_ "SigType" SG_ 2566845694 CTITireStatus_23 4;
BA_ "SPN" SG_ 2566845694 CTITireStatus_23 521323;
BA_ "SigType" SG_ 2566845694 CTITireStatus_22 4;
BA_ "SPN" SG_ 2566845694 CTITireStatus_22 521322;
BA_ "SigType" SG_ 2566845694 CTITireStatus_21 4;
BA_ "SPN" SG_ 2566845694 CTITireStatus_21 521321;
BA_ "SigType" SG_ 2566845694 CTITireStatus_20 4;
BA_ "SPN" SG_ 2566845694 CTITireStatus_20 521320;
BA_ "SigType" SG_ 2566845694 CTITireStatus_13 4;
BA_ "SPN" SG_ 2566845694 CTITireStatus_13 521313;
BA_ "SigType" SG_ 2566845694 CTITireStatus_12 4;
BA_ "SPN" SG_ 2566845694 CTITireStatus_12 521312;
BA_ "SigType" SG_ 2566845694 CTITireStatus_11 4;
BA_ "SPN" SG_ 2566845694 CTITireStatus_11 521311;
BA_ "SigType" SG_ 2566845694 CTITireStatus_10 4;
BA_ "SPN" SG_ 2566845694 CTITireStatus_10 521310;
BA_ "SigType" SG_ 2566845694 CTITireStatus_01 4;
BA_ "SPN" SG_ 2566845694 CTITireStatus_01 521301;
BA_ "SigType" SG_ 2566845694 TireTemp_11 1;
BA_ "SPN" SG_ 2566845694 TireTemp_11 521111;
BA_ "SigType" SG_ 2566845694 TireTemp_33 1;
BA_ "SPN" SG_ 2566845694 TireTemp_33 521133;
BA_ "SigType" SG_ 2566845694 TireTemp_32 1;
BA_ "SPN" SG_ 2566845694 TireTemp_32 521132;
BA_ "SigType" SG_ 2566845694 TireTemp_31 1;
BA_ "SPN" SG_ 2566845694 TireTemp_31 521131;
BA_ "SigType" SG_ 2566845694 TireTemp_30 1;
BA_ "SPN" SG_ 2566845694 TireTemp_30 521130;
BA_ "SigType" SG_ 2566845694 TireTemp_23 1;
BA_ "SPN" SG_ 2566845694 TireTemp_23 521123;
BA_ "SigType" SG_ 2566845694 TireTemp_22 1;
BA_ "SPN" SG_ 2566845694 TireTemp_22 521122;
BA_ "SigType" SG_ 2566845694 TireTemp_21 1;
BA_ "SPN" SG_ 2566845694 TireTemp_21 521121;
BA_ "SigType" SG_ 2566845694 TireTemp_20 1;
BA_ "SPN" SG_ 2566845694 TireTemp_20 521120;
BA_ "SigType" SG_ 2566845694 TireTemp_13 1;
BA_ "SPN" SG_ 2566845694 TireTemp_13 521113;
BA_ "SigType" SG_ 2566845694 TireTemp_12 1;
BA_ "SPN" SG_ 2566845694 TireTemp_12 521112;
BA_ "SigType" SG_ 2566845694 TireTemp_10 1;
BA_ "SPN" SG_ 2566845694 TireTemp_10 521110;
BA_ "SigType" SG_ 2566845694 TireTemp_01 1;
BA_ "SPN" SG_ 2566845694 TireTemp_01 521101;
BA_ "SigType" SG_ 2566845694 TireTemp_00 1;
BA_ "SPN" SG_ 2566845694 TireTemp_00 521100;
BA_ "SPN" SG_ 2566845694 TirePressThresholdDetection_33 521633;
BA_ "SPN" SG_ 2566845694 TirePressThresholdDetection_32 521632;
BA_ "SPN" SG_ 2566845694 TirePressThresholdDetection_31 521631;
BA_ "SPN" SG_ 2566845694 TirePressThresholdDetection_30 521630;
BA_ "SPN" SG_ 2566845694 TirePressThresholdDetection_23 521623;
BA_ "SPN" SG_ 2566845694 TirePressThresholdDetection_22 521622;
BA_ "SPN" SG_ 2566845694 TirePressThresholdDetection_21 521621;
BA_ "SPN" SG_ 2566845694 TirePressThresholdDetection_20 521620;
BA_ "SPN" SG_ 2566845694 TirePressThresholdDetection_00 521600;
BA_ "SigType" SG_ 2566845694 TirePress_01 1;
BA_ "SPN" SG_ 2566845694 TirePress_01 521001;
BA_ "SigType" SG_ 2566845694 TirePress_00 1;
BA_ "SPN" SG_ 2566845694 TirePress_00 521000;
BA_ "SigType" SG_ 2566845694 CTIWheelSensorStatus_00 4;
BA_ "SPN" SG_ 2566845694 CTIWheelSensorStatus_00 521400;
BA_ "SigType" SG_ 2566845694 CTIWheelEndElectricalFault_00 4;
BA_ "SPN" SG_ 2566845694 CTIWheelEndElectricalFault_00 521200;
BA_ "SigType" SG_ 2566845694 CTITireStatus_00 4;
BA_ "SPN" SG_ 2566845694 CTITireStatus_00 521300;
BA_ "SPN" SG_ 2566845694 TireLocation 929;
BA_ "SigType" SG_ 2633939966 TripFanOnTimeDueToTheA_CSystem 1;
BA_ "SPN" SG_ 2633939966 TripFanOnTimeDueToTheA_CSystem 997;
BA_ "SigType" SG_ 2633939966 TripFanOnTimeDueToAManualSwitch 1;
BA_ "SPN" SG_ 2633939966 TripFanOnTimeDueToAManualSwitch 996;
BA_ "SigType" SG_ 2633939966 TripFanOnTimeDueToTheEngSystem 1;
BA_ "SPN" SG_ 2633939966 TripFanOnTimeDueToTheEngSystem 995;
BA_ "SigType" SG_ 2633939966 TripFanOnTime 1;
BA_ "SPN" SG_ 2633939966 TripFanOnTime 994;
BA_ "SigType" SG_ 2633939710 TripDistanceInTopGear 1;
BA_ "SPN" SG_ 2633939710 TripDistanceInTopGear 1000;
BA_ "SigType" SG_ 2633939710 TripGearDownDistance 1;
BA_ "SPN" SG_ 2633939710 TripGearDownDistance 999;
BA_ "SigType" SG_ 2633939710 TripDistanceOnVSL 1;
BA_ "SPN" SG_ 2633939710 TripDistanceOnVSL 998;
BA_ "SigType" SG_ 2564161278 AdjustLocalHourOffset 1;
BA_ "GenSigStartValue" SG_ 2564161278 AdjustLocalHourOffset 101;
BA_ "SPN" SG_ 2564161278 AdjustLocalHourOffset 1610;
BA_ "SigType" SG_ 2564161278 AdjustLocalMinuteOffset 1;
BA_ "GenSigStartValue" SG_ 2564161278 AdjustLocalMinuteOffset 66;
BA_ "SPN" SG_ 2564161278 AdjustLocalMinuteOffset 1609;
BA_ "SigType" SG_ 2564161278 AdjustYear 1;
BA_ "SPN" SG_ 2564161278 AdjustYear 1608;
BA_ "SigType" SG_ 2564161278 AdjustDay 1;
BA_ "GenSigStartValue" SG_ 2564161278 AdjustDay 1;
BA_ "SPN" SG_ 2564161278 AdjustDay 1607;
BA_ "SigType" SG_ 2564161278 AdjustMonth 1;
BA_ "GenSigStartValue" SG_ 2564161278 AdjustMonth 1;
BA_ "SPN" SG_ 2564161278 AdjustMonth 1606;
BA_ "SigType" SG_ 2564161278 AdjustHours 1;
BA_ "SPN" SG_ 2564161278 AdjustHours 1605;
BA_ "SigType" SG_ 2564161278 AdjustMinutes 1;
BA_ "SPN" SG_ 2564161278 AdjustMinutes 1604;
BA_ "SigType" SG_ 2564161278 AdjustSeconds 1;
BA_ "SPN" SG_ 2564161278 AdjustSeconds 1603;
BA_ "SigType" SG_ 2566842110 LocalHourOffset 1;
BA_ "GenSigStartValue" SG_ 2566842110 LocalHourOffset 102;
BA_ "SPN" SG_ 2566842110 LocalHourOffset 1602;
BA_ "SigType" SG_ 2566842110 LocalMinuteOffset 1;
BA_ "GenSigStartValue" SG_ 2566842110 LocalMinuteOffset 66;
BA_ "SPN" SG_ 2566842110 LocalMinuteOffset 1601;
BA_ "SigType" SG_ 2566842110 Year 1;
BA_ "SPN" SG_ 2566842110 Year 964;
BA_ "SigType" SG_ 2566842110 Day 1;
BA_ "GenSigStartValue" SG_ 2566842110 Day 1;
BA_ "SPN" SG_ 2566842110 Day 962;
BA_ "SigType" SG_ 2566842110 Month 1;
BA_ "GenSigStartValue" SG_ 2566842110 Month 1;
BA_ "SPN" SG_ 2566842110 Month 963;
BA_ "SigType" SG_ 2566842110 Hours 1;
BA_ "SPN" SG_ 2566842110 Hours 961;
BA_ "SigType" SG_ 2566842110 Minutes 1;
BA_ "SPN" SG_ 2566842110 Minutes 960;
BA_ "SigType" SG_ 2566842110 Seconds 1;
BA_ "SPN" SG_ 2566842110 Seconds 959;
BA_ "SigType" SG_ 2566821630 EngDsrdTrboWastegateActuator2Pos 1;
BA_ "SPN" SG_ 2566821630 EngDsrdTrboWastegateActuator2Pos 5373;
BA_ "SPN" SG_ 2566821630 EngTrbWstgateActuator1TempStatus 5372;
BA_ "SPN" SG_ 2566821630 EngTrbWstgtActtor1PreliminaryFMI 5371;
BA_ "SigType" SG_ 2566821630 EngDsrdTrboWastegateActuator1Pos 1;
BA_ "SPN" SG_ 2566821630 EngDsrdTrboWastegateActuator1Pos 5370;
BA_ "SigType" SG_ 2566821630 EngTrbWstgteActuatorCtrlAirPress 1;
BA_ "SPN" SG_ 2566821630 EngTrbWstgteActuatorCtrlAirPress 1192;
BA_ "SigType" SG_ 2566821630 EngTurboWastegateActuator4Pos 1;
BA_ "SPN" SG_ 2566821630 EngTurboWastegateActuator4Pos 1191;
BA_ "SigType" SG_ 2566821630 EngTurboWastegateActuator3Pos 1;
BA_ "SPN" SG_ 2566821630 EngTurboWastegateActuator3Pos 1190;
BA_ "SigType" SG_ 2566821630 EngTurboWastegateActuator2Pos 1;
BA_ "SPN" SG_ 2566821630 EngTurboWastegateActuator2Pos 1189;
BA_ "SigType" SG_ 2566821630 EngTurboWastegateActuator1Pos 1;
BA_ "SPN" SG_ 2566821630 EngTurboWastegateActuator1Pos 1188;
BA_ "SigType" SG_ 2365484286 TachographVehicleSpeed 1;
BA_ "SPN" SG_ 2365484286 TachographVehicleSpeed 1624;
BA_ "SigType" SG_ 2365484286 TachographOutputShaftSpeed 1;
BA_ "SPN" SG_ 2365484286 TachographOutputShaftSpeed 1623;
BA_ "SigType" SG_ 2365484286 DirectionIndicator 4;
BA_ "SPN" SG_ 2365484286 DirectionIndicator 1619;
BA_ "SigType" SG_ 2365484286 TachographPerformance 5;
BA_ "SPN" SG_ 2365484286 TachographPerformance 1620;
BA_ "SigType" SG_ 2365484286 HandlingInformation 5;
BA_ "SPN" SG_ 2365484286 HandlingInformation 1621;
BA_ "SigType" SG_ 2365484286 SystemEvent 5;
BA_ "SPN" SG_ 2365484286 SystemEvent 1622;
BA_ "SigType" SG_ 2365484286 DriverCardDriver2 4;
BA_ "SPN" SG_ 2365484286 DriverCardDriver2 1616;
BA_ "SPN" SG_ 2365484286 Driver2TimeRelatedStates 1618;
BA_ "SigType" SG_ 2365484286 VehicleOverspeed 4;
BA_ "SPN" SG_ 2365484286 VehicleOverspeed 1614;
BA_ "SigType" SG_ 2365484286 DriverCardDriver1 4;
BA_ "SPN" SG_ 2365484286 DriverCardDriver1 1615;
BA_ "SPN" SG_ 2365484286 Driver1TimeRelatedStates 1617;
BA_ "SigType" SG_ 2365484286 VehicleMotion 4;
BA_ "SPN" SG_ 2365484286 VehicleMotion 1611;
BA_ "SPN" SG_ 2365484286 Driver2WorkingState 1613;
BA_ "SPN" SG_ 2365484286 Driver1WorkingState 1612;
BA_ "SigType" SG_ 2566771710 EngTurbo4CompressorOutletTemp 1;
BA_ "SPN" SG_ 2566771710 EngTurbo4CompressorOutletTemp 2801;
BA_ "SigType" SG_ 2566771710 EngTurbo3CompressorOutletTemp 1;
BA_ "SPN" SG_ 2566771710 EngTurbo3CompressorOutletTemp 2800;
BA_ "SigType" SG_ 2566771710 EngTurbo2CompressorOutletTemp 1;
BA_ "SPN" SG_ 2566771710 EngTurbo2CompressorOutletTemp 2799;
BA_ "SigType" SG_ 2566771710 EngTurbo1CompressorOutletTemp 1;
BA_ "SPN" SG_ 2566771710 EngTurbo1CompressorOutletTemp 2629;
BA_ "SigType" SG_ 2566821886 EngTurbo4TurbineOutletTemp 1;
BA_ "SPN" SG_ 2566821886 EngTurbo4TurbineOutletTemp 1187;
BA_ "SigType" SG_ 2566821886 EngTurbo3TurbineOutletTemp 1;
BA_ "SPN" SG_ 2566821886 EngTurbo3TurbineOutletTemp 1186;
BA_ "SigType" SG_ 2566821886 EngTurbo2TurbineOutletTemp 1;
BA_ "SPN" SG_ 2566821886 EngTurbo2TurbineOutletTemp 1185;
BA_ "SigType" SG_ 2566821886 EngTurbo1TurbineOutletTemp 1;
BA_ "SPN" SG_ 2566821886 EngTurbo1TurbineOutletTemp 1184;
BA_ "SigType" SG_ 2566822142 EngTurbo4TurbineIntakeTemp 1;
BA_ "SPN" SG_ 2566822142 EngTurbo4TurbineIntakeTemp 1183;
BA_ "SigType" SG_ 2566822142 EngTurbo3TurbineIntakeTemp 1;
BA_ "SPN" SG_ 2566822142 EngTurbo3TurbineIntakeTemp 1182;
BA_ "SigType" SG_ 2566822142 EngTurbo2TurbineIntakeTemp 1;
BA_ "SPN" SG_ 2566822142 EngTurbo2TurbineIntakeTemp 1181;
BA_ "SigType" SG_ 2566822142 EngTurbo1TurbineIntakeTemp 1;
BA_ "SPN" SG_ 2566822142 EngTurbo1TurbineIntakeTemp 1180;
BA_ "SigType" SG_ 2566822398 EngTurbo4CompressorIntakePress 1;
BA_ "SPN" SG_ 2566822398 EngTurbo4CompressorIntakePress 1179;
BA_ "SigType" SG_ 2566822398 EngTurbo3CompressorIntakePress 1;
BA_ "SPN" SG_ 2566822398 EngTurbo3CompressorIntakePress 1178;
BA_ "SigType" SG_ 2566822398 EngTurbo2CompressorIntakePress 1;
BA_ "SPN" SG_ 2566822398 EngTurbo2CompressorIntakePress 1177;
BA_ "SigType" SG_ 2566822398 EngTurbo1CompressorIntakePress 1;
BA_ "SPN" SG_ 2566822398 EngTurbo1CompressorIntakePress 1176;
BA_ "SigType" SG_ 2566822654 EngTurbo4CompressorIntakeTemp 1;
BA_ "SPN" SG_ 2566822654 EngTurbo4CompressorIntakeTemp 1175;
BA_ "SigType" SG_ 2566822654 EngTurbo3CompressorIntakeTemp 1;
BA_ "SPN" SG_ 2566822654 EngTurbo3CompressorIntakeTemp 1174;
BA_ "SigType" SG_ 2566822654 EngTurbo2CompressorIntakeTemp 1;
BA_ "SPN" SG_ 2566822654 EngTurbo2CompressorIntakeTemp 1173;
BA_ "SigType" SG_ 2566822654 EngTurbo1CompressorIntakeTemp 1;
BA_ "SPN" SG_ 2566822654 EngTurbo1CompressorIntakeTemp 1172;
BA_ "SigType" SG_ 2633931774 EngTurbo4Speed 1;
BA_ "SPN" SG_ 2633931774 EngTurbo4Speed 1171;
BA_ "SigType" SG_ 2633931774 EngTurbo3Speed 1;
BA_ "SPN" SG_ 2633931774 EngTurbo3Speed 1170;
BA_ "SigType" SG_ 2633931774 EngTurbo2Speed 1;
BA_ "SPN" SG_ 2633931774 EngTurbo2Speed 1169;
BA_ "SigType" SG_ 2633931774 EngTurboLubeOilPress2 1;
BA_ "SPN" SG_ 2633931774 EngTurboLubeOilPress2 1168;
BA_ "SigType" SG_ 2566802430 TransTorqueLimit 1;
BA_ "SPN" SG_ 2566802430 TransTorqueLimit 1845;
BA_ "SigType" SG_ 2566841086 TransGearRatio 1;
BA_ "SPN" SG_ 2566841086 TransGearRatio 581;
BA_ "SigType" SG_ 2566841086 NumberOfForwardGearRatios 1;
BA_ "SPN" SG_ 2566841086 NumberOfForwardGearRatios 957;
BA_ "SigType" SG_ 2566841086 NumberOfReverseGearRatios 1;
BA_ "SPN" SG_ 2566841086 NumberOfReverseGearRatios 958;
BA_ "SigType" SG_ 2348941054 TransMode8 5;
BA_ "SPN" SG_ 2348941054 TransMode8 4249;
BA_ "SigType" SG_ 2348941054 TransMode7 5;
BA_ "SPN" SG_ 2348941054 TransMode7 4248;
BA_ "SigType" SG_ 2348941054 TransMode6 5;
BA_ "SPN" SG_ 2348941054 TransMode6 4247;
BA_ "SigType" SG_ 2348941054 TransMode5 5;
BA_ "SPN" SG_ 2348941054 TransMode5 4246;
BA_ "SigType" SG_ 2348941054 TrnsShftSlectorDisplayModeSwitch 4;
BA_ "SPN" SG_ 2348941054 TrnsShftSlectorDisplayModeSwitch 2985;
BA_ "SPN" SG_ 2348941054 TransRequestedLaunchGear 4255;
BA_ "SigType" SG_ 2348941054 TransMode4 5;
BA_ "SPN" SG_ 2348941054 TransMode4 1855;
BA_ "SigType" SG_ 2348941054 TransMode3 5;
BA_ "SPN" SG_ 2348941054 TransMode3 1854;
BA_ "SigType" SG_ 2348941054 TransMode2 5;
BA_ "SPN" SG_ 2348941054 TransMode2 1853;
BA_ "SigType" SG_ 2348941054 TransMode1 5;
BA_ "SPN" SG_ 2348941054 TransMode1 1852;
BA_ "SigType" SG_ 2348941054 TransLoadReductionInhibitRq 5;
BA_ "SPN" SG_ 2348941054 TransLoadReductionInhibitRq 5762;
BA_ "SigType" SG_ 2348941054 DisengageDiffLockRqCentralRear 5;
BA_ "SPN" SG_ 2348941054 DisengageDiffLockRqCentralRear 691;
BA_ "SigType" SG_ 2348941054 DisengageDiffLockRqCentralFront 5;
BA_ "SPN" SG_ 2348941054 DisengageDiffLockRqCentralFront 690;
BA_ "SigType" SG_ 2348941054 DisengageDiffLockRqCentral 5;
BA_ "SPN" SG_ 2348941054 DisengageDiffLockRqCentral 689;
BA_ "SigType" SG_ 2348941054 DisengageDiffLockRqRearAxle2 5;
BA_ "SPN" SG_ 2348941054 DisengageDiffLockRqRearAxle2 688;
BA_ "SigType" SG_ 2348941054 DisengageDiffLockRqRearAxle1 5;
BA_ "SPN" SG_ 2348941054 DisengageDiffLockRqRearAxle1 687;
BA_ "SigType" SG_ 2348941054 DisengageDiffLockRqFrontAxle2 5;
BA_ "SPN" SG_ 2348941054 DisengageDiffLockRqFrontAxle2 686;
BA_ "SigType" SG_ 2348941054 DisengageDiffLockRqFrontAxle1 5;
BA_ "SPN" SG_ 2348941054 DisengageDiffLockRqFrontAxle1 685;
BA_ "SigType" SG_ 2348941054 TransRequestedGear 1;
BA_ "GenSigStartValue" SG_ 2348941054 TransRequestedGear 61;
BA_ "SPN" SG_ 2348941054 TransRequestedGear 525;
BA_ "SigType" SG_ 2348941054 RequestedPercentClutchSlip 1;
BA_ "SPN" SG_ 2348941054 RequestedPercentClutchSlip 684;
BA_ "SigType" SG_ 2348941054 TransReverseGearShiftInhibitRq 5;
BA_ "SPN" SG_ 2348941054 TransReverseGearShiftInhibitRq 4242;
BA_ "SigType" SG_ 2348941054 DisengageDrivelineRq 5;
BA_ "SPN" SG_ 2348941054 DisengageDrivelineRq 683;
BA_ "SigType" SG_ 2348941054 TrnsTrqeConverterLockupDisableRq 5;
BA_ "SPN" SG_ 2348941054 TrnsTrqeConverterLockupDisableRq 682;
BA_ "SigType" SG_ 2348941054 TransGearShiftInhibitRq 5;
BA_ "SPN" SG_ 2348941054 TransGearShiftInhibitRq 681;
BA_ "SigType" SG_ 2566839806 EngTurboOilLevelSwitch 4;
BA_ "SPN" SG_ 2566839806 EngTurboOilLevelSwitch 1665;
BA_ "SigType" SG_ 2566839806 EngTurbo1Speed 1;
BA_ "SPN" SG_ 2566839806 EngTurbo1Speed 103;
BA_ "SigType" SG_ 2566839806 EngTurboLubeOilPress1 1;
BA_ "SPN" SG_ 2566839806 EngTurboLubeOilPress1 104;
BA_ "SigType" SG_ 2566839806 EngTurboDiffSpeed 1;
BA_ "SPN" SG_ 2566839806 EngTurboDiffSpeed 5980;
BA_ "SigType" SG_ 2633911806 EngTotalAverageFuelEconomy 1;
BA_ "SPN" SG_ 2633911806 EngTotalAverageFuelEconomy 1835;
BA_ "SigType" SG_ 2633911806 EngTotalAverageFuelRate 1;
BA_ "SPN" SG_ 2633911806 EngTotalAverageFuelRate 1834;
BA_ "SigType" SG_ 2566775550 PwertrainCircuitAirSupplyPressRq 1;
BA_ "SPN" SG_ 2566775550 PwertrainCircuitAirSupplyPressRq 6306;
BA_ "SigType" SG_ 2566775550 AirSuspensionSupplyPressRq 1;
BA_ "SPN" SG_ 2566775550 AirSuspensionSupplyPressRq 2608;
BA_ "SigType" SG_ 2566775550 AuxEquipmentSupplyPressRq 1;
BA_ "SPN" SG_ 2566775550 AuxEquipmentSupplyPressRq 2607;
BA_ "SigType" SG_ 2566775550 ServiceBrakeAirPressRqCircuit2 1;
BA_ "SPN" SG_ 2566775550 ServiceBrakeAirPressRqCircuit2 2606;
BA_ "SigType" SG_ 2566775550 ServiceBrakeAirPressRqCircuit1 1;
BA_ "SPN" SG_ 2566775550 ServiceBrakeAirPressRqCircuit1 2605;
BA_ "SigType" SG_ 2566775550 ParkingAnd_orTrailerAirPressRq 1;
BA_ "SPN" SG_ 2566775550 ParkingAnd_orTrailerAirPressRq 2604;
BA_ "SigType" SG_ 2566775550 PneumaticSupplyPressRq 1;
BA_ "SPN" SG_ 2566775550 PneumaticSupplyPressRq 2603;
BA_ "SigType" SG_ 2566819838 EngExtlShutdownAirSupplyPress 1;
BA_ "SPN" SG_ 2566819838 EngExtlShutdownAirSupplyPress 1320;
BA_ "SigType" SG_ 2566838785 NmbrOfSftwreIdentificationFields 1;
BA_ "SPN" SG_ 2566838785 NmbrOfSftwreIdentificationFields 965;
BA_ "SigType" SG_ 2566838785 SoftwareIdentification 8;
BA_ "SPN" SG_ 2566838785 SoftwareIdentification 234;
BA_ "SigType" SG_ 2566841598 ClntLvlEngPrtctionShutdownStatus 5;
BA_ "SPN" SG_ 2566841598 ClntLvlEngPrtctionShutdownStatus 5566;
BA_ "SigType" SG_ 2566841598 PTOShutdownHasShutdownEng 5;
BA_ "SPN" SG_ 2566841598 PTOShutdownHasShutdownEng 5404;
BA_ "SigType" SG_ 2566841598 EngAirShutoffStatus 5;
BA_ "SPN" SG_ 2566841598 EngAirShutoffStatus 3667;
BA_ "SigType" SG_ 2566841598 EngOverspeedTest 4;
BA_ "SPN" SG_ 2566841598 EngOverspeedTest 2812;
BA_ "SigType" SG_ 2566841598 EngAirShutoffCmdStatus 5;
BA_ "SPN" SG_ 2566841598 EngAirShutoffCmdStatus 2813;
BA_ "SigType" SG_ 2566841598 EngAlarmOutputCmdStatus 5;
BA_ "SPN" SG_ 2566841598 EngAlarmOutputCmdStatus 2814;
BA_ "SigType" SG_ 2566841598 EngAlarmAcknowledge 4;
BA_ "SPN" SG_ 2566841598 EngAlarmAcknowledge 2815;
BA_ "SigType" SG_ 2566841598 EngProtectionSystemConfig 5;
BA_ "SPN" SG_ 2566841598 EngProtectionSystemConfig 1111;
BA_ "SigType" SG_ 2566841598 EngProtectionSystemTimerState 5;
BA_ "SPN" SG_ 2566841598 EngProtectionSystemTimerState 1107;
BA_ "SigType" SG_ 2566841598 EngProtectionSystemTimerOverride 5;
BA_ "SPN" SG_ 2566841598 EngProtectionSystemTimerOverride 1108;
BA_ "SigType" SG_ 2566841598 EngPrtctnSystmApprachingShutdown 5;
BA_ "SPN" SG_ 2566841598 EngPrtctnSystmApprachingShutdown 1109;
BA_ "SigType" SG_ 2566841598 EngPrtectionSystemHasShutdownEng 5;
BA_ "SPN" SG_ 2566841598 EngPrtectionSystemHasShutdownEng 1110;
BA_ "SigType" SG_ 2566841598 EngWaitToStartLamp 5;
BA_ "SPN" SG_ 2566841598 EngWaitToStartLamp 1081;
BA_ "SigType" SG_ 2566841598 RefrigerantHighPressSwitch 4;
BA_ "SPN" SG_ 2566841598 RefrigerantHighPressSwitch 605;
BA_ "SigType" SG_ 2566841598 RefrigerantLowPressSwitch 4;
BA_ "SPN" SG_ 2566841598 RefrigerantLowPressSwitch 875;
BA_ "SigType" SG_ 2566841598 A_CHighPressFanSwitch 4;
BA_ "SPN" SG_ 2566841598 A_CHighPressFanSwitch 985;
BA_ "SigType" SG_ 2566841598 EngIdleShutdownTimerFunction 4;
BA_ "SPN" SG_ 2566841598 EngIdleShutdownTimerFunction 591;
BA_ "SigType" SG_ 2566841598 EngIdleShutdownTimerState 5;
BA_ "SPN" SG_ 2566841598 EngIdleShutdownTimerState 590;
BA_ "SigType" SG_ 2566841598 EngIdleShutdownTimerOverride 5;
BA_ "SPN" SG_ 2566841598 EngIdleShutdownTimerOverride 592;
BA_ "SigType" SG_ 2566841598 EngIdleShutdownDriverAlertMode 5;
BA_ "SPN" SG_ 2566841598 EngIdleShutdownDriverAlertMode 594;
BA_ "SigType" SG_ 2566841598 EngIdleShutdownHasShutdownEng 5;
BA_ "SPN" SG_ 2566841598 EngIdleShutdownHasShutdownEng 593;
BA_ "SPN" SG_ 2365459710 ArbitraryAddressCapable 2844;
BA_ "SPN" SG_ 2365459710 IndustryGroup 2846;
BA_ "SPN" SG_ 2365459710 VehicleSystemInstance 2843;
BA_ "SPN" SG_ 2365459710 ECUInstance 2840;
BA_ "SPN" SG_ 2365459710 FunctionInstance 2839;
BA_ "SPN" SG_ 2365459710 Function 2841;
BA_ "SigType" SG_ 2365459710 ManufacturerCode 1;
BA_ "SPN" SG_ 2365459710 ManufacturerCode 2838;
BA_ "SPN" SG_ 2365459710 IdentityNumber 2837;
BA_ "SigType" SG_ 2566832382 SrviceDelay_OperationalTimeBased 1;
BA_ "SPN" SG_ 2566832382 SrviceDelay_OperationalTimeBased 916;
BA_ "SigType" SG_ 2566832382 ServiceComponentIdentificatio913 1;
BA_ "SPN" SG_ 2566832382 ServiceComponentIdentificatio913 913;
BA_ "SigType" SG_ 2566832382 ServiceDelay_CalendarTimeBased 1;
BA_ "SPN" SG_ 2566832382 ServiceDelay_CalendarTimeBased 915;
BA_ "SigType" SG_ 2566832382 ServiceComponentIdentificatio912 1;
BA_ "SPN" SG_ 2566832382 ServiceComponentIdentificatio912 912;
BA_ "SigType" SG_ 2566832382 ServiceDistance 1;
BA_ "SPN" SG_ 2566832382 ServiceDistance 914;
BA_ "SigType" SG_ 2566832382 ServiceComponentIdentification 1;
BA_ "SPN" SG_ 2566832382 ServiceComponentIdentification 911;
BA_ "SigType" SG_ 2633928446 TimeSinceLastService 1;
BA_ "SPN" SG_ 2633928446 TimeSinceLastService 1350;
BA_ "SigType" SG_ 2633928446 ServiceComponentIdentification 1;
BA_ "SPN" SG_ 2633928446 ServiceComponentIdentification 1379;
BA_ "SigType" SG_ 2566804478 MinContinuousRetarderTorque 1;
BA_ "SPN" SG_ 2566804478 MinContinuousRetarderTorque 1783;
BA_ "SigType" SG_ 2566804478 MaxContinuousRetarderTorque 1;
BA_ "SPN" SG_ 2566804478 MaxContinuousRetarderTorque 1782;
BA_ "SigType" SG_ 2566804478 MinContinuousRetarderSpeed 1;
BA_ "SPN" SG_ 2566804478 MinContinuousRetarderSpeed 1781;
BA_ "SigType" SG_ 2566804478 MaxContinuousRetarderSpeed 1;
BA_ "SPN" SG_ 2566804478 MaxContinuousRetarderSpeed 1780;
BA_ "SigType" SG_ 2566804478 HghLmtThrshldFrMnCntnsTrqFrmRtrd 1;
BA_ "SPN" SG_ 2566804478 HghLmtThrshldFrMnCntnsTrqFrmRtrd 1779;
BA_ "SigType" SG_ 2566804478 LwLmtThrshldFrMxTrqeFromRetarder 1;
BA_ "SPN" SG_ 2566804478 LwLmtThrshldFrMxTrqeFromRetarder 1778;
BA_ "SigType" SG_ 2566804478 HghLmtThrshldFrMnCntnsRPMFrmRtrd 1;
BA_ "SPN" SG_ 2566804478 HghLmtThrshldFrMnCntnsRPMFrmRtrd 1777;
BA_ "SigType" SG_ 2566804478 LwLmtThrshldFrMaxRPMFromRetarder 1;
BA_ "SPN" SG_ 2566804478 LwLmtThrshldFrMaxRPMFromRetarder 1776;
BA_ "SigType" SG_ 2566847486 DrvlineRetarderOverheatIndicator 5;
BA_ "SPN" SG_ 2566847486 DrvlineRetarderOverheatIndicator 5346;
BA_ "SigType" SG_ 2566847486 RetarderCoolantOutletTemp 1;
BA_ "SPN" SG_ 2566847486 RetarderCoolantOutletTemp 5656;
BA_ "SigType" SG_ 2566847486 HydRetarderOilTemp 1;
BA_ "SPN" SG_ 2566847486 HydRetarderOilTemp 120;
BA_ "SigType" SG_ 2566847486 HydRetarderPress 1;
BA_ "SPN" SG_ 2566847486 HydRetarderPress 119;
BA_ "SigType" SG_ 2631859966 SteerStraightAheadPosReset 5;
BA_ "SPN" SG_ 2631859966 SteerStraightAheadPosReset 3600;
BA_ "SigType" SG_ 2631859966 EngBuildHoursReset 5;
BA_ "SPN" SG_ 2631859966 EngBuildHoursReset 1211;
BA_ "SigType" SG_ 2631859966 EngIgntCtrlMaintenanceHoursReset 4;
BA_ "SPN" SG_ 2631859966 EngIgntCtrlMaintenanceHoursReset 6219;
BA_ "SigType" SG_ 2631859966 EngSprkPlgScndVltgeTrackingReset 5;
BA_ "SPN" SG_ 2631859966 EngSprkPlgScndVltgeTrackingReset 6218;
BA_ "SigType" SG_ 2631859966 ServiceComponentIdentification 1;
BA_ "SPN" SG_ 2631859966 ServiceComponentIdentification 1584;
BA_ "SigType" SG_ 2631859966 TripGroup2Proprietary 5;
BA_ "SPN" SG_ 2631859966 TripGroup2Proprietary 989;
BA_ "SigType" SG_ 2631859966 TripGroup1 5;
BA_ "SPN" SG_ 2631859966 TripGroup1 988;
BA_ "SigType" SG_ 2566840830 PercentTorqueAtPeakTorquePoint5 1;
BA_ "SPN" SG_ 2566840830 PercentTorqueAtPeakTorquePoint5 555;
BA_ "SigType" SG_ 2566840830 ReferenceRetarderTorque 1;
BA_ "SPN" SG_ 2566840830 ReferenceRetarderTorque 556;
BA_ "SigType" SG_ 2566840830 RetarderSpeedAtPeakTorquePoint5 1;
BA_ "SPN" SG_ 2566840830 RetarderSpeedAtPeakTorquePoint5 547;
BA_ "SigType" SG_ 2566840830 PercentTorqueAtPoint4 1;
BA_ "SPN" SG_ 2566840830 PercentTorqueAtPoint4 554;
BA_ "SigType" SG_ 2566840830 RetarderSpeedAtPoint4 1;
BA_ "SPN" SG_ 2566840830 RetarderSpeedAtPoint4 550;
BA_ "SigType" SG_ 2566840830 PercentTorqueAtPoint3 1;
BA_ "SPN" SG_ 2566840830 PercentTorqueAtPoint3 553;
BA_ "SigType" SG_ 2566840830 RetarderSpeedAtPoint3 1;
BA_ "SPN" SG_ 2566840830 RetarderSpeedAtPoint3 549;
BA_ "SigType" SG_ 2566840830 PercentTorqueAtMaxSpeedPoint2 1;
BA_ "SPN" SG_ 2566840830 PercentTorqueAtMaxSpeedPoint2 552;
BA_ "SigType" SG_ 2566840830 MaxRetarderSpeedPoint2 1;
BA_ "SPN" SG_ 2566840830 MaxRetarderSpeedPoint2 548;
BA_ "SigType" SG_ 2566840830 PercentTorqueAtIdlePoint1 1;
BA_ "SPN" SG_ 2566840830 PercentTorqueAtIdlePoint1 551;
BA_ "SigType" SG_ 2566840830 RetarderSpeedAtIdlePoint1 1;
BA_ "SPN" SG_ 2566840830 RetarderSpeedAtIdlePoint1 546;
BA_ "SigType" SG_ 2566840830 RetarderCtrlMethod 1;
BA_ "SPN" SG_ 2566840830 RetarderCtrlMethod 557;
BA_ "SPN" SG_ 2566840830 RetarderLocation 902;
BA_ "SPN" SG_ 2566840830 RetarderType 901;
BA_ "SigType" SG_ 2633930238 EngOperationTimeSinceRebuild 1;
BA_ "SPN" SG_ 2633930238 EngOperationTimeSinceRebuild 1193;
BA_ "SigType" SG_ 2566844670 PowerTakeoffSetSpeed 1;
BA_ "SPN" SG_ 2566844670 PowerTakeoffSetSpeed 187;
BA_ "SigType" SG_ 2566844670 PowerTakeoffSpeed 1;
BA_ "SPN" SG_ 2566844670 PowerTakeoffSpeed 186;
BA_ "SigType" SG_ 2566844670 PowerTakeoffOilTemp 1;
BA_ "SPN" SG_ 2566844670 PowerTakeoffOilTemp 90;
BA_ "SigType" SG_ 2566844670 OprtrEngPTOGvrnrMmrySelectSwitch 4;
BA_ "SPN" SG_ 2566844670 OprtrEngPTOGvrnrMmrySelectSwitch 2897;
BA_ "SigType" SG_ 2566844670 EngRmtPTOGvrnrVrblSpedCtrlSwitch 4;
BA_ "SPN" SG_ 2566844670 EngRmtPTOGvrnrVrblSpedCtrlSwitch 978;
BA_ "SigType" SG_ 2566844670 EngRmtPTOGvrnrPrprgrmmdSpdCtrlSw 4;
BA_ "SPN" SG_ 2566844670 EngRmtPTOGvrnrPrprgrmmdSpdCtrlSw 979;
BA_ "SigType" SG_ 2566844670 EngPTOGvrnrCast_DecelerateSwitch 4;
BA_ "SPN" SG_ 2566844670 EngPTOGvrnrCast_DecelerateSwitch 983;
BA_ "SigType" SG_ 2566844670 EngPTOGovernorSetSwitch 4;
BA_ "SPN" SG_ 2566844670 EngPTOGovernorSetSwitch 984;
BA_ "SigType" SG_ 2566844670 EngPTOGovernorResumeSwitch 4;
BA_ "SPN" SG_ 2566844670 EngPTOGovernorResumeSwitch 982;
BA_ "SigType" SG_ 2566844670 EngPTOGovernorEnableSwitch 4;
BA_ "SPN" SG_ 2566844670 EngPTOGovernorEnableSwitch 980;
BA_ "SigType" SG_ 2566844670 EngPTOGovernorAccelerateSwitch 4;
BA_ "SPN" SG_ 2566844670 EngPTOGovernorAccelerateSwitch 981;
BA_ "SigType" SG_ 2566844670 RmtPTOGvrnrPrprgrmmdSpdCtrlSwtch 4;
BA_ "SPN" SG_ 2566844670 RmtPTOGvrnrPrprgrmmdSpdCtrlSwtch 3447;
BA_ "SigType" SG_ 2566844670 AuxInputIgnoreSwitch 4;
BA_ "SPN" SG_ 2566844670 AuxInputIgnoreSwitch 3448;
BA_ "SPN" SG_ 2566770174 RearWasherFunction 2868;
BA_ "SPN" SG_ 2566770174 FrontOperatorWasherSwitch 2866;
BA_ "SPN" SG_ 2566770174 FrontNonoperatorWasherSwitch 2867;
BA_ "SigType" SG_ 2566770174 RearWiperDelayCtrl 1;
BA_ "SPN" SG_ 2566770174 RearWiperDelayCtrl 2871;
BA_ "SigType" SG_ 2566770174 FrontNonoperatorWiperDelayCtrl 1;
BA_ "SPN" SG_ 2566770174 FrontNonoperatorWiperDelayCtrl 2870;
BA_ "SigType" SG_ 2566770174 FrontOperatorWiperDelayCtrl 1;
BA_ "SPN" SG_ 2566770174 FrontOperatorWiperDelayCtrl 2869;
BA_ "SPN" SG_ 2566770174 RearWiperSwitch 2865;
BA_ "SPN" SG_ 2566770174 FrontOperatorWiperSwitch 2863;
BA_ "SPN" SG_ 2566770174 FrontNonoperatorWiperSwitch 2864;
BA_ "SPN" SG_ 2566769662 EngAltDroopAuxInputSelect 2885;
BA_ "SPN" SG_ 2566769662 EngAltDroopRemoteAccelSelect 2886;
BA_ "SPN" SG_ 2566769662 EngAltDroopAccel2Select 2879;
BA_ "SPN" SG_ 2566769662 EngAltDroopAccel1Select 2881;
BA_ "SigType" SG_ 2566769662 EngAltRatingSelect 1;
BA_ "SPN" SG_ 2566769662 EngAltRatingSelect 2882;
BA_ "SigType" SG_ 2566769662 EngAltLowIdleSwitch 4;
BA_ "SPN" SG_ 2566769662 EngAltLowIdleSwitch 2883;
BA_ "SigType" SG_ 2566769662 EngSynchronizationSwitch 4;
BA_ "SPN" SG_ 2566769662 EngSynchronizationSwitch 1377;
BA_ "SigType" SG_ 2566769662 EngAuxGovernorSwitch 4;
BA_ "SPN" SG_ 2566769662 EngAuxGovernorSwitch 2884;
BA_ "SPN" SG_ 2566768638 EngAltDroopAuxInputSelectState 2895;
BA_ "SPN" SG_ 2566768638 EngAltDropRemoteAccelSelectState 2894;
BA_ "SPN" SG_ 2566768638 EngAltDroopAccel2SelectState 2893;
BA_ "SPN" SG_ 2566768638 EngAltDroopAccel1SelectState 2889;
BA_ "SPN" SG_ 2566768638 EngAltRatingSelectState 2888;
BA_ "SigType" SG_ 2566768638 EngAltLowIdleSelectState 5;
BA_ "SPN" SG_ 2566768638 EngAltLowIdleSelectState 2891;
BA_ "SigType" SG_ 2566768638 EngMultiUnitSyncState 5;
BA_ "SPN" SG_ 2566768638 EngMultiUnitSyncState 2890;
BA_ "SigType" SG_ 2566768638 EngAuxGovernorState 5;
BA_ "SPN" SG_ 2566768638 EngAuxGovernorState 2896;
BA_ "SigType" SG_ 2365443326 OprtorsDesiredDelayedLampOffTime 1;
BA_ "SPN" SG_ 2365443326 OprtorsDesiredDelayedLampOffTime 2877;
BA_ "SigType" SG_ 2365443326 OperatorsDesiredBacklight 1;
BA_ "SPN" SG_ 2365443326 OperatorsDesiredBacklight 2878;
BA_ "SigType" SG_ 2365443326 HighLowBeamSwitch 4;
BA_ "SPN" SG_ 2365443326 HighLowBeamSwitch 2874;
BA_ "SigType" SG_ 2365443326 HazardLightSwitch 4;
BA_ "SPN" SG_ 2365443326 HazardLightSwitch 2875;
BA_ "SPN" SG_ 2365443326 TurnSignalSwitch 2876;
BA_ "SPN" SG_ 2365443326 MainLightSwitch 2872;
BA_ "SPN" SG_ 2365443326 WorkLightSwitch 2873;
BA_ "SigType" SG_ 2566776318 AppliedVehicleSpeedLimit 1;
BA_ "SPN" SG_ 2566776318 AppliedVehicleSpeedLimit 2595;
BA_ "SigType" SG_ 2566776318 MaxVehicleSpeedLimit7 1;
BA_ "SPN" SG_ 2566776318 MaxVehicleSpeedLimit7 2594;
BA_ "SigType" SG_ 2566776318 MaxVehicleSpeedLimit6 1;
BA_ "SPN" SG_ 2566776318 MaxVehicleSpeedLimit6 2593;
BA_ "SigType" SG_ 2566776318 MaxVehicleSpeedLimit5 1;
BA_ "SPN" SG_ 2566776318 MaxVehicleSpeedLimit5 2592;
BA_ "SigType" SG_ 2566776318 MaxVehicleSpeedLimit4 1;
BA_ "SPN" SG_ 2566776318 MaxVehicleSpeedLimit4 2591;
BA_ "SigType" SG_ 2566776318 MaxVehicleSpeedLimit3 1;
BA_ "SPN" SG_ 2566776318 MaxVehicleSpeedLimit3 2590;
BA_ "SigType" SG_ 2566776318 MaxVehicleSpeedLimit2 1;
BA_ "SPN" SG_ 2566776318 MaxVehicleSpeedLimit2 2589;
BA_ "SigType" SG_ 2566776318 MaxVehicleSpeedLimit1 1;
BA_ "SPN" SG_ 2566776318 MaxVehicleSpeedLimit1 2588;
BA_ "SigType" SG_ 2566802686 OprtrsBlackOutIntensitySelection 1;
BA_ "SPN" SG_ 2566802686 OprtrsBlackOutIntensitySelection 1844;
BA_ "SigType" SG_ 2566802686 BlackOutWorkLampSelect 5;
BA_ "SPN" SG_ 2566802686 BlackOutWorkLampSelect 1842;
BA_ "SigType" SG_ 2566802686 NightVisionIlluminatorSelect 5;
BA_ "SPN" SG_ 2566802686 NightVisionIlluminatorSelect 1843;
BA_ "SigType" SG_ 2566802686 BlackOutBrake_StopLampSelect 5;
BA_ "SPN" SG_ 2566802686 BlackOutBrake_StopLampSelect 1841;
BA_ "SigType" SG_ 2566802686 ConvoyDrivingLampSelect 5;
BA_ "SPN" SG_ 2566802686 ConvoyDrivingLampSelect 1837;
BA_ "SigType" SG_ 2566802686 ConvoyLampSelect 5;
BA_ "SPN" SG_ 2566802686 ConvoyLampSelect 1838;
BA_ "SigType" SG_ 2566802686 FrontBlackOutMarkerLampSelect 5;
BA_ "SPN" SG_ 2566802686 FrontBlackOutMarkerLampSelect 1839;
BA_ "SigType" SG_ 2566802686 RearBlackOutMarkerSelect 5;
BA_ "SPN" SG_ 2566802686 RearBlackOutMarkerSelect 1840;
BA_ "SigType" SG_ 2566774014 SlowVesselModeStatus 5;
BA_ "SPN" SG_ 2566774014 SlowVesselModeStatus 2617;
BA_ "SigType" SG_ 2566774014 TrollingModeStatus 5;
BA_ "SPN" SG_ 2566774014 TrollingModeStatus 2616;
BA_ "SPN" SG_ 2566774014 EngThrttlSynchrnzationModeStatus 2615;
BA_ "SigType" SG_ 2566823166 EngMainBearing11Temp 1;
BA_ "SPN" SG_ 2566823166 EngMainBearing11Temp 1167;
BA_ "SigType" SG_ 2566823166 EngMainBearing10Temp 1;
BA_ "SPN" SG_ 2566823166 EngMainBearing10Temp 1166;
BA_ "SigType" SG_ 2566823166 EngMainBearing9Temp 1;
BA_ "SPN" SG_ 2566823166 EngMainBearing9Temp 1165;
BA_ "SigType" SG_ 2566823422 EngMainBearing8Temp 1;
BA_ "SPN" SG_ 2566823422 EngMainBearing8Temp 1164;
BA_ "SigType" SG_ 2566823422 EngMainBearing7Temp 1;
BA_ "SPN" SG_ 2566823422 EngMainBearing7Temp 1163;
BA_ "SigType" SG_ 2566823422 EngMainBearing6Temp 1;
BA_ "SPN" SG_ 2566823422 EngMainBearing6Temp 1162;
BA_ "SigType" SG_ 2566823422 EngMainBearing5Temp 1;
BA_ "SPN" SG_ 2566823422 EngMainBearing5Temp 1161;
BA_ "SigType" SG_ 2566823678 EngMainBearing4Temp 1;
BA_ "SPN" SG_ 2566823678 EngMainBearing4Temp 1160;
BA_ "SigType" SG_ 2566823678 EngMainBearing3Temp 1;
BA_ "SPN" SG_ 2566823678 EngMainBearing3Temp 1159;
BA_ "SigType" SG_ 2566823678 EngMainBearing2Temp 1;
BA_ "SPN" SG_ 2566823678 EngMainBearing2Temp 1158;
BA_ "SigType" SG_ 2566823678 EngMainBearing1Temp 1;
BA_ "SPN" SG_ 2566823678 EngMainBearing1Temp 1157;
BA_ "SPN" SG_ 2432595710 DisplayDeadbands 2577;
BA_ "SPN" SG_ 2432595710 LEDPatternCtrl 2578;
BA_ "SPN" SG_ 2432595710 LEDDisplayDeadbandCtrl 1806;
BA_ "SPN" SG_ 2432595710 LEDDisplayModeCtrl 1805;
BA_ "SPN" SG_ 2432595710 LEDDisplayData1 1573;
BA_ "SigType" SG_ 2365486590 AbsLaserStrikePos 1;
BA_ "SPN" SG_ 2365486590 AbsLaserStrikePos 2794;
BA_ "SigType" SG_ 2365486590 LaserStrikeDataLatency 1;
BA_ "SPN" SG_ 2365486590 LaserStrikeDataLatency 2793;
BA_ "SigType" SG_ 2365486590 LaserReceiverType 1;
BA_ "SPN" SG_ 2365486590 LaserReceiverType 2576;
BA_ "SigType" SG_ 2365486590 LaserStrikeVerticalDeviation 1;
BA_ "SPN" SG_ 2365486590 LaserStrikeVerticalDeviation 1574;
BA_ "SPN" SG_ 2365485566 LaserTracerInformation 1583;
BA_ "SPN" SG_ 2365485566 LEDDisplayData2 1582;
BA_ "SigType" SG_ 2365485566 LaserTracerHorizontalDeviation 1;
BA_ "SPN" SG_ 2365485566 LaserTracerHorizontalDeviation 1581;
BA_ "SigType" SG_ 2365485566 LaserTracerVerticalDistance 1;
BA_ "SPN" SG_ 2365485566 LaserTracerVerticalDistance 1580;
BA_ "SigType" SG_ 2365485566 LaserTracerTargetDeviation 1;
BA_ "SPN" SG_ 2365485566 LaserTracerTargetDeviation 1579;
BA_ "SigType" SG_ 2633939454 TripDriveFuelEconomy 1;
BA_ "SPN" SG_ 2633939454 TripDriveFuelEconomy 1006;
BA_ "SigType" SG_ 2633939454 TripCruiseFuelUsed 1;
BA_ "SPN" SG_ 2633939454 TripCruiseFuelUsed 1005;
BA_ "SigType" SG_ 2633939454 TripVehicleIdleFuelUsed 1;
BA_ "SPN" SG_ 2633939454 TripVehicleIdleFuelUsed 1004;
BA_ "SigType" SG_ 2633939454 TripPTOGovernorNonmovingFuelUsed 1;
BA_ "SPN" SG_ 2633939454 TripPTOGovernorNonmovingFuelUsed 1003;
BA_ "SigType" SG_ 2633939454 TripPTOGovernorMovingFuelUsed 1;
BA_ "SPN" SG_ 2633939454 TripPTOGovernorMovingFuelUsed 1002;
BA_ "SigType" SG_ 2633939454 TripDriveFuelUsed 1;
BA_ "SPN" SG_ 2633939454 TripDriveFuelUsed 1001;
BA_ "SigType" SG_ 2365486334 BldeHeightSetPointHighResolution 1;
BA_ "SPN" SG_ 2365486334 BldeHeightSetPointHighResolution 1759;
BA_ "SigType" SG_ 2365486334 ModifyLevelingSystemSetPoint 1;
BA_ "SPN" SG_ 2365486334 ModifyLevelingSystemSetPoint 1575;
VAL_ 2566845694 TirePressThresholdDetection_13 7 "NotAvailable" 6 "ErrorIndicator" 5 "NotDefined" 4 "ExtrmUndrPrssTrPrssrIsAtALvlWhr" 3 "UndrPrssTrPrssrIsLwrThnThPrssrD" 2 "NWrnngPrssTrPrssrIsWthnThThrshl" 1 "OvrPrssTrPrssrIsHghrThnThPrssrD" 0 "ExtrmOvrPrssTrPrssrIsAtALvlWhrT" ;
VAL_ 2566845694 TirePressThresholdDetection_12 7 "NotAvailable" 6 "ErrorIndicator" 5 "NotDefined" 4 "ExtrmUndrPrssTrPrssrIsAtALvlWhr" 3 "UndrPrssTrPrssrIsLwrThnThPrssrD" 2 "NWrnngPrssTrPrssrIsWthnThThrshl" 1 "OvrPrssTrPrssrIsHghrThnThPrssrD" 0 "ExtrmOvrPrssTrPrssrIsAtALvlWhrT" ;
VAL_ 2566845694 TirePressThresholdDetection_11 7 "NotAvailable" 6 "ErrorIndicator" 5 "NotDefined" 4 "ExtrmUndrPrssTrPrssrIsAtALvlWhr" 3 "UndrPrssTrPrssrIsLwrThnThPrssrD" 2 "NWrnngPrssTrPrssrIsWthnThThrshl" 1 "OvrPrssTrPrssrIsHghrThnThPrssrD" 0 "ExtrmOvrPrssTrPrssrIsAtALvlWhrT" ;
VAL_ 2566845694 TirePressThresholdDetection_10 7 "NotAvailable" 6 "ErrorIndicator" 5 "NotDefined" 4 "ExtrmUndrPrssTrPrssrIsAtALvlWhr" 3 "UndrPrssTrPrssrIsLwrThnThPrssrD" 2 "NWrnngPrssTrPrssrIsWthnThThrshl" 1 "OvrPrssTrPrssrIsHghrThnThPrssrD" 0 "ExtrmOvrPrssTrPrssrIsAtALvlWhrT" ;
VAL_ 2566845694 TirePressThresholdDetection_01 7 "NotAvailable" 6 "ErrorIndicator" 5 "NotDefined" 4 "ExtrmUndrPrssTrPrssrIsAtALvlWhr" 3 "UndrPrssTrPrssrIsLwrThnThPrssrD" 2 "NWrnngPrssTrPrssrIsWthnThThrshl" 1 "OvrPrssTrPrssrIsHghrThnThPrssrD" 0 "ExtrmOvrPrssTrPrssrIsAtALvlWhrT" ;
VAL_ 2566845694 CTIWheelSensorStatus_33 3 "NotSupported" 2 "NotDefined" 1 "On" 0 "Off_IsolatedFromCTIPressCtrl" ;
VAL_ 2566845694 CTIWheelSensorStatus_32 3 "NotSupported" 2 "NotDefined" 1 "On" 0 "Off_IsolatedFromCTIPressCtrl" ;
VAL_ 2566845694 CTIWheelSensorStatus_31 3 "NotSupported" 2 "NotDefined" 1 "On" 0 "Off_IsolatedFromCTIPressCtrl" ;
VAL_ 2566845694 CTIWheelSensorStatus_30 3 "NotSupported" 2 "NotDefined" 1 "On" 0 "Off_IsolatedFromCTIPressCtrl" ;
VAL_ 2566845694 CTIWheelSensorStatus_23 3 "NotSupported" 2 "NotDefined" 1 "On" 0 "Off_IsolatedFromCTIPressCtrl" ;
VAL_ 2566845694 CTIWheelSensorStatus_22 3 "NotSupported" 2 "NotDefined" 1 "On" 0 "Off_IsolatedFromCTIPressCtrl" ;
VAL_ 2566845694 CTIWheelSensorStatus_21 3 "NotSupported" 2 "NotDefined" 1 "On" 0 "Off_IsolatedFromCTIPressCtrl" ;
VAL_ 2566845694 CTIWheelSensorStatus_20 3 "NotSupported" 2 "NotDefined" 1 "On" 0 "Off_IsolatedFromCTIPressCtrl" ;
VAL_ 2566845694 CTIWheelSensorStatus_13 3 "NotSupported" 2 "NotDefined" 1 "On" 0 "Off_IsolatedFromCTIPressCtrl" ;
VAL_ 2566845694 CTIWheelSensorStatus_12 3 "NotSupported" 2 "NotDefined" 1 "On" 0 "Off_IsolatedFromCTIPressCtrl" ;
VAL_ 2566845694 CTIWheelSensorStatus_11 3 "NotSupported" 2 "NotDefined" 1 "On" 0 "Off_IsolatedFromCTIPressCtrl" ;
VAL_ 2566845694 CTIWheelSensorStatus_10 3 "NotSupported" 2 "NotDefined" 1 "On" 0 "Off_IsolatedFromCTIPressCtrl" ;
VAL_ 2566845694 CTIWheelSensorStatus_01 3 "NotSupported" 2 "NotDefined" 1 "On" 0 "Off_IsolatedFromCTIPressCtrl" ;
VAL_ 2566845694 CTIWheelEndElectricalFault_33 3 "NotSupported" 2 "Error" 1 "NotDefined" 0 "Ok" ;
VAL_ 2566845694 CTIWheelEndElectricalFault_32 3 "NotSupported" 2 "Error" 1 "NotDefined" 0 "Ok" ;
VAL_ 2566845694 CTIWheelEndElectricalFault_31 3 "NotSupported" 2 "Error" 1 "NotDefined" 0 "Ok" ;
VAL_ 2566845694 CTIWheelEndElectricalFault_30 3 "NotSupported" 2 "Error" 1 "NotDefined" 0 "Ok" ;
VAL_ 2566845694 CTIWheelEndElectricalFault_23 3 "NotSupported" 2 "Error" 1 "NotDefined" 0 "Ok" ;
VAL_ 2566845694 CTIWheelEndElectricalFault_22 3 "NotSupported" 2 "Error" 1 "NotDefined" 0 "Ok" ;
VAL_ 2566845694 CTIWheelEndElectricalFault_21 3 "NotSupported" 2 "Error" 1 "NotDefined" 0 "Ok" ;
VAL_ 2566845694 CTIWheelEndElectricalFault_20 3 "NotSupported" 2 "Error" 1 "NotDefined" 0 "Ok" ;
VAL_ 2566845694 CTIWheelEndElectricalFault_13 3 "NotSupported" 2 "Error" 1 "NotDefined" 0 "Ok" ;
VAL_ 2566845694 CTIWheelEndElectricalFault_12 3 "NotSupported" 2 "Error" 1 "NotDefined" 0 "Ok" ;
VAL_ 2566845694 CTIWheelEndElectricalFault_11 3 "NotSupported" 2 "Error" 1 "NotDefined" 0 "Ok" ;
VAL_ 2566845694 CTIWheelEndElectricalFault_10 3 "NotSupported" 2 "Error" 1 "NotDefined" 0 "Ok" ;
VAL_ 2566845694 CTIWheelEndElectricalFault_01 3 "NotSupported" 2 "Error" 1 "NotDefined" 0 "Ok" ;
VAL_ 2566845694 CTITireStatus_33 3 "NotSupported" 2 "Error" 1 "TireLeakDetected" 0 "Ok" ;
VAL_ 2566845694 CTITireStatus_32 3 "NotSupported" 2 "Error" 1 "TireLeakDetected" 0 "Ok" ;
VAL_ 2566845694 CTITireStatus_31 3 "NotSupported" 2 "Error" 1 "TireLeakDetected" 0 "Ok" ;
VAL_ 2566845694 CTITireStatus_30 3 "NotSupported" 2 "Error" 1 "TireLeakDetected" 0 "Ok" ;
VAL_ 2566845694 CTITireStatus_23 3 "NotSupported" 2 "Error" 1 "TireLeakDetected" 0 "Ok" ;
VAL_ 2566845694 CTITireStatus_22 3 "NotSupported" 2 "Error" 1 "TireLeakDetected" 0 "Ok" ;
VAL_ 2566845694 CTITireStatus_21 3 "NotSupported" 2 "Error" 1 "TireLeakDetected" 0 "Ok" ;
VAL_ 2566845694 CTITireStatus_20 3 "NotSupported" 2 "Error" 1 "TireLeakDetected" 0 "Ok" ;
VAL_ 2566845694 CTITireStatus_13 3 "NotSupported" 2 "Error" 1 "TireLeakDetected" 0 "Ok" ;
VAL_ 2566845694 CTITireStatus_12 3 "NotSupported" 2 "Error" 1 "TireLeakDetected" 0 "Ok" ;
VAL_ 2566845694 CTITireStatus_11 3 "NotSupported" 2 "Error" 1 "TireLeakDetected" 0 "Ok" ;
VAL_ 2566845694 CTITireStatus_10 3 "NotSupported" 2 "Error" 1 "TireLeakDetected" 0 "Ok" ;
VAL_ 2566845694 CTITireStatus_01 3 "NotSupported" 2 "Error" 1 "TireLeakDetected" 0 "Ok" ;
VAL_ 2566845694 TirePressThresholdDetection_33 7 "NotAvailable" 6 "ErrorIndicator" 5 "NotDefined" 4 "ExtrmUndrPrssTrPrssrIsAtALvlWhr" 3 "UndrPrssTrPrssrIsLwrThnThPrssrD" 2 "NWrnngPrssTrPrssrIsWthnThThrshl" 1 "OvrPrssTrPrssrIsHghrThnThPrssrD" 0 "ExtrmOvrPrssTrPrssrIsAtALvlWhrT" ;
VAL_ 2566845694 TirePressThresholdDetection_32 7 "NotAvailable" 6 "ErrorIndicator" 5 "NotDefined" 4 "ExtrmUndrPrssTrPrssrIsAtALvlWhr" 3 "UndrPrssTrPrssrIsLwrThnThPrssrD" 2 "NWrnngPrssTrPrssrIsWthnThThrshl" 1 "OvrPrssTrPrssrIsHghrThnThPrssrD" 0 "ExtrmOvrPrssTrPrssrIsAtALvlWhrT" ;
VAL_ 2566845694 TirePressThresholdDetection_31 7 "NotAvailable" 6 "ErrorIndicator" 5 "NotDefined" 4 "ExtrmUndrPrssTrPrssrIsAtALvlWhr" 3 "UndrPrssTrPrssrIsLwrThnThPrssrD" 2 "NWrnngPrssTrPrssrIsWthnThThrshl" 1 "OvrPrssTrPrssrIsHghrThnThPrssrD" 0 "ExtrmOvrPrssTrPrssrIsAtALvlWhrT" ;
VAL_ 2566845694 TirePressThresholdDetection_30 7 "NotAvailable" 6 "ErrorIndicator" 5 "NotDefined" 4 "ExtrmUndrPrssTrPrssrIsAtALvlWhr" 3 "UndrPrssTrPrssrIsLwrThnThPrssrD" 2 "NWrnngPrssTrPrssrIsWthnThThrshl" 1 "OvrPrssTrPrssrIsHghrThnThPrssrD" 0 "ExtrmOvrPrssTrPrssrIsAtALvlWhrT" ;
VAL_ 2566845694 TirePressThresholdDetection_23 7 "NotAvailable" 6 "ErrorIndicator" 5 "NotDefined" 4 "ExtrmUndrPrssTrPrssrIsAtALvlWhr" 3 "UndrPrssTrPrssrIsLwrThnThPrssrD" 2 "NWrnngPrssTrPrssrIsWthnThThrshl" 1 "OvrPrssTrPrssrIsHghrThnThPrssrD" 0 "ExtrmOvrPrssTrPrssrIsAtALvlWhrT" ;
VAL_ 2566845694 TirePressThresholdDetection_22 7 "NotAvailable" 6 "ErrorIndicator" 5 "NotDefined" 4 "ExtrmUndrPrssTrPrssrIsAtALvlWhr" 3 "UndrPrssTrPrssrIsLwrThnThPrssrD" 2 "NWrnngPrssTrPrssrIsWthnThThrshl" 1 "OvrPrssTrPrssrIsHghrThnThPrssrD" 0 "ExtrmOvrPrssTrPrssrIsAtALvlWhrT" ;
VAL_ 2566845694 TirePressThresholdDetection_21 7 "NotAvailable" 6 "ErrorIndicator" 5 "NotDefined" 4 "ExtrmUndrPrssTrPrssrIsAtALvlWhr" 3 "UndrPrssTrPrssrIsLwrThnThPrssrD" 2 "NWrnngPrssTrPrssrIsWthnThThrshl" 1 "OvrPrssTrPrssrIsHghrThnThPrssrD" 0 "ExtrmOvrPrssTrPrssrIsAtALvlWhrT" ;
VAL_ 2566845694 TirePressThresholdDetection_20 7 "NotAvailable" 6 "ErrorIndicator" 5 "NotDefined" 4 "ExtrmUndrPrssTrPrssrIsAtALvlWhr" 3 "UndrPrssTrPrssrIsLwrThnThPrssrD" 2 "NWrnngPrssTrPrssrIsWthnThThrshl" 1 "OvrPrssTrPrssrIsHghrThnThPrssrD" 0 "ExtrmOvrPrssTrPrssrIsAtALvlWhrT" ;
VAL_ 2566845694 TirePressThresholdDetection_00 7 "NotAvailable" 6 "ErrorIndicator" 5 "NotDefined" 4 "ExtrmUndrPrssTrPrssrIsAtALvlWhr" 3 "UndrPrssTrPrssrIsLwrThnThPrssrD" 2 "NWrnngPrssTrPrssrIsWthnThThrshl" 1 "OvrPrssTrPrssrIsHghrThnThPrssrD" 0 "ExtrmOvrPrssTrPrssrIsAtALvlWhrT" ;
VAL_ 2566845694 CTIWheelSensorStatus_00 3 "NotSupported" 2 "NotDefined" 1 "On" 0 "Off_IsolatedFromCTIPressCtrl" ;
VAL_ 2566845694 CTIWheelEndElectricalFault_00 3 "NotSupported" 2 "Error" 1 "NotDefined" 0 "Ok" ;
VAL_ 2566845694 CTITireStatus_00 3 "NotSupported" 2 "Error" 1 "TireLeakDetected" 0 "Ok" ;
VAL_ 2566845694 TireLocation 51 "TirePress_33_MUX_51" 50 "TirePress_32_MUX_50" 49 "TirePress_31_MUX_49" 48 "TirePress_30_MUX_48" 35 "TirePress_23_MUX_35" 34 "TirePress_22_MUX_34" 33 "TirePress_21_MUX_33" 32 "TirePress_20_MUX_32" 19 "TirePress_13_MUX_19" 18 "TirePress_12_MUX_18" 17 "TirePress_11_MUX_17" 16 "TirePress_10_MUX_16" 1 "TirePress_01_MUX_1" 0 "TirePress_00_MUX_0" ;
VAL_ 2566821630 EngTrbWstgateActuator1TempStatus 7 "Not available" 6 "Error" 5 "Not Defined" 4 "Low Most severe" 3 "Low Least severe" 2 "In Range" 1 "High Least severe" 0 "High Most severe" ;
VAL_ 2365484286 DirectionIndicator 3 "Not available" 2 "Error" 1 "Reverse" 0 "Forward" ;
VAL_ 2365484286 TachographPerformance 3 "Not available" 2 "Error" 1 "Performance analysis" 0 "Normal performance" ;
VAL_ 2365484286 HandlingInformation 3 "Not available" 2 "Error" 1 "Handling information" 0 "No handling information" ;
VAL_ 2365484286 SystemEvent 3 "Not available" 2 "Error" 1 "Tachograph event" 0 "No tachograph event" ;
VAL_ 2365484286 DriverCardDriver2 3 "Not available" 2 "Error" 1 "Driver card present" 0 "Driver card not present" ;
VAL_ 2365484286 Driver2TimeRelatedStates 15 "Not available" 14 "Error" 13 "Other" 6 "Limit 6  16 h reached" 5 "Limit 5  15 min before 16 h not having 8h rest during the last 24h" 4 "Limit 4  9 h reached" 3 "Limit 3  15 min before 9 h" 2 "Limit 2  4  h reached" 1 "Limit 1  15 min before 4  h" 0 "Normal/No limits reached" ;
VAL_ 2365484286 VehicleOverspeed 3 "Not available" 2 "Error" 1 "Overspeed" 0 "No overspeed" ;
VAL_ 2365484286 DriverCardDriver1 3 "Not available" 2 "Error" 1 "Driver card present" 0 "Driver card not present" ;
VAL_ 2365484286 Driver1TimeRelatedStates 15 "Not available" 14 "Error" 13 "Other" 6 "Limit 6  16 h reached" 5 "Limit 5  15 min before 16 h not having 8h rest during the last 24h" 4 "Limit 4  9 h reached" 3 "Limit 3  15 min before 9 h" 2 "Limit 2  4  h reached" 1 "Limit 1  15 min before 4  h" 0 "Normal/No limits reached" ;
VAL_ 2365484286 VehicleMotion 3 "Not available" 2 "Error" 1 "Vehicle motion detected" 0 "Vehicle motion not detected" ;
VAL_ 2365484286 Driver2WorkingState 7 "Not available" 6 "Error" 3 "Drive  behind wheel" 2 "Work  loading unloading working in an office" 1 "Driver available  short break" 0 "Rest  sleeping" ;
VAL_ 2365484286 Driver1WorkingState 7 "Not available" 6 "Error" 3 "Drive  behind wheel" 2 "Work  loading unloading working in an office" 1 "Driver available  short break" 0 "Rest  sleeping" ;
VAL_ 2348941054 TransMode8 3 "Take no action" 2 "Reserved" 1 "Enable" 0 "Disable" ;
VAL_ 2348941054 TransMode7 3 "Take no action" 2 "Reserved" 1 "Enable" 0 "Disable" ;
VAL_ 2348941054 TransMode6 3 "Take no action" 2 "Reserved" 1 "Enable" 0 "Disable" ;
VAL_ 2348941054 TransMode5 3 "Take no action" 2 "Reserved" 1 "Enable" 0 "Disable" ;
VAL_ 2348941054 TrnsShftSlectorDisplayModeSwitch 3 "Not available" 2 "Error" 1 "On" 0 "Off" ;
VAL_ 2348941054 TransRequestedLaunchGear 15 "Not Available" 14 "Error" 13 "Reserved" 12 "Launch the vehicle in Reverse 4" 11 "Launch the vehicle in Reverse 3" 10 "Launch the vehicle in Reverse 2" 9 "Launch the vehicle in Reverse 1" 8 "Launch the vehicle in 8th gear" 7 "Launch the vehicle in 7th gear" 6 "Launch the vehicle in 6th gear" 5 "Launch the vehicle in 5th gear" 4 "Launch the vehicle in 4th gear" 3 "Launch the vehicle in 3rd gear" 2 "Launch the vehicle in 2nd gear" 1 "Launch the vehicle in 1st gear" 0 "No specific launch gear requested use default launch gear" ;
VAL_ 2348941054 TransMode4 3 "Take no action" 2 "Reserved" 1 "Enable" 0 "Disable" ;
VAL_ 2348941054 TransMode3 3 "Take no action" 2 "Reserved" 1 "Enable" 0 "Disable" ;
VAL_ 2348941054 TransMode2 3 "Take no action" 2 "Reserved" 1 "Enable" 0 "Disable" ;
VAL_ 2348941054 TransMode1 3 "Take no action" 2 "Reserved" 1 "Enable" 0 "Disable" ;
VAL_ 2348941054 TransLoadReductionInhibitRq 3 "Dont care/take no action" 2 "Reserved" 1 "Inhibit or abort transmission load reduction functions" 0 "Allow or resume transmission load reduction functions" ;
VAL_ 2348941054 DisengageDiffLockRqCentralRear 3 "Take no action" 2 "Reserved" 1 "Disengage differential lock" 0 "Engage differential lock" ;
VAL_ 2348941054 DisengageDiffLockRqCentralFront 3 "Take no action" 2 "Reserved" 1 "Disengage differential lock" 0 "Engage differential lock" ;
VAL_ 2348941054 DisengageDiffLockRqCentral 3 "Take no action" 2 "Reserved" 1 "Disengage differential lock" 0 "Engage differential lock" ;
VAL_ 2348941054 DisengageDiffLockRqRearAxle2 3 "Take no action" 2 "Reserved" 1 "Disengage differential lock" 0 "Engage differential lock" ;
VAL_ 2348941054 DisengageDiffLockRqRearAxle1 3 "Take no action" 2 "Reserved" 1 "Disengage differential lock" 0 "Engage differential lock" ;
VAL_ 2348941054 DisengageDiffLockRqFrontAxle2 3 "Take no action" 2 "Reserved" 1 "Disengage differential lock" 0 "Engage differential lock" ;
VAL_ 2348941054 DisengageDiffLockRqFrontAxle1 3 "Take no action" 2 "Reserved" 1 "Disengage differential lock" 0 "Engage differential lock" ;
VAL_ 2348941054 TransRequestedGear 223 "Reverse Selector Position" 224 "Position unknown and/or no buttons pressed" 225 "Press of momentary button to reselect current position" 226 "Between ‘Reverse’ and ‘Park’ shift selector positions" 227 "Between ‘Neutral’ and ‘Reverse’ shift selector positions" 228 "Between ‘Drive’ and ‘Neutral’ shift selector positions" 229 "Between D-1 and ‘Drive’ shift selector positions" 230 "Between D-2 and D-1 shift selector positions" 231 "Between D-3 and D-2 shift selector positions" 232 "Between D-4 and D-3 shift selector positions" 233 "Between D-5 and D-4 shift selector positions" 234 "Between D-6 and D-5 shift selector positions" 235 "Between D-7 and D-6 shift selector positions" 236 "Between two forward shift selector positions" 237 "Between two reverse shift selector positions" 238 "Between two shift selector positions (if detail is unknown)" 239 "D-7: 7th forward selector position referenced from ‘Drive’" 240 "D-6: 6th forward selector position referenced from ‘Drive’" 241 "D-5: 5th forward selector position referenced from ‘Drive’" 242 "D-4: 4th forward selector position referenced from ‘Drive’" 243 "D-3: 3rd forward selector position referenced from ‘Drive’" 244 "D-2: 2nd forward selector position referenced from ‘Drive’" 245 "D-1: 1st forward selector position referenced from ‘Drive’" 246 "Downshift 2 gears from current position" 247 "Downshift 1 gear from current position" 248 "Upshift 2 gears from current position" 249 "Upshift 1 gear from current position" 250 "Forward ‘Low’ position" 251 "‘Park’ position" 252 "Forward Drive Position" 253 "Hold current gear" ;
VAL_ 2348941054 TransReverseGearShiftInhibitRq 3 "Take no action" 2 "Reserved" 1 "Inhibit shifts into Reverse gear and shift transmission to Neutral if already in Reverse or attempting to shift to" 0 "Allow shifts into Reverse gear" ;
VAL_ 2348941054 DisengageDrivelineRq 2 "Reserved" 3 "Take no action" 1 "Disengage driveline" 0 "Allow driveline engagement" ;
VAL_ 2348941054 TrnsTrqeConverterLockupDisableRq 3 "Take no action" 2 "Reserved" 1 "Disable torque converter lockup" 0 "Allow torque converter lockup" ;
VAL_ 2348941054 TransGearShiftInhibitRq 2 "Reserved" 3 "Take no action  leave function as is" 1 "Gear shifts are inhibited  enable function" 0 "Gear shifts are allowed  disable function" ;
VAL_ 2566839806 EngTurboOilLevelSwitch 3 "Not available" 2 "Error" 1 "Oil present at turbocharger" 0 "No oil present at turbocharger" ;
VAL_ 2566841598 ClntLvlEngPrtctionShutdownStatus 3 "Not Available" 2 "Reserved" 1 "Enabled  calibration allows engine protection due to low coolant level and the override is currently not active" 0 "Disabled  calibration does not allow engine protection due to low coolant level or the override is currently active" ;
VAL_ 2566841598 PTOShutdownHasShutdownEng 3 "Not available" 2 "Error" 1 "Yes" 0 "No" ;
VAL_ 2566841598 EngAirShutoffStatus 3 "Not Available" 2 "Error" 1 "Air flow restricted" 0 "Air flow allowed to engine" ;
VAL_ 2566841598 EngOverspeedTest 3 "Not Available" 2 "Reserved" 1 "Engine Overspeed Test Active" 0 "Engine Overspeed Test Not Active" ;
VAL_ 2566841598 EngAirShutoffCmdStatus 0 "Air Shutoff Disabled not attempting to shutoff engine air supply" 3 "Not Available" 2 "Reserved" 1 "Air Shutoff Enabled attempting to shutoff engine air supply" ;
VAL_ 2566841598 EngAlarmOutputCmdStatus 3 "Not Available" 2 "Reserved" 1 "Engine Alarm Output Command Active" 0 "Engine Alarm Output Command Not Active" ;
VAL_ 2566841598 EngAlarmAcknowledge 3 "Not Available" 2 "Error" 1 "Engine Alarm Acknowledge Active" 0 "Engine Alarm Acknowledge Not Active" ;
VAL_ 2566841598 EngProtectionSystemConfig 3 "Not available" 2 "Error" 1 "Enabled in calibration" 0 "Disabled in calibration" ;
VAL_ 2566841598 EngProtectionSystemTimerState 3 "Not available" 2 "Error" 1 "Active" 0 "Inactive" ;
VAL_ 2566841598 EngProtectionSystemTimerOverride 3 "Not available" 2 "Error" 1 "Active" 0 "Inactive" ;
VAL_ 2566841598 EngPrtctnSystmApprachingShutdown 3 "Not available" 2 "Error" 1 "Approaching" 0 "Not approaching" ;
VAL_ 2566841598 EngPrtectionSystemHasShutdownEng 3 "Not available" 2 "Error" 1 "Yes" 0 "No" ;
VAL_ 2566841598 EngWaitToStartLamp 3 "Not available" 2 "Error" 1 "On" 0 "Off" ;
VAL_ 2566841598 RefrigerantHighPressSwitch 3 "Not available" 2 "Error" 1 "Pressure too high compressor clutch may be disengaged" 0 "Pressure normal" ;
VAL_ 2566841598 RefrigerantLowPressSwitch 3 "Not available" 2 "Error" 1 "Pressure too low compressor clutch may be disengaged" 0 "Pressure normal" ;
VAL_ 2566841598 A_CHighPressFanSwitch 3 "Not available" 2 "Error" 1 "Pressure high fan may be engaged" 0 "Pressure normal" ;
VAL_ 2566841598 EngIdleShutdownTimerFunction 3 "Not available" 2 "Error" 1 "Enabled in calibration" 0 "Disabled in calibration" ;
VAL_ 2566841598 EngIdleShutdownTimerState 3 "Not available" 2 "Error" 1 "Active" 0 "Inactive" ;
VAL_ 2566841598 EngIdleShutdownTimerOverride 3 "Not available" 2 "Error" 1 "Active" 0 "Inactive" ;
VAL_ 2566841598 EngIdleShutdownDriverAlertMode 3 "Not available" 2 "Error" 1 "Active" 0 "Inactive" ;
VAL_ 2566841598 EngIdleShutdownHasShutdownEng 3 "Not available" 2 "Error" 1 "Yes" 0 "No" ;
VAL_ 2365459710 VehicleSystem5 127 "Not Available" 0 "Ind. Process Control Stationary" ;
VAL_ 2365459710 VehicleSystem4 125 "Entertainment" 120 "Display" 85 "External Environment" 75 "Sensor Communication Interface" 35 "Electrical Generation" 100 "Deck, Cargo and Fishing Equipment" 90 "Internal Environment" 80 "Instrumentation/General Systems (deprecate)" 70 "Communications" 60 "Navigation" 50 "Propulsion" 40 "Steering and Control Surfaces" 30 "Electrical Distribution" 25 "Inter/Intranetwork Device" 20 "Safety Systems" 10 "System Tools" 127 "Not Available" 0 "Non-specific System" ;
VAL_ 2365459710 VehicleSystem3 8 "Grader" 7 "Four Wheel Drive Loader" 6 "Forklift" 5 "Excavator" 4 "Crawler" 3 "Backhoe" 2 "Articulated Dump Truck" 1 "Skid Steer Loader" 127 "Not Available" 0 "Non-specific System" ;
VAL_ 2365459710 VehicleSystem2 25 "Slurry Applicators" 24 "Utility Vehicles" 23 "Mulchers" 22 "Timber Processing Machines" 21 "Timber loaders" 20 "Forwarders" 19 "Timber Harvesters" 17 "Sensor Systems" 16 "Skidder" 15 "Earth Work" 14 "Special Crops" 13 "Powered Auxiliary Device" 12 "Farm Yard Operations" 11 "Transport/Trailer" 10 "Irrigation" 9 "Forage" 8 "Root Harvesters" 7 "Harvesters" 6 "Sprayers" 5 "Fertilizers" 4 "Planters/Seeders" 3 "Secondary Tillage" 2 "Tillage" 1 "Tractor" 127 "Not Available" 0 "Non-specific System" ;
VAL_ 2365459710 VehicleSystem1 2 "Trailer" 1 "Tractor" 127 "Not Available" 0 "Non-specific System" ;
VAL_ 2365459710 IndustryGroup 6 "Reserved for SAE" 7 "Reserved for SAE" 5 "IndustrialProcessCtrlStationary" 4 "Marine" 3 "Construction" 2 "Agricultural and Forestry" 1 "On-Highway" 0 "Global" ;
VAL_ 2365459710 VehicleSystem 0 "Non-specific System" 127 "Not Available" ;
VAL_ 2365459710 Function 127 "Reserved" 126 "Reserved" 125 "Reserved" 124 "Reserved" 123 "Reserved" 122 "Reserved" 121 "Reserved" 120 "Reserved" 119 "Reserved" 118 "Reserved" 117 "Reserved" 116 "Reserved" 115 "Reserved" 114 "Reserved" 113 "Reserved" 112 "Reserved" 111 "Reserved" 110 "Reserved" 109 "Reserved" 108 "Reserved" 107 "Reserved" 106 "Reserved" 105 "Reserved" 104 "Reserved" 103 "Reserved" 102 "Reserved" 101 "Reserved" 42 "Water Pump Control" 41 "Lighting - Operator Controls" 40 "Seat Control" 39 "Ignition Control Module" 38 "Tire Pressure Control" 37 "Cab Controller" 36 "Pneumatic - System Controller" 35 "Suspension - System Controller" 34 "Hydraulic Pump Controller" 33 "System Monitor" 32 "Headway Controller" 31 "Propulsion Battery Charger" 30 "Management Computer" 29 "Virtual Terminal (in cab)" 28 "Off Vehicle Gateway" 27 "Power TakeOff (Secondary or Front)" 26 "Body Controller" 25 "Network Interconnect ECU" 24 "Vehicle Security" 23 "Vehicle Navigation" 22 "Aerodynamic Control" 21 "Cab Climate Control" 20 "Trip Recorder" 19 "Instrument Cluster" 18 "Suspension - Drive Axle" 17 "Suspension - Steer Axle" 16 "Steering Controller" 15 "Fuel System" 14 "Cruise Control" 13 "Retarder - Driveline" 12 "Retarder - Engine" 11 "Brakes - Drive Axle" 10 "Brakes - Steer Axle" 9 "Brakes - System Controller" 8 "Axle - Drive" 7 "Axle - Steering" 6 "Power TakeOff - (Main or Rear)" 5 "Shift Control/Console" 4 "Battery Pack Monitor" 3 "Transmission" 2 "Electric Propulsion Control" 1 "Auxiliary Power Unit (APU)" 0 "Engine" 100 "Reserved" 99 "Reserved" 98 "Reserved" 97 "Reserved" 96 "Reserved" 95 "Reserved" 94 "Reserved" 93 "Reserved" 92 "Reserved" 91 "Reserved" 90 "Reserved" 89 "Reserved" 88 "Reserved" 87 "Reserved" 86 "Reserved" 85 "Reserved" 84 "Reserved" 83 "Reserved" 82 "Reserved" 81 "Reserved" 80 "Reserved" 79 "Reserved" 78 "Fire Suppression System" 77 "Fuel Properties Sensor" 76 "Temperature Sensor" 75 "Supplemental Fan" 74 "Lubrication System" 73 "Rollover Detection Control" 72 "Coolant Valve Controller" 71 "Transfer Case Control" 70 "Auxiliary Regeneration Device" 69 "Engine Emission Aftertreatement System" 68 "Aftertreatment system gas measurement" 67 "Electrical System Controller" 66 "I/O Controller" 65 "Gas Flow Measurement" 64 "Endurance Braking" 63 "Engine Valve Controller" 62 "On-Board Diagnostic Unit" 61 "File Server/Printer" 60 "Cab Display" 59 "Starter" 58 "Fan Drive Control" 57 "Steering Column Unit" 56 "Communications Unit, Radio" 55 "Communications Unit, Satellite" 54 "Communications Unit, Cellular" 53 "Alternator/Charging System" 52 "Chassis Controller" 51 "Forward-Looking Collision Warning System" 50 "Auxiliary Heater" 49 "Clutch/Converter Control" 48 "Ramp Control" 47 "Information System Controller" 46 "Oil Sensor Unit" 45 "Vehicle Dynamic Stability Control" 44 "Exhaust Emission Control" 43 "Transmission Display" ;
VAL_ 2365459710 ManufacturerCode 454 "NGK Spark Plug Co. Ltd" 453 "Cooper Bussmann" 452 "WIKA Alexander Wiegand SE & Co. KG" 451 "Parker Hannifin Corp" 450 "Dycor Technologies Ltd." 449 "Polaris Industries Inc" 448 "Stanadyne Corporation, Electronics Systems" 447 "Great Plains Mfg." 446 "CertTech, L.L.C." 445 "KAT MECHATRONIC, Electronic Product Division" 444 "ITT Power Solutions" 443 "SignalQuest, Inc." 442 "Horsch Maschinen GmbH" 441 "PTG Reifendruckregelsysteme GmbH" 440 "Cummins Power Generation" 439 "Hyundai Heavy Industries" 438 "Comar Systems Ltd" 437 "Digital Yacht Limited" 436 "Kinze Manufacturing" 435 "Zunhammer GmbH" 434 "Stored Energy Systems" 433 "Rowe Electronics" 432 "S&A Systems, Inc." 431 "Tohatsu Corporation" 430 "Auteq Telematica S.A." 520 "Trapeze" 519 "Peeters Landbouwmachines b.v." 518 "Transas USA Inc." 517 "Noland Engineering" 516 "AVAT Automation GmbH" 515 "GINAF Trucks Nederland B.V." 514 "DISTek Integration, Inc." 513 "FarmscanAg" 512 "Inpower LLC" 511 "Sulky" 510 "Marinesoft Co. Ltd" 509 "MOTORTECH GmbH" 508 "Transtech Innovations" 507 "Test Center ISOBUS" 506 "IHI STAR Machinery Corporation" 505 "Yetter Farm Equipment" 504 "Vesper Marine" 503 "Naviop S.R.L." 502 "Attwood Corporation" 501 "Agrotronix S.A." 500 "Oxbo International Corporation" 499 "LCJ Capteurs" 498 "Innovative Design Solutions, Inc" 497 "SENTRON Sistemas Embarcados" 496 "W. Gessmann GmbH" 495 "HOLMER Maschinenbau GmbH" 494 "Synerject" 493 "Watcheye" 492 "Inergy Automotive Systems" 491 "Penny and Giles Ltd" 490 "QuikQ" 489 "Appareo Systems" 488 "The Charles Machine Works, Inc." 487 "DSE Test Solutions A/S" 486 "Westport Innovations Inc." 485 "MATT automotive" 484 "Headsight Inc." 483 "Valeo" 482 "Tricon Electronics" 481 "Chetco Digital Instruments" 480 "EnerDel, Inc." 479 "Vapor Bus International" 478 "OceanSat BV" 477 "OilQuick AB" 476 "Hummingbird Marine Electronics" 475 "GME" 474 "Persen Technologies Inc." 473 "Boss Industries, Inc." 472 "Tenneco Inc." 471 "Sea Cross Marine AB" 470 "SI-TEX Marine Electronics" 469 "RA Consulting GmbH" 468 "Tyco Fire Protection Products" 467 "Lely Industries N.V." 466 "Veethree Electronics and Marine LLC" 465 "Ashcroft Inc" 464 "Leach International Corporation" 463 "PROBOTIQ" 462 "IHI Shibaura Machinery Corporation" 461 "HAWE Hydraulik SE" 460 "San Giorgio S.E.I.N." 459 "Alltek Marine Electronics Corp" 458 "Control Solutions, Inc." 457 "RUSELPROM-ElectricDrive Ltd" 456 "General Kinetics" 455 "ADZ NAGANO GmbH" 429 "Rota Engineering Ltd." 428 "Mfg_428" 427 "em-trak Marine Electronics Ltd" 426 "Egersund Marine Electronics AS" 425 "Methode Electronics Inc, MDI" 424 "Odyne LLC" 423 "BSM Wireless, Inc." 422 "True Heading AB" 421 "Vertex Standard Co, Ltd" 420 "Vermeer Corporation, ACS Group" 419 "Fusion Electronics Ltd" 418 "Intellistick Inc" 417 "KZValve" 416 "Kubota Corporation" 415 "Valid Manufacturing Ltd." 414 "Cattron Group International" 413 "Datapross Nijbroek bv" 412 "WebTech Wireless Inc." 411 "Hy-Drive Technologies Ltd." 410 "COBO S.p.A. Divisione 3B6" 409 "Transfluid S.r.L." 408 "Corvus Energy Ltd." 407 "Comtech Mobile Datacom" 406 "Vecima Networks Inc." 405 "Wema System AS" 404 "Com Nav Marine Ltd" 403 "Trackwell ADS, Inc." 402 "Simma Software, Inc." 401 "Torqeedo GmbH" 400 "Livorsi Marine" 399 "ISEKI & Co., Ltd." 398 "Hilite International" 397 "Sanyo-kiki Co Ltd." 396 "Beyond Measure" 395 "GENTEC S.R.L." 394 "Capi 2 Nederland BV" 393 "Harvest Tec, Inc" 392 "Tianyuan Technology Co Ltd." 391 "Electronic Design for Industry, Inc" 390 "Partech Inc." 389 "Benchmark Electronics, Minnesota Division" 388 "Innomatix, LLC" 387 "Orscheln Products, LLC" 386 "JLG Automation BVBA" 385 "Johnson Outdoor Marine Electronics" 384 "Camano Light" 383 "MCL Industries" 382 "National Agricultural and Food Research Organization" 380 "Suntech International Ltd." 379 "Yamabiko Corporation" 378 "Glendinning Marine Products" 377 "ifm electronic gmbh" 376 "Quake Global" 375 "Williams Controls Inc." 372 "Delphi" 381 "B&G" 374 "Northern Lights, Inc." 373 "Electronic Design Inc." 371 "Heinzmann GmbH & Co. KG" 370 "Rolls-Royce Marine AS" 369 "Power Torque Engineering Ltd" 368 "HANSENHOF_electronic" 367 "Fliegl Agrartechnik" 366 "Viewnyx Corp." 365 "Digi-Star, LLC" 364 "OEM Controls Inc." 363 "BEI Duncan" 362 "Alois Poettinger Maschinenfabrik GmbH" 361 "InMach" 360 "HJS Emission Technology GmbH & Co KG" 359 "Ludwig Bergmann GmbH" 358 "Victron Energy BV" 357 "Hardi International A/S" 356 "Fischer Panda Generators, Inc" 355 "Mastervolt International B.V." 354 "Junkkari OY" 353 "Hegemon Electronics, Inc." 352 "SAME DEUTZ-FAHR" 351 "Thrane & Thrane" 350 "Noris Marine Systems GmbH & Co KG" 349 "Suonentiet" 348 "Amazonen Werke H. Dreyer" 347 "Honeywell" 346 "Control Solutions" 345 "Korean Maritime University" 344 "Parvus Corporation" 343 "Baumer Group" 342 "THOMAS MAGNETE GmbH" 341 "Boning GmbH & Co" 340 "Continental AG" 339 "Competence Center ISOBUS e.V." 338 "GRAF-SYTECO" 337 "Carraro S.p.A." 336 "APE s.r.o." 335 "Evo Electric Ltd" 334 "Takata-Petri AG" 333 "Hadley Products Corporation" 332 "HWH Corporation" 331 "Horton, Inc." 330 "Kidde Aerospace and Defense" 329 "Deif A/S" 328 "Qwerty Electronik AB" 252 "Sensor-Technik Wiedemann GmbH" 251 "German Agricultural Society" 250 "Kuhn Group" 249 "Schaltbau GmbH" 233 "Yacht Monitoring Solutions Inc." 232 "TSD Integrated Controls" 1863 "Thomas G. Faria Co." 1862 "Sanshin" 1861 "Vector CANtech" 1860 "MMP" 1859 "Kvasar AB" 1858 "Litton" 1857 "Simrad" 1856 "Trimble" 1855 "Furuno USA" 1854 "Northstar Technologies" 1853 "Japan Radio Co." 1852 "Navionics" 1851 "Raymarine" 1850 "Teleflex" 222 "Generac Power Systems, Inc." 221 "SiE" 220 "Beede Electrical Instrument Company, Inc." 219 "Cat OEM Solutions" 218 "Gits Manufacturing Company" 217 "RM Michaelides Software & Elektronik GmbH" 216 "Paneltronics Inc." 215 "Aetna Engineering/Fireboy-Xintex" 214 "MC elettronica Srl" 213 "CNH Belgium N.V." 212 "Sure Power Industries, Inc." 211 "DNA Group" 210 "Iteris, Inc." 209 "Bell Equip. Co. SA (PTY) LTD" 208 "Drew Technologies, Inc." 207 "Otto Engineering" 206 "port GmbH" 205 "SmarTire Systems Inc" 204 "The Morey Corporation" 203 "MILtronik GmbH" 202 "Curtis Instruments, Inc." 201 "Disenos y Tecnologia S.A." 200 "MGM Brakes" 199 "Actia Corp." 198 "Mystic Valley Communications" 197 "Mechron Power Systems" 196 "LEMKEN GmbH & Co. KG" 195 "General Engine Products" 194 "TriMark Corporation" 193 "Nobletec" 192 "Floscan" 191 "XRS Corporation" 190 "Hella KGaA Hueck & Co." 189 "QUALCOMM" 188 "EMP Corp." 187 "Air-Weigh" 186 "Altronic, Inc." 185 "Beede Electrical Instrument Company" 184 "EIA Electronics" 183 "KDS Controls, Inc." 182 "Vehicle Systems Engineering B.V." 181 "Coretronics, Inc." 180 "Smart Power Systems" 179 "TeeJet Technologies Denmark" 178 "Siemens VDO Automotive AG" 177 "Diagnostic System Associates" 176 "Moritz Aerospace" 175 "Veris Technologies, Inc." 174 "AB Volvo Penta" 173 "Ryeso, Inc." 172 "Yanmar Marine USA" 171 "Wachendorff Elektronik GmbH & Co. KG" 170 "Computronics Corporation Ltd." 169 "Marlin Technologies Inc." 168 "Xantrex" 167 "JLG Industries Inc." 166 "Phoenix International" 165 "CPAC Systems AB" 164 "DaimlerChrysler Off-Highway" 163 "BRP Inc." 162 "Axiomatic Technologies" 161 "Offshore Systems (UK) Limited" 160 "Nido" 159 "NTech Industries Inc." 158 "Firestone Industrial Products Company" 157 "ISSPRO Inc." 156 "ITT Industries - Cannon" 155 "Vetronix Corporation" 154 "Westerbeke Corporation" 153 "Woodward, Industrial Controls Division" 152 "elobau GmbH & Co. KG" 151 "Raven Industries Inc. - Flow Controls Division" 150 "Fleetguard" 149 "Holset" 148 "Blue Water Data, Inc." 147 "Nautibus Electronic GmbH" 146 "Maxima Technologies" 145 "MurCal Controls" 144 "Mercury Marine" 143 "W. Gmeiner GmbH & Co." 142 "TRW Automotive (Commercial Steering Systems)" 141 "Thales Navigation Ltd." 140 "Lowrance Electronics, Inc." 139 "Caterpillar Trimble Control Technologies (CTCT), LLC" 138 "Georg Fritzmeier GmbH & Co. KG" 137 "Maretron" 136 "Komatsu Ltd." 135 "Airmar Technology Corporation" 134 "Iris Technology Ltd." 133 "Bucher Schoerling GmbH" 132 "Mulag-Fahrzeugwerk" 131 "ITT Industries" 130 "Nido - Universal Machines B.V." 129 "OMNEX Control Systems, Inc." 128 "Gerhard Duecker GmbH & Co. KG" 127 "Holland USA" 126 "Driver Tech" 125 "Nevada Automotive Test Center" 124 "Hydac Electronic" 123 "Basler Electric" 122 "FG Wilson (Engineering) Limited" 121 "HED (Hydro Electronic Devices, Inc.)" 120 "RDS Technology Ltd." 119 "IntegriNautics" 118 "Intron GmbH" 117 "HUSCO International" 116 "BEELINE Technologies" 115 "NACCO Materials Handling Group, Inc." 114 "EControls, Inc." 113 "Stress-Tek, Inc." 112 "MECALAC" 111 "Maschinenfabrik Bernard Krone GmbH" 110 "EPIQ Sensor-Nite" 109 "TeeJet Technologies Denmark" 108 "WTK-Elecktronik GmbH" 107 "Grimme Landmaschinen GmbH & Co. KG" 106 "BAE Systems Controls, Inc." 105 "Kiepe Elektrik GmbH & Co. KG" 104 "Claas Selbstfahrende Erntemaschinen GmbH" 103 "CLAAS Agrosystems GmbH & Co. KG" 102 "AGCO GmbH & Co." 101 "Sensoria" 100 "VDO Technik AG" 99 "International Transmissions Ltd (ITL)" 98 "Mueller-Elektronik GmbH & Co." 97 "Ag Leader Technology, Inc." 96 "Mech@tronic IT GmbH" 95 "Pacific Insight Electronics Corp." 94 "CNH Global N.V." 93 "Perkins Engines Company Ltd." 92 "Ag-Chem Equipment Co., Inc." 91 "BSG Bodensee Steuergeraete GmbH" 90 "Knorr-Bremse SfN GmbH" 89 "Kverneland Group, Electronics Division" 88 "Satloc Precision GPS" 87 "J.C. Bamford Excavators Ltd (JCB)" 86 "C.E. Niehoff & Company" 85 "Kohler Co." 84 "New Holland UK Limited" 83 "Bendix VORAD Technologies" 82 "Bobcat/Ingersoll-Rand" 81 "Fire Research Corp" 80 "Twin Disc, Inc." 79 "Daimler Benz AG - Engine Division (PBM)" 78 "Frank W. Murphy Manufacturing, Inc." 77 "Deere Power Systems Group" 76 "unused" 75 "Deere & Co. Agricultural Division" 74 "Eaton Axle-Brake Division" 73 "LeTourneau, Inc." 72 "Sisu Corporation" 71 "Vansco Electronics Ltd." 70 "Flex-Coil Limited" 69 "Trimble Navigation" 68 "Scania" 67 "Funk Manufacturing Company" 66 "John Deere Construction Equipment Division" 65 "MAN Nutzfahrzeuge AG" 64 "unused" 63 "ZF Industries Inc." 62 "Wabco" 61 "Volvo Truck Corp." 60 "Volvo Trucks North America Inc." 59 "VES Inc." 58 "SPX Corporation, OTC Division" 57 "Sauer-Danfoss Co." 56 "SAIC" 55 "Ryder System Inc." 54 "Meritor Wabco" 53 "Continental Automotive Systems US, Inc." 52 "Meritor Automotive, Inc." 51 "Robert Bosch GmbH" 50 "Robert Bosch Corp" 49 "RE America Inc." 48 "Pollak Alphabet" 47 "Phillips Semiconductor" 46 "Noregon Systems, Inc" 45 "PACCAR" 44 "Nippondenso Co. Ltd." 43 "International Truck and Engine Corp. Vehicle Electronics" 42 "International Truck and Engine Corp. Engine Electronics" 41 "Motorola Inc." 40 "Motorola AIEG Inc." 39 "Microfirm Inc." 38 "Micro Processor Systems Inc." 37 "Mack Trucks Inc." 36 "Lucas Ltd." 35 "Kenworth Truck Co." 34 "Kelsey Hayes Co." 33 "John Deere" 32 "Jacobs Vehicle Systems" 31 "J Pollak Corp." 30 "Isuzu Motors Ltd." 29 "Hino Motors Ltd." 28 "Grote Ind. Inc." 27 "GMC" 26 "General Motors Corp., Service Technology Group" 25 "Daimler Trucks North America LLC" 24 "Ford Motor Co., Vehicle Controls" 23 "Ford Motor Co., Heavy Truck" 22 "Ford Motor Co., Electronic Concepts $ Systems" 21 "Echilin Inc., Midland Brake Inc." 20 "Eaton Ltd" 19 "Eaton Corp. Trucking Info Services" 18 "Eaton Corp, Transmission Division" 17 "Eaton Corp. Res & Dev" 16 "Eaton Corp." 15 "Dickey-John Corp." 14 "Detroit Diesel Corporation" 13 "Delco Electronics" 12 "Deere & Company, Precision Farming" 11 "Dearborn Group Inc." 10 "Cummins Engine Co." 9 "Chrysler Corp." 8 "Caterpillar Inc." 7 "Case Corp." 6 "Berifors Electronics AB" 5 "AMP Inc." 4 "Ametek-Dixson" 3 "Ametek, US Gauge Division" 2 "Allison Transmission, GMC" 1 "Allied Signal Inc." 0 "Reserved" 231 "Topcon Positioning Systems, Inc." 230 "Saucon Technologies" 229 "Garmin International Inc." 228 "ZF Marine Electronics" 227 "Lykketronic A/S" 226 "Monaco Coach Corporation" 225 "SKF" 224 "EMMI Network, S.L." 223 "Vaueo Retarder Co., Ltd." 263 "IMMI" 262 "HydraForce, Inc" 261 "Red Dot Corporation" 260 "Reichhardt GmbH" 259 "Jetter AG" 258 "ARAG" 257 "Honda Motor Co., Ltd" 256 "Tyco Electronics AMP" 255 "MEAS France" 254 "GE Sensing" 253 "Mobile Control Systems" 298 "Holley Performance" 297 "Zonar Systems Inc" 296 "micro dynamics GmbH" 295 "BEP Marine" 294 "Grayhill Inc." 293 "Spyder Controls Corp." 292 "IKUSI - Angel Iglesias S.A." 291 "Groeneveld Transport Efficiency BV" 290 "Kuebler GmbH" 289 "Watlow" 288 "Mitsubishi FUSO Truck & Bus Corp." 287 "NTech Industries, Inc" 286 "Coelmo srl" 285 "Sea Recovery Corp" 284 "Mobile Tech Chile" 283 "CWF Hamilton & Co Ltd" 282 "Medallion Instrumentation Systems" 281 "Precision Governors LLC" 311 "Patrick Power Products" 310 "TECNORD srl" 309 "Krauss-Maffei Wegmann GmbH & Co. KG" 308 "Cyntrx" 307 "MBW Technologies" 306 "Sleipner Motor AB" 305 "NovAtel Inc" 304 "EmpirBus AB" 303 "CTS Corporation" 302 "Nissin Kogyo Co., LTD" 301 "Parker Hannifin (UK) Ltd FDE group" 300 "Systron Donner Automotive" 299 "Rauch Landmaschinen GmbH" 280 "Leica Geosystems Pty Ltd" 279 "Geometris LP" 278 "Takata Electronics" 277 "LHP Telematics" 276 "Aqua-Hot Heating Systems" 275 "Navico Egersund AS" 274 "LTW Technology Co., LTD" 273 "Active Research Limited" 272 "Gross Mechanical Laboratories, Inc" 327 "Sonceboz SA" 326 "Akron Brass Company" 325 "ASM Automation Sensorik Messtechnik GmbH" 324 "Snap-on Diagnostics" 323 "Mobileye Vision Technologies Ltd." 322 "MICHENKA s.r.o." 321 "Ultra Electronics, Electrics" 320 "Miedema Landbouwwerktuigenfabriek B.V." 319 "Cadec Global" 318 "SAT Plan" 317 "Navtronics Bvba" 316 "ITT Flow Control" 315 "Icom Incorporated" 314 "CSM GmbH" 313 "Ilmor Engineering, Inc" 312 "Lectronix, Inc." 271 "Cole Hersee" 270 "Tennant" 269 "Saft America Inc.,  Space & Defense Division" 268 "Accurate Technologies" 267 "Red Lion Controls, Inc" 266 "International Thermal Research Ltd" 265 "MTS Sensor Technologie GmbH" 264 "Autolync" 248 "Cooper Standard Automotive Active Systems Group" 247 "ePULSE" 246 "Class 1, Inc" 245 "Capstan Ag Systems, Inc." 244 "Techno-Matic" 243 "eRide, Inc." 242 "Kokusandenki Co. Ltd" 241 "Schneider Automation SAS " 240 "Vanair Mfg" 239 "May & Scofield Ltd" 238 "ZF Friedrichshafen AG" 237 "Agtron Enterprises Inc" 236 "Norac Systems International Inc" 235 "SailorMade Marine Telemetry - Tetra Technology Ltd." 234 "Mondial electronic GmbH" ;
VAL_ 2566847486 DrvlineRetarderOverheatIndicator 3 "Not available" 2 "Driveline Retarder Overheat Indicator is flashing" 1 "Driveline Retarder Overheat Indicator is on continuously" 0 "Driveline Retarder Overheat Indicator is off" ;
VAL_ 2631859966 SteerStraightAheadPosReset 3 "Not applicable" 2 "Reserved take no action" 1 "Reset" 0 "Take no action  Do not Reset" ;
VAL_ 2631859966 EngBuildHoursReset 2 "Reserved" 3 "Take no action" 1 "Reset" 0 "Do not reset" ;
VAL_ 2631859966 EngIgntCtrlMaintenanceHoursReset 3 "Take no action" 2 "Reserved" 1 "Reset" 0 "Do not reset" ;
VAL_ 2631859966 EngSprkPlgScndVltgeTrackingReset 3 "Take no action" 2 "Reserved" 1 "Reset" 0 "Do not reset" ;
VAL_ 2631859966 TripGroup2Proprietary 2 "Reserved" 3 "Not applicable" 1 "Reset" 0 "Take no action" ;
VAL_ 2631859966 TripGroup1 2 "Reserved" 3 "Not applicable" 1 "Reset" 0 "Take no action" ;
VAL_ 2566840830 RetarderLocation 15 "Not available" 14 "Other" 5 "Trailer Vehicle speed" 4 "Secondary Driveline Output Shaft rpm" 3 "Secondary Transmission Output Output Shaft rpm" 2 "Primary Transmission Input Engine rpm" 1 "Primary Engine Exhaust Brake Exhaust pressure" 0 "Primary Engine Compression Release Brake Engine rpm" ;
VAL_ 2566840830 RetarderType 15 "Not available" 14 "Other" 4 "Exhaust" 3 "Compression Release Engine retarder" 2 "Cooled Friction" 1 "Hydraulic" 0 "Electric/Magnetic" ;
VAL_ 2566844670 OprtrEngPTOGvrnrMmrySelectSwitch 3 "not available" 2 "error" 1 "PTO set speed memory 2 selected" 0 "PTO set speed memory 1 selected" ;
VAL_ 2566844670 EngRmtPTOGvrnrVrblSpedCtrlSwitch 3 "Not available" 2 "Error" 1 "On" 0 "Off" ;
VAL_ 2566844670 EngRmtPTOGvrnrPrprgrmmdSpdCtrlSw 3 "Not available" 2 "Error" 1 "On" 0 "Off" ;
VAL_ 2566844670 EngPTOGvrnrCast_DecelerateSwitch 3 "Not available" 2 "Error" 1 "On" 0 "Off" ;
VAL_ 2566844670 EngPTOGovernorSetSwitch 3 "Not available" 2 "Error" 1 "On" 0 "Off" ;
VAL_ 2566844670 EngPTOGovernorResumeSwitch 3 "Not available" 2 "Error" 1 "On" 0 "Off" ;
VAL_ 2566844670 EngPTOGovernorEnableSwitch 3 "Not available" 2 "Error" 1 "On" 0 "Off" ;
VAL_ 2566844670 EngPTOGovernorAccelerateSwitch 3 "Not available" 2 "Error" 1 "On" 0 "Off" ;
VAL_ 2566844670 RmtPTOGvrnrPrprgrmmdSpdCtrlSwtch 3 "Not Available" 2 "Error" 1 "On" 0 "Off" ;
VAL_ 2566844670 AuxInputIgnoreSwitch 3 "Not Available" 2 "Error" 1 "On" 0 "Off" ;
VAL_ 2566770174 RearWasherFunction 7 "Not available do not change" 3 "High" 2 "Medium" 1 "Low" 0 "Off" ;
VAL_ 2566770174 FrontOperatorWasherSwitch 7 "Not available do not change" 3 "High" 2 "Medium" 1 "Low" 0 "Off" ;
VAL_ 2566770174 FrontNonoperatorWasherSwitch 7 "Not available do not change" 3 "High" 2 "Medium" 1 "Low" 0 "Off" ;
VAL_ 2566770174 RearWiperSwitch 6 "Mist position where external sensor controls wiper rate" 5 "Delayed 2 used for the second delay choice when the wiper switch position controls the delay" 4 "Delayed 1 used for the first delay choice when the wiper switch position controls the delay" 2 "Medium" 15 "Not available do not change" 3 "High" 1 "Low" 0 "Off" ;
VAL_ 2566770174 FrontOperatorWiperSwitch 6 "Mist position where external sensor controls wiper rate" 5 "Delayed 2 used for the second delay choice when the wiper switch position controls the delay" 4 "Delayed 1 used for the first delay choice when the wiper switch position controls the delay" 2 "Medium" 15 "Not available do not change" 3 "High" 1 "Low" 0 "Off" ;
VAL_ 2566770174 FrontNonoperatorWiperSwitch 15 "Not available do not change" 6 "Mist position where external sensor controls wiper rate" 5 "Delayed 2 used for the second delay choice when the wiper switch position controls the delay" 4 "Delayed 1 used for the first delay choice when the wiper switch position controls the delay" 3 "High" 2 "Medium" 1 "Low" 0 "Off" ;
VAL_ 2566769662 EngAltDroopAuxInputSelect 15 "Not available" 14 "Error condition" 1 "thru 1101  One of Alternate Droop Setting 1 through 13 in sequential order is selected" 0 "Normal Droop Setting is selected" ;
VAL_ 2566769662 EngAltDroopRemoteAccelSelect 15 "Not available" 14 "Error condition" 1 "thru 1101  One of Alternate Droop Setting 1 through 13 in sequential order is selected" 0 "Normal Droop Setting is selected" ;
VAL_ 2566769662 EngAltDroopAccel2Select 15 "Not available" 14 "Error condition" 1 "thru 1101  One of Alternate Droop Setting 1 through 13 in sequential order is selected" 0 "Normal Droop Setting is selected" ;
VAL_ 2566769662 EngAltDroopAccel1Select 15 "Not available" 14 "Error condition" 1 "thru 1101  One of Alternate Droop Setting 1 through 13 in sequential order is selected" 0 "Normal Droop Setting is selected" ;
VAL_ 2566769662 EngAltRatingSelect 255 "Not available" 254 "Error condition." 3 "indicates that the Alternate Power Fueling 3 is selected" 2 "indicates that the Alternate Power Fueling 2 is selected" 1 "indicates that the Alternate Power Fueling 1 is selected" 0 "indicates that Maximum Power Fueling is selected" ;
VAL_ 2566769662 EngAltLowIdleSwitch 3 "Not available or Unused" 2 "Error" 1 "Alternate low idle point is selected" 0 "Default low idle point is selected" ;
VAL_ 2566769662 EngSynchronizationSwitch 3 "Not available or Unused" 2 "Error" 1 "Functionality is enabled on" 0 "Functionality is disabled off" ;
VAL_ 2566769662 EngAuxGovernorSwitch 2 "Error condition" 1 "Auxiliary Governor is enabled" 0 "Auxiliary Governor is disabled" 3 "Not available" ;
VAL_ 2566768638 EngAltDroopAuxInputSelectState 15 "Not available" 14 "SAE reserved" 1 "thru 1101  Control state is One of Alternate Droop Setting 1 through 13 in sequential order" 0 "Control state is Normal Droop Setting" ;
VAL_ 2566768638 EngAltDropRemoteAccelSelectState 15 "Not available" 14 "SAE reserved" 1 "thru 1101  Control state is One of Alternate Droop Setting 1 through 13 in sequential order" 0 "Control state is Normal Droop Setting" ;
VAL_ 2566768638 EngAltDroopAccel2SelectState 15 "Not available" 14 "SAE reserved" 1 "thru 1101  Controls state is One of Alternate Droop Setting 1 through 13 in sequential order" 0 "Controls state is Normal Droop Setting" ;
VAL_ 2566768638 EngAltDroopAccel1SelectState 15 "Not available" 14 "SAE reserved" 1 "thru 1101  Control state is one of Alternate Droop Setting 1 through 13 in sequential order" 0 "Control state is Normal Droop Setting" ;
VAL_ 2566768638 EngAltRatingSelectState 255 "Not available" 254 "SAE reserved" 3 "Control state is Alternate Power Fueling 3" 2 "Control state is Alternate Power Fueling 2 " 1 "Control state is Alternate Power Fueling 1 " 0 "Control state is Maximum Power Fueling" ;
VAL_ 2566768638 EngAltLowIdleSelectState 3 "not available" 2 "SAE reserved" 1 "Alternate idle state" 0 "Normal idle state" ;
VAL_ 2566768638 EngMultiUnitSyncState 3 "Not available" 2 "SAE reserved" 1 "Control State is Functionality enabled on" 0 "Control State is Functionality disabled off" ;
VAL_ 2566768638 EngAuxGovernorState 3 "Not available" 2 "SAE reserved" 1 "Control State is Auxiliary Governor enabled" 0 "Control State is Auxiliary Governor disabled" ;
VAL_ 2365443326 HighLowBeamSwitch 3 "Not available do not change" 2 "Error" 1 "High Beam Selected" 0 "Low Beam Selected" ;
VAL_ 2365443326 HazardLightSwitch 3 "Not available do not change" 2 "Error" 1 "Hazard Lamps to be Flashing" 0 "Hazard Lamps to be Off" ;
VAL_ 2365443326 TurnSignalSwitch 2 "Right turn to be Flashing" 15 "Not available do not change" 14 "Error to include both left and right selected simultaneously" 1 "Left Turn to be Flashing" 0 "No Turn being signaled" ;
VAL_ 2365443326 MainLightSwitch 8 "Delayed Off  The position by which the operator selects that a certain set of lamps are to come On and then are to" 2 "Headlight On  The position by which the operator selects that the headlamps are to be on" 15 "Not available do not change" 14 "Error" 3 "Headlight and Park On  The position by which the operator selects that Both the Headlamps and the Park lamps" 1 "Park On  The position by which the operator selects that the park lamps are to be on" 0 "Off  The position by which the operator selects that none of the lamps are to be on" ;
VAL_ 2365443326 WorkLightSwitch 4 "Work Light Combination 4 On  The position by which the operator selects that the lamps in the combination" 2 "Work Light Combination 2 On  The position by which the operator selects that the lamps in the combination" 15 "Not available do not change" 14 "Error" 3 "Work Light Combination 3 On  The position by which the operator selects that the lamps in the combination" 1 "Work Light Combination 1 On  The position by which the operator selects that the lamps in the combination" 0 "Off  The position by which the operator selects that none of the work lamps are to be on" ;
VAL_ 2566802686 BlackOutWorkLampSelect 3 "Not Supported" 2 "Reserved" 1 "On" 0 "Off" ;
VAL_ 2566802686 NightVisionIlluminatorSelect 3 "Not Supported" 2 "Reserved" 1 "On" 0 "Off" ;
VAL_ 2566802686 BlackOutBrake_StopLampSelect 3 "Not Supported" 2 "Reserved" 1 "On" 0 "Off" ;
VAL_ 2566802686 ConvoyDrivingLampSelect 3 "Not Supported" 2 "Reserved" 1 "On" 0 "Off" ;
VAL_ 2566802686 ConvoyLampSelect 3 "Not Supported" 2 "Reserved" 1 "On" 0 "Off" ;
VAL_ 2566802686 FrontBlackOutMarkerLampSelect 3 "Not Supported" 2 "Reserved" 1 "On" 0 "Off" ;
VAL_ 2566802686 RearBlackOutMarkerSelect 3 "Not Supported" 2 "Reserved" 1 "On" 0 "Off" ;
VAL_ 2566774014 SlowVesselModeStatus 3 "Take no action" 2 "Reserved" 1 "Slow vessel mode is ACTIVE" 0 "Slow vessel mode is OFF" ;
VAL_ 2566774014 TrollingModeStatus 3 "Take no action" 2 "Reserved" 1 "Trolling mode is ACTIVE" 0 "Trolling mode is OFF" ;
VAL_ 2566774014 EngThrttlSynchrnzationModeStatus 15 "Take no action" 4 "Synchronized Master" 3 "Synchronized Starboard" 2 "Synchronized Port" 1 "Synchronized Center" 0 "Not Synchronized" ;
VAL_ 2432595710 DisplayDeadbands 15 "Not Available" 2 "Wide  / 24mm" 1 "Standard  / 12mm" 0 "Narrow  / 45mm" ;
VAL_ 2432595710 LEDPatternCtrl 15 "Not Available" 2 "7 Channel" 1 "Offset" 0 "5 Channel" ;
VAL_ 2432595710 LEDDisplayDeadbandCtrl 15 "Not Available or Not applicable" 4 "/ 1 mm 0003 feet 004 inches" 3 "/ 5 mm 0017 feet 02 inches" 2 "/ 24 mm 0080 feet 096 inches" 1 "/ 12 mm 0040 feet 045 inches" 0 "/ 45 mm 0015 feet 018 inches" ;
VAL_ 2432595710 LEDDisplayModeCtrl 15 "Not Available or Not Applicable" 2 "Center OnGrade Display Mode 2  7 CHANNEL" 1 "Offset OnGrade Display Mode" 0 "Center OnGrade Display Mode 1  5 CHANNEL" ;
VAL_ 2432595710 LEDDisplayData1 255 "Not Available" 254 "Error" 159 "No data ie no laser strikes" 149 "High Coarse" 148 "High Medium/Coarse" 147 "High Medium" 146 "High Medium/Fine" 145 "High Fine" 144 "On Grade" 132 "Low Fine" 131 "Low Medium/Fine" 130 "Low Medium" 129 "Low Medium/Coarse" 128 "Low Coarse" 32 "Low Coarse LED on" 16 "Low Fine LED on" 8 "Ongrade LED on" 4 "High Fine LED on" 2 "High Coarse LED on" ;
VAL_ 2365486590 LaserReceiverType 4 "2.5 Meter Survey Receiver" 3 "2 Meter Survey Receiver" 2 "1 Meter Survey Receiver" 1 "Linear Laser Receiver" 0 "Reserved " ;
VAL_ 2365485566 LaserTracerInformation 32 "Curb 1  yes" 16 "Stringline 1  yes" 8 "Previous pass 1  yes" 4 "Valid target 1  yes" 2 "Laser is ready" 1 "Laser power is on" ;
VAL_ 2365485566 LEDDisplayData2 255 "Not Available" 254 "Error" 159 "No data ie no laser strikes" 149 "High Coarse" 148 "High Medium/Coarse" 147 "High Medium" 146 "High Medium/Fine" 145 "High Fine" 144 "On Grade" 132 "Low Fine" 131 "Low Medium/Fine" 130 "Low Medium" 129 "Low Medium/Coarse" 128 "Low Coarse" 64 "Right LED on" 32 "Left LED on" 16 "Down LED on" 8 "Up LED on" 4 "Ongrade C LED on" 2 "Ongrade B LED on" 1 "Ongrade A LED on" ;
